VERSION "HNNBNNNYNNNNNNNNNNNNNNNNNNNNNNNNNNNNNNNNNN/4/%%%/4/'%**4NNN///"

NS_ :

BS_:

BU_: Aero_LB AFS_MLB Airbag_B8 BCM1_B8 Gateway_B8 Getriebe_AL551_651_B8 Getriebe_AL551_Q5_Hybrid Getriebe_SL_LB Lift_MLB_LB LWR_MLB Magnetic_Ride_LB Motor_MLB_AU48_AU416_Diesel Motor_MLB_B8_Q5_Otto Motor_MLB_Q5_Hybrid Niveau_LB Airbag_D4 BMS_Hybrid Daempfer_MLB EPB_MLB ESP Gateway Getriebe_AL551_951_D4_C7 Getriebe_AL551_Hybrid_D4_C7 Getriebe_DL382_MLB Getriebe_DL501_MLB Getriebe_VL381_MLB LEH_Hybrid LWS_D4 Motor2_MLB_D4_C7 Motor_MLB_AU64_AU57_Diesel Motor_MLB_BY_Otto Motor_MLB_C7_PHEV Motor_MLB_D4_C7_Hybrid Motor_MLB_D4_C7_Otto QSP SAK SAK2 SCR_MLB SCU

BO_ 3221225472 VECTOR__INDEPENDENT_SIG_MSG: 0 Vector__XXX
 SG_ AGA_Charisma_FahrPr : 0|4@1+ (1,0) [0|15] "" Vector__XXX
 SG_ AGA_Charisma_Status : 0|2@1+ (1,0) [0|3] "" Vector__XXX
 SG_ AGA_Verstaerker_Mute : 0|1@1+ (1,0) [0|1] "" Vector__XXX
 SG_ TPS_Airbag_Data : 0|56@1+ (1,0) [0|7.20575940379279E+016] "" Vector__XXX

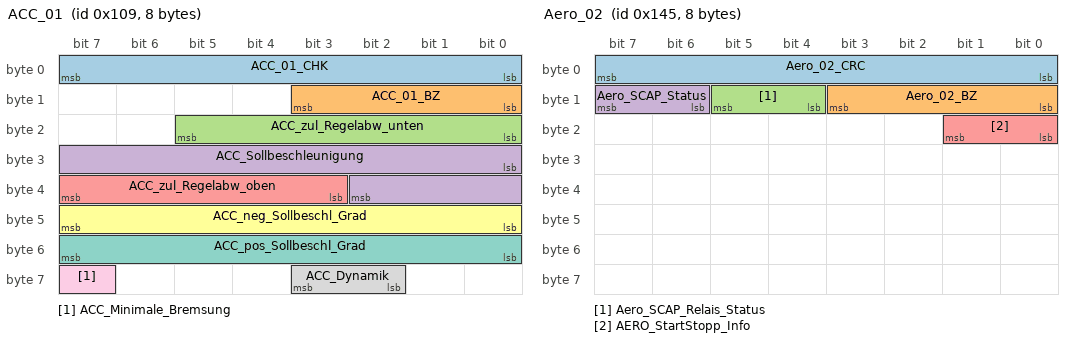
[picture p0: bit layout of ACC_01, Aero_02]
BO_ 265 ACC_01: 8 Gateway_B8
 SG_ ACC_01_CHK : 0|8@1+ (1,0) [0|255] ""  Magnetic_Ride_LB,Motor_MLB_AU48_AU416_Diesel,Motor_MLB_B8_Q5_Otto,Motor_MLB_Q5_Hybrid
 SG_ ACC_01_BZ : 8|4@1+ (1,0) [0|15] ""  Magnetic_Ride_LB,Motor_MLB_AU48_AU416_Diesel,Motor_MLB_B8_Q5_Otto,Motor_MLB_Q5_Hybrid
 SG_ ACC_zul_Regelabw_unten : 16|6@1+ (0.024,0) [0|1.512] "Unit_MeterPerSeconSquar"  Motor_MLB_AU48_AU416_Diesel,Motor_MLB_B8_Q5_Otto,Motor_MLB_Q5_Hybrid
 SG_ ACC_Sollbeschleunigung : 24|11@1+ (0.005,-7.22) [-7.22|3.01] "Unit_MeterPerSeconSquar"  Magnetic_Ride_LB,Motor_MLB_AU48_AU416_Diesel,Motor_MLB_B8_Q5_Otto,Motor_MLB_Q5_Hybrid
 SG_ ACC_zul_Regelabw_oben : 35|5@1+ (0.0625,0) [0|1.9375] "Unit_MeterPerSeconSquar"  Motor_MLB_AU48_AU416_Diesel,Motor_MLB_B8_Q5_Otto,Motor_MLB_Q5_Hybrid
 SG_ ACC_neg_Sollbeschl_Grad : 40|8@1+ (0.05,0) [0|12.7] "Unit_MeterPerCubicSecon"  Motor_MLB_AU48_AU416_Diesel,Motor_MLB_B8_Q5_Otto,Motor_MLB_Q5_Hybrid
 SG_ ACC_pos_Sollbeschl_Grad : 48|8@1+ (0.05,0) [0|12.7] "Unit_MeterPerCubicSecon"  Motor_MLB_AU48_AU416_Diesel,Motor_MLB_B8_Q5_Otto,Motor_MLB_Q5_Hybrid
 SG_ ACC_Dynamik : 58|2@1+ (1,0) [0|3] ""  Motor_MLB_AU48_AU416_Diesel,Motor_MLB_B8_Q5_Otto,Motor_MLB_Q5_Hybrid
 SG_ ACC_Minimale_Bremsung : 63|1@1+ (1,0) [0|1] ""  Motor_MLB_AU48_AU416_Diesel,Motor_MLB_B8_Q5_Otto,Motor_MLB_Q5_Hybrid

BO_ 1415 Aero_01: 8 Aero_LB
 SG_ Aero_01_CRC : 0|8@1+ (1,0) [0|255] ""  Gateway_B8
 SG_ Aero_01_BZ : 8|4@1+ (1,0) [0|15] ""  Gateway_B8
 SG_ Aero_Luftklappe_links_Status : 12|2@1+ (1,0) [0|3] ""  Gateway_B8
 SG_ Aero_Luftklappe_rechts_Status : 14|2@1+ (1,0) [0|3] ""  Gateway_B8
 SG_ Aero_Frontspoiler_Status : 16|3@1+ (1,0) [0|7] ""  Gateway_B8
 SG_ Aero_Heckspoiler_Status : 19|3@1+ (1,0) [0|7] ""  Gateway_B8
 SG_ Aero_SCU_Luefter_Status : 22|2@1+ (1,0) [0|3] ""  Gateway_B8
 SG_ Aero_Unterdruckpumpe_Status : 24|2@1+ (1,0) [0|3] ""  Gateway_B8
 SG_ Aero_Kamera_Kuehlung_Status : 26|1@1+ (1,0) [0|1] ""  Gateway_B8
 SG_ Aero_EBCS : 27|1@1+ (1,0) [0|1] ""  Gateway_B8
 SG_ Aero_Hardtop_Links_Status : 28|2@1+ (1,0) [0|3] ""  Gateway_B8
 SG_ Aero_Hardtop_Rechts_Status : 30|2@1+ (1,0) [0|3] ""  Gateway_B8
 SG_ Aero_Max_Performance : 32|2@1+ (1,0) [0|3] ""  Gateway_B8
 SG_ Aero_SCAP_Text : 34|2@1+ (1,0) [0|3] ""  Gateway_B8
 SG_ Aero_Frontklappe : 36|1@1+ (1,0) [0|1] ""  Gateway_B8
 SG_ AERO_St_LED_HSpoiler : 37|2@1+ (1,0) [0|3] ""  Gateway_B8
 SG_ Aero_Sp_IstPos : 39|3@1+ (1,0) [0|7] ""  Gateway_B8
 SG_ AERO_W_SpoilerInfo : 42|3@1+ (1,0) [0|7] ""  Gateway_B8
 SG_ Aero_KD_Fehler : 63|1@1+ (1,0) [0|1] ""  Gateway_B8

BO_ 325 Aero_02: 8 Aero_LB
 SG_ Aero_02_CRC : 0|8@1+ (1,0) [0|255] ""  Motor_MLB_B8_Q5_Otto
 SG_ Aero_02_BZ : 8|4@1+ (1,0) [0|15] ""  Motor_MLB_B8_Q5_Otto
 SG_ Aero_SCAP_Relais_Status : 12|2@1+ (1,0) [0|3] ""  Motor_MLB_B8_Q5_Otto
 SG_ Aero_SCAP_Status : 14|2@1+ (1,0) [0|3] ""  Motor_MLB_B8_Q5_Otto
 SG_ AERO_StartStopp_Info : 16|2@1+ (1,0) [0|3] ""  Motor_MLB_B8_Q5_Otto

BO_ 867 Blinkmodi_01: 4 Gateway_B8
 SG_ BM_ZV_auf : 0|1@1+ (1,0) [0|1] "" Vector__XXX
 SG_ BM_ZV_zu : 1|1@1+ (1,0) [0|1] "" Vector__XXX
 SG_ BM_DWA_ein : 2|1@1+ (1,0) [0|1] "" Vector__XXX
 SG_ BM_DWA_Alarm : 3|1@1+ (1,0) [0|1] "" Vector__XXX
 SG_ BM_Crash : 4|1@1+ (1,0) [0|1] "" Vector__XXX
 SG_ BM_Panik : 5|1@1+ (1,0) [0|1] "" Vector__XXX
 SG_ BM_Not_Bremsung : 6|1@1+ (1,0) [0|1] "" Vector__XXX
 SG_ BM_GDO : 7|1@1+ (1,0) [0|1] "" Vector__XXX
 SG_ BM_links : 8|1@1+ (1,0) [0|1] "" Vector__XXX
 SG_ BM_rechts : 9|1@1+ (1,0) [0|1] "" Vector__XXX
 SG_ BM_Warnblinken : 10|1@1+ (1,0) [0|1] "" Vector__XXX
 SG_ BM_Taxi_Notalarm : 12|1@1+ (1,0) [0|1] "" Vector__XXX
 SG_ BM_Telematik : 13|1@1+ (1,0) [0|1] "" Vector__XXX
 SG_ BM_HD_Oeffnung_angelernt : 14|1@1+ (1,0) [0|1] "" Vector__XXX
 SG_ BM_WBT_Beleuchtung : 15|1@1+ (1,0) [0|1] "" Vector__XXX
 SG_ Blinken_li_Fzg_Takt : 16|1@1+ (1,0) [0|1] "" Vector__XXX
 SG_ Blinken_re_Fzg_Takt : 17|1@1+ (1,0) [0|1] "" Vector__XXX
 SG_ Blinken_li_Kombi_Takt : 18|1@1+ (1,0) [0|1] "" Vector__XXX
 SG_ Blinken_re_Kombi_Takt : 19|1@1+ (1,0) [0|1] "" Vector__XXX
 SG_ BM_NBA_n_codiert_n_aktiv : 20|1@1+ (1,0) [0|1] "" Vector__XXX
 SG_ BM_NBA_Status : 21|2@1+ (1,0) [0|3] "" Vector__XXX
 SG_ Blinken_FWB_aktiv : 23|1@1+ (1,0) [0|1] "" Vector__XXX

BO_ 264 Fahrwerk_01: 8 Daempfer_MLB
 SG_ Fahrwerk_01_CHK : 0|8@1+ (1,0) [0|255] ""  BCM1_B8,Gateway_B8
 SG_ Fahrwerk_01_BZ : 8|4@1+ (1,0) [0|15] ""  BCM1_B8,Gateway_B8
 SG_ FA_Hoehenwerte_kalibriert M : 12|1@1+ (1,0) [0|1] ""  AFS_MLB,BCM1_B8,Gateway_B8,LWR_MLB
 SG_ FA_ESP_Zuschaltung : 13|1@1+ (1,0) [0|1] ""  Gateway_B8
 SG_ FA_Hoehenwert_VL_00 m0 : 16|8@1+ (1,-127) [-127|126] "Unit_MilliMeter"  AFS_MLB,BCM1_B8,Gateway_B8,LWR_MLB
 SG_ FA_Hoehenwert_VL_01 m1 : 16|8@1+ (0.4,0) [0|100] "Unit_PerCent"  AFS_MLB,BCM1_B8,Gateway_B8,LWR_MLB
 SG_ FA_Hoehenwert_VR_00 m0 : 24|8@1+ (1,-127) [-127|126] "Unit_MilliMeter"  AFS_MLB,BCM1_B8,Gateway_B8,LWR_MLB
 SG_ FA_Hoehenwert_VR_01 m1 : 24|8@1+ (0.4,0) [0|100] "Unit_PerCent"  AFS_MLB,BCM1_B8,Gateway_B8,LWR_MLB
 SG_ FA_Hoehenwert_HL_00 m0 : 32|8@1+ (1,-127) [-127|126] "Unit_MilliMeter"  AFS_MLB,BCM1_B8,Gateway_B8,LWR_MLB
 SG_ FA_Hoehenwert_HL_01 m1 : 32|8@1+ (0.4,0) [0|100] "Unit_PerCent"  AFS_MLB,BCM1_B8,Gateway_B8,LWR_MLB
 SG_ FA_Hoehenwert_HR_00 m0 : 40|8@1+ (1,-127) [-127|126] "Unit_MilliMeter"  AFS_MLB,BCM1_B8,Gateway_B8,LWR_MLB
 SG_ FA_Hoehenwert_HR_01 m1 : 40|8@1+ (0.4,0) [0|100] "Unit_PerCent"  AFS_MLB,BCM1_B8,Gateway_B8,LWR_MLB

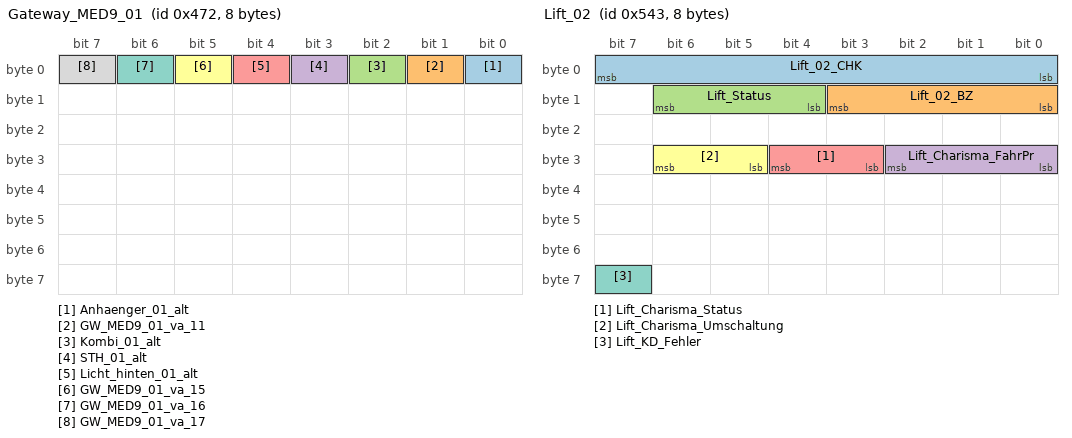
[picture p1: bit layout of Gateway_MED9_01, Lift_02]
BO_ 1138 Gateway_MED9_01: 8 Gateway_B8
 SG_ Anhaenger_01_alt : 0|1@1+ (1,0) [0|1] "" Vector__XXX
 SG_ GW_MED9_01_va_11 : 1|1@1+ (1,0) [0|1] "" Vector__XXX
 SG_ Kombi_01_alt : 2|1@1+ (1,0) [0|1] "" Vector__XXX
 SG_ STH_01_alt : 3|1@1+ (1,0) [0|1] "" Vector__XXX
 SG_ Licht_hinten_01_alt : 4|1@1+ (1,0) [0|1] "" Vector__XXX
 SG_ GW_MED9_01_va_15 : 5|1@1+ (1,0) [0|1] "" Vector__XXX
 SG_ GW_MED9_01_va_16 : 6|1@1+ (1,0) [0|1] "" Vector__XXX
 SG_ GW_MED9_01_va_17 : 7|1@1+ (1,0) [0|1] "" Vector__XXX

BO_ 1906 ISO_Daempfer_Req: 8 Gateway_B8
 SG_ ISO_Daempfer_Req_Data : 0|64@1+ (1,0) [0|1.84467440737096E+019] ""  Magnetic_Ride_LB

BO_ 2012 ISO_Daempfer_Resp: 8 Magnetic_Ride_LB
 SG_ ISO_Daempfer_Resp_Data : 0|64@1+ (1,0) [0|1.84467440737096E+019] ""  Gateway_B8

BO_ 1876 ISO_LWRAFS_Req: 8 Gateway_B8
 SG_ ISO_LWRAFS_Req_Data : 0|64@1+ (1,0) [0|1.84467440737096E+019] ""  LWR_MLB

BO_ 1982 ISO_LWRAFS_Resp: 8 LWR_MLB
 SG_ ISO_LWRAFS_Resp_Data : 0|64@1+ (1,0) [0|1.84467440737096E+019] ""  Gateway_B8

BO_ 2019 ISO_OBD_02_Req: 8 Gateway_B8
 SG_ ISO_OBD_02_Req_Data : 0|64@1+ (1,0) [0|1.84467440737096E+019] "" Vector__XXX

BO_ 2027 ISO_OBD_02_Resp: 8 Vector__XXX
 SG_ ISO_OBD_02_Resp_Data : 0|64@1+ (1,0) [0|1.84467440737096E+019] ""  Gateway_B8

BO_ 2023 ISO_OBD_06_Req: 8 Gateway_B8
 SG_ ISO_OBD_06_Req_Data : 0|64@1+ (1,0) [0|1.84467440737096E+019] "" Vector__XXX

BO_ 2031 ISO_OBD_06_Resp: 8 Vector__XXX
 SG_ ISO_OBD_06_Resp_Data : 0|64@1+ (1,0) [0|1.84467440737096E+019] ""  Gateway_B8

BO_ 1347 Lift_02: 8 Lift_MLB_LB
 SG_ Lift_02_CHK : 0|8@1+ (1,0) [0|255] ""  Gateway_B8
 SG_ Lift_02_BZ : 8|4@1+ (1,0) [0|15] ""  Gateway_B8
 SG_ Lift_Status : 12|3@1+ (1,0) [0|7] ""  Gateway_B8
 SG_ Lift_Charisma_FahrPr : 24|3@1+ (1,0) [0|7] ""  Gateway_B8
 SG_ Lift_Charisma_Status : 27|2@1+ (1,0) [0|3] ""  Gateway_B8
 SG_ Lift_Charisma_Umschaltung : 29|2@1+ (1,0) [0|3] ""  Gateway_B8
 SG_ Lift_KD_Fehler : 63|1@1+ (1,0) [0|1] ""  Gateway_B8

BO_ 917 LWR_AFS_01: 8 AFS_MLB
 SG_ AFS_Abbiegelicht_li_Anf : 0|1@1+ (1,0) [0|1] ""  Gateway_B8
 SG_ AFS_Abbiegelicht_re_Anf : 1|1@1+ (1,0) [0|1] ""  Gateway_B8
 SG_ AFS_Abbiegelicht_Dimm_Anf : 2|1@1+ (1,0) [0|1] ""  Gateway_B8
 SG_ AFS_Verfuegbarkeit_GLW : 3|1@1+ (1,0) [0|1] ""  Gateway_B8
 SG_ AFS_Status_adaptive_LV : 4|1@1+ (1,0) [0|1] ""  Gateway_B8
 SG_ AFS_Fernlicht_li_defekt : 5|1@1+ (1,0) [0|1] ""  Gateway_B8
 SG_ AFS_Fernlicht_re_defekt : 6|1@1+ (1,0) [0|1] ""  Gateway_B8
 SG_ AFS_Fernlicht_Status : 7|1@1+ (1,0) [0|1] ""  Gateway_B8
 SG_ LWR_AFS_01_BZ : 8|4@1+ (1,0) [0|15] ""  Gateway_B8
 SG_ AFS_Lampe : 12|1@1+ (1,0) [0|1] ""  Gateway_B8
 SG_ LWR_Lampe : 13|1@1+ (1,0) [0|1] ""  Gateway_B8
 SG_ AFS_Fehlertext : 14|1@1+ (1,0) [0|1] ""  Gateway_B8
 SG_ AFS_LED_Blinkmode : 15|1@1+ (1,0) [0|1] ""  Gateway_B8
 SG_ LWR_Touristenmodus_aktiv : 16|1@1+ (1,0) [0|1] ""  Gateway_B8
 SG_ AFS_Charisma_FahrPr : 17|3@1+ (1,0) [0|7] ""  Gateway_B8
 SG_ AFS_Charisma_Status : 20|2@1+ (1,0) [0|3] ""  Gateway_B8
 SG_ AFS_Charisma_Umschaltung : 22|2@1+ (1,0) [0|3] ""  Gateway_B8
 SG_ AFS_Allwetterlicht : 24|1@1+ (1,0) [0|1] ""  Gateway_B8
 SG_ LWR_Touristenmodus_verbaut : 25|1@1+ (1,0) [0|1] ""  Gateway_B8
 SG_ AFS_adaptive_LV_verbaut : 26|1@1+ (1,0) [0|1] ""  Gateway_B8
 SG_ LWR_Reisemodus_Texte : 27|2@1+ (1,0) [0|3] ""  Gateway_B8
 SG_ GLW_Sensor_blockiert : 29|1@1+ (1,0) [0|1] ""  Gateway_B8
 SG_ LWR_Pos_Schrittmotor : 32|8@1+ (0.4,0) [0|100] "Unit_PerCent"  Gateway_B8
 SG_ LWR_Hoehenwert_VL : 40|8@1+ (1,-127) [-127|126] ""  Gateway_B8
 SG_ LWR_Hoehenwert_HL : 48|8@1+ (1,-127) [-127|126] ""  Gateway_B8
 SG_ AFS_Ersatzlicht_Links : 56|1@1+ (1,0) [0|1] ""  Gateway_B8
 SG_ AFS_Ersatzlicht_Rechts : 57|1@1+ (1,0) [0|1] ""  Gateway_B8
 SG_ LWR_AFS_Grundeinstellung : 58|1@1+ (1,0) [0|1] ""  Gateway_B8
 SG_ LWR_AFS_Parametrisierung : 59|1@1+ (1,0) [0|1] ""  Gateway_B8
 SG_ LWR_Initialisierungslauf : 60|1@1+ (1,0) [0|1] ""  Gateway_B8
 SG_ LWR_Sicherheitsposition : 61|1@1+ (1,0) [0|1] ""  Gateway_B8
 SG_ LWR_Modus : 62|1@1+ (1,0) [0|1] ""  Gateway_B8
 SG_ LWR_KD_Fehler : 63|1@1+ (1,0) [0|1] ""  Gateway_B8

BO_ 1759 NMH_Aero: 7 Aero_LB
 SG_ NMH_Aero_Start_1 : 0|1@1+ (1,0) [0|1] ""  Aero_LB,Getriebe_AL551_651_B8,Getriebe_AL551_Q5_Hybrid,Getriebe_SL_LB,Motor_MLB_AU48_AU416_Diesel,Motor_MLB_B8_Q5_Otto,Motor_MLB_Q5_Hybrid
 SG_ NMH_Aero_Start_2 : 1|1@1+ (1,0) [0|1] "" Vector__XXX
 SG_ NMH_Aero_Normal_Mode_1 : 2|1@1+ (1,0) [0|1] "" Vector__XXX
 SG_ NMH_Aero_Normal_Mode_2 : 3|1@1+ (1,0) [0|1] "" Vector__XXX
 SG_ NMH_Aero_Car_WakeUp : 6|1@1+ (1,0) [0|1] ""  Gateway_B8
 SG_ NMH_Aero_Per_WakeUp : 8|5@1+ (1,0) [0|31] "" Vector__XXX
 SG_ NMH_Aero_Fkt_WakeUp : 13|3@1+ (1,0) [0|7] "" Vector__XXX
 SG_ NMH_Aero_Klemme_15 : 16|1@1+ (1,0) [0|1] "" Vector__XXX
 SG_ NMH_Aero_Diagnose : 17|1@1+ (1,0) [0|1] "" Vector__XXX
 SG_ NMH_Aero_MindestAktivZeit : 18|1@1+ (1,0) [0|1] "" Vector__XXX
 SG_ NMH_Aero_NL_Datem_EEPROM : 24|1@1+ (1,0) [0|1] "" Vector__XXX
 SG_ NMH_Aero_Signalfehler : 32|1@1+ (1,0) [0|1] "" Vector__XXX
 SG_ NMH_Aero_TimeOut_Fehler : 33|1@1+ (1,0) [0|1] "" Vector__XXX
 SG_ NMH_Aero_CAN_Diag_deaktiv : 34|1@1+ (1,0) [0|1] "" Vector__XXX
 SG_ NMH_Aero_KompSchutz : 35|1@1+ (1,0) [0|1] "" Vector__XXX
 SG_ NMH_Aero_Mute_Mode : 36|1@1+ (1,0) [0|1] "" Vector__XXX
 SG_ NMH_Aero_Transport_Mode : 37|1@1+ (1,0) [0|1] "" Vector__XXX
 SG_ NMH_Aero_Abschaltstufe_aktiv : 38|1@1+ (1,0) [0|1] "" Vector__XXX
 SG_ NMH_Aero_Busfehler : 39|1@1+ (1,0) [0|1] "" Vector__XXX
 SG_ NMH_Aero_Lokalaktiv : 48|1@1+ (1,0) [0|1] ""  Gateway_B8
 SG_ NMH_Aero_Subsystemaktiv : 49|1@1+ (1,0) [0|1] ""  Gateway_B8

BO_ 1193 TPD_Aerodynamik_01: 8 Gateway_B8
 SG_ TPD_Aerodynamik_Data_1 : 0|64@1+ (1,0) [0|1.84467440737096E+019] ""  Aero_LB

BO_ 1300 TPD_Airbag_02: 8 Gateway_B8
 SG_ TPD_Airbag_Data_2 : 0|64@1+ (1,0) [0|1.84467440737096E+019] ""  Airbag_B8

BO_ 1215 TPD_Gateway_01: 8 Airbag_B8
 SG_ TPD_Gateway_Data_1 : 0|64@1+ (1,0) [0|1.84467440737096E+019] ""  Gateway_B8

BO_ 1303 TPD_Gateway_02: 8 Airbag_B8
 SG_ TPD_Gateway_Data_2 : 0|64@1+ (1,0) [0|1.84467440737096E+019] ""  Gateway_B8

BO_ 1186 TPD_Getriebe_01: 8 Gateway_B8
 SG_ TPD_Getriebe_Data_1 : 0|64@1+ (1,0) [0|1.84467440737096E+019] ""  Getriebe_SL_LB

BO_ 1194 TPD_Lifting: 8 Gateway_B8
 SG_ TPD_Lifting_Data : 0|64@1+ (1,0) [0|1.84467440737096E+019] ""  Lift_MLB_LB

BO_ 1190 TPD_LWR_AFS_01: 8 Gateway_B8
 SG_ TPD_LWR_AFS_Data_1 : 0|64@1+ (1,0) [0|1.84467440737096E+019] ""  AFS_MLB,LWR_MLB

BO_ 1185 TPD_Motor_01: 8 Gateway_B8
 SG_ TPD_Motor_Data_1 : 0|64@1+ (1,0) [0|1.84467440737096E+019] "" Vector__XXX

BO_ 1205 TPD_MotorS_01: 8 Gateway_B8
 SG_ TPD_MotorS_Data_1 : 0|64@1+ (1,0) [0|1.84467440737096E+019] "" Vector__XXX

BO_ 535 TPS_Aerodynamik: 7 Aero_LB
 SG_ TPS_Aerodynamik_Data : 0|56@1+ (1,0) [0|7.20575940379279E+016] ""  Gateway_B8

BO_ 543 TPS_Gateway: 7 Gateway_B8
 SG_ TPS_Gateway_Data : 0|56@1+ (1,0) [0|7.20575940379279E+016] ""  Airbag_B8

BO_ 514 TPS_Getriebe: 7 Getriebe_DL501_MLB
 SG_ TPS_Getriebe_Data : 0|56@1+ (1,0) [0|7.20575940379279E+016] ""  Gateway_B8

BO_ 539 TPS_Lifting: 7 Lift_MLB_LB
 SG_ TPS_Lifting_Data : 0|56@1+ (1,0) [0|7.20575940379279E+016] ""  Gateway_B8

BO_ 518 TPS_LWR_AFS: 7 AFS_MLB
 SG_ TPS_LWR_AFS_Data : 0|56@1+ (1,0) [0|7.20575940379279E+016] ""  Gateway_B8

BO_ 513 TPS_Motor: 7 Vector__XXX
 SG_ TPS_Motor_Data : 0|56@1+ (1,0) [0|7.20575940379279E+016] ""  Gateway_B8

BO_ 533 TPS_MotorS: 7 Vector__XXX
 SG_ TPS_MotorS_Data : 0|56@1+ (1,0) [0|7.20575940379279E+016] ""  Gateway_B8

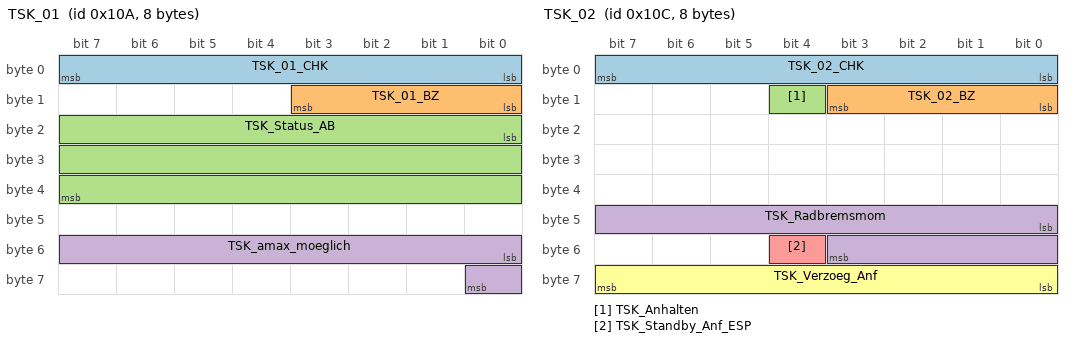
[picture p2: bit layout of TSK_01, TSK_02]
BO_ 266 TSK_01: 8 Motor_MLB_AU48_AU416_Diesel
 SG_ TSK_01_CHK : 0|8@1+ (1,0) [0|255] ""  Gateway_B8
 SG_ TSK_01_BZ : 8|4@1+ (1,0) [0|15] ""  Gateway_B8
 SG_ TSK_Status_AB : 16|24@1+ (1,0) [0|16777215] ""  Gateway_B8
 SG_ TSK_amax_moeglich : 48|9@1+ (0.024,-2.016) [-2.016|10.224] "Unit_MeterPerSeconSquar"  Gateway_B8

BO_ 268 TSK_02: 8 Motor_MLB_AU48_AU416_Diesel
 SG_ TSK_02_CHK : 0|8@1+ (1,0) [0|255] ""  Gateway_B8,Getriebe_AL551_651_B8,Getriebe_AL551_Q5_Hybrid,Getriebe_SL_LB
 SG_ TSK_02_BZ : 8|4@1+ (1,0) [0|15] ""  Gateway_B8,Getriebe_AL551_651_B8,Getriebe_AL551_Q5_Hybrid,Getriebe_SL_LB
 SG_ TSK_Anhalten : 12|1@1+ (1,0) [0|1] ""  Gateway_B8
 SG_ TSK_Radbremsmom : 40|12@1+ (8,0) [0|32760] "Unit_NewtoMeter"  Gateway_B8
 SG_ TSK_Standby_Anf_ESP : 52|1@1+ (1,0) [0|1] ""  Gateway_B8
 SG_ TSK_Verzoeg_Anf : 56|8@1+ (0.024,-3.984) [-3.984|2.112] "Unit_MeterPerSeconSquar"  Gateway_B8

BO_ 983 VSG_01: 8 Aero_LB
 SG_ VS_FH_FT_hoch : 0|1@1+ (1,0) [0|1] ""  Gateway_B8
 SG_ VS_FH_FT_Langhub : 1|1@1+ (1,0) [0|1] ""  Gateway_B8
 SG_ VS_FH_BT_hoch : 2|1@1+ (1,0) [0|1] ""  Gateway_B8
 SG_ VS_FH_BT_Langhub : 3|1@1+ (1,0) [0|1] ""  Gateway_B8
 SG_ VS_FH_HL_hoch : 4|1@1+ (1,0) [0|1] ""  Gateway_B8
 SG_ VS_FH_HL_Langhub : 5|1@1+ (1,0) [0|1] ""  Gateway_B8
 SG_ VS_FH_HR_hoch : 6|1@1+ (1,0) [0|1] ""  Gateway_B8
 SG_ VS_FH_HR_Langhub : 7|1@1+ (1,0) [0|1] ""  Gateway_B8
 SG_ VS_KD_Fehler : 15|1@1+ (1,0) [0|1] ""  Gateway_B8
 SG_ VS_VD_zu_ver : 16|1@1+ (1,0) [0|1] ""  Gateway_B8
 SG_ VS_VD_entriegelt : 17|1@1+ (1,0) [0|1] ""  Gateway_B8
 SG_ VS_VD_offen_ver : 18|1@1+ (1,0) [0|1] ""  Gateway_B8
 SG_ VS_VD_Zwischenposition : 19|1@1+ (1,0) [0|1] ""  Gateway_B8
 SG_ VS_VD_Bew_auf : 20|1@1+ (1,0) [0|1] ""  Gateway_B8
 SG_ VS_VD_Bew_zu : 21|1@1+ (1,0) [0|1] ""  Gateway_B8
 SG_ VS_Verdeck_Anf : 22|1@1+ (1,0) [0|1] ""  Gateway_B8
 SG_ VS_Hardtop : 23|1@1+ (1,0) [0|1] ""  Gateway_B8
 SG_ VS_VD_Fehler : 24|1@1+ (1,0) [0|1] ""  Gateway_B8
 SG_ VS_Lampe_Blk : 25|1@1+ (1,0) [0|1] ""  Gateway_B8
 SG_ VS_Buzzer : 26|1@1+ (1,0) [0|1] ""  Gateway_B8
 SG_ VS_HD_sperren : 27|1@1+ (1,0) [0|1] ""  Gateway_B8
 SG_ VS_HHS_enable : 28|1@1+ (1,0) [0|1] ""  Gateway_B8
 SG_ VS_VVW_unten : 29|1@1+ (1,0) [0|1] ""  Gateway_B8
 SG_ VSG_FT_FH_BT_ManHoch : 32|1@1+ (1,0) [0|1] ""  Gateway_B8
 SG_ VSG_FT_FH_BT_AutoHoch : 33|1@1+ (1,0) [0|1] ""  Gateway_B8
 SG_ VSG_FT_FH_BT_ManTief : 34|1@1+ (1,0) [0|1] ""  Gateway_B8
 SG_ VSG_FT_FH_BT_AutoTief : 35|1@1+ (1,0) [0|1] ""  Gateway_B8
 SG_ VSG_FT_FH_FT_ManHoch : 36|1@1+ (1,0) [0|1] ""  Gateway_B8
 SG_ VSG_FT_FH_FT_AutoHoch : 37|1@1+ (1,0) [0|1] ""  Gateway_B8
 SG_ VSG_FT_FH_FT_ManTief : 38|1@1+ (1,0) [0|1] ""  Gateway_B8
 SG_ VSG_FT_FH_FT_AutoTief : 39|1@1+ (1,0) [0|1] ""  Gateway_B8
 SG_ VSG_FT_FH_HL_ManHoch : 40|1@1+ (1,0) [0|1] ""  Gateway_B8
 SG_ VSG_FT_FH_HL_AutoHoch : 41|1@1+ (1,0) [0|1] ""  Gateway_B8
 SG_ VSG_FT_FH_HL_ManTief : 42|1@1+ (1,0) [0|1] ""  Gateway_B8
 SG_ VSG_FT_FH_HL_AutoTief : 43|1@1+ (1,0) [0|1] ""  Gateway_B8
 SG_ VSG_FT_FH_HR_ManHoch : 44|1@1+ (1,0) [0|1] ""  Gateway_B8
 SG_ VSG_FT_FH_HR_AutoHoch : 45|1@1+ (1,0) [0|1] ""  Gateway_B8
 SG_ VSG_FT_FH_HR_ManTief : 46|1@1+ (1,0) [0|1] ""  Gateway_B8
 SG_ VSG_FT_FH_HR_AutoTief : 47|1@1+ (1,0) [0|1] ""  Gateway_B8
 SG_ VS_Texte : 56|8@1+ (1,0) [0|255] ""  Gateway_B8

BO_ 912 WBA_01: 4 Getriebe_AL551_651_B8
 SG_ WBA_WH_Sleep_ACK_alt m0 : 7|1@1+ (1,0) [0|1] ""  Gateway_B8
 SG_ GE_Warnung_Auto_N_LB m0 : 18|1@1+ (1,0) [0|1] ""  Gateway_B8
 SG_ WBA_GE_Fastshift m0 : 19|1@1+ (1,0) [0|1] ""  Gateway_B8
 SG_ WBA_GE_Textmeldungen m0 : 21|3@1+ (1,0) [0|7] ""  Gateway_B8

BO_ 2617009149 XCP_Daempfer_CRO_01: 8 Vector__XXX
 SG_ XCP_Daempfer_CRO_01_Data : 0|64@1+ (1,0) [0|1.84467440737096E+019] ""  Magnetic_Ride_LB,Niveau_LB

BO_ 2617009150 XCP_Daempfer_DTO_01: 8 Daempfer_MLB
 SG_ XCP_Daempfer_DTO_01_Data : 0|64@1+ (1,0) [0|1.84467440737096E+019] "" Vector__XXX

BO_ 2617167360 XCP_Lift_CRO_01: 8 Vector__XXX
 SG_ XCP_Lift_CRO_01_Data : 0|64@1+ (1,0) [0|1.84467440737096E+019] ""  Lift_MLB_LB

BO_ 2617167361 XCP_Lift_DTO_01: 8 Lift_MLB_LB
 SG_ XCP_Lift_DTO_01_Data : 0|64@1+ (1,0) [0|1.84467440737096E+019] "" Vector__XXX

BO_ 269 ACC_05: 8 Gateway
 SG_ ACC_05_CHK : 0|8@1+ (1,0) [0|255] ""  EPB_MLB,Getriebe_AL551_951_D4_C7,Getriebe_AL551_Hybrid_D4_C7,Getriebe_DL382_MLB,Getriebe_DL501_MLB,Getriebe_VL381_MLB,Motor_MLB_AU64_AU57_Diesel,Motor_MLB_BY_Otto,Motor_MLB_C7_PHEV,Motor_MLB_D4_C7_Hybrid,Motor_MLB_D4_C7_Otto
 SG_ ACC_05_BZ : 8|4@1+ (1,0) [0|15] ""  EPB_MLB,Getriebe_AL551_951_D4_C7,Getriebe_AL551_Hybrid_D4_C7,Getriebe_DL382_MLB,Getriebe_DL501_MLB,Getriebe_VL381_MLB,Motor_MLB_AU64_AU57_Diesel,Motor_MLB_BY_Otto,Motor_MLB_C7_PHEV,Motor_MLB_D4_C7_Hybrid,Motor_MLB_D4_C7_Otto
 SG_ ACC_Freigabe_Momentenanf : 12|1@1+ (1,0) [0|1] ""  Motor_MLB_AU64_AU57_Diesel,Motor_MLB_BY_Otto,Motor_MLB_C7_PHEV,Motor_MLB_D4_C7_Hybrid,Motor_MLB_D4_C7_Otto
 SG_ ACC_Freigabe_Verzanf : 13|1@1+ (1,0) [0|1] ""  Getriebe_AL551_951_D4_C7,Getriebe_AL551_Hybrid_D4_C7,Getriebe_DL382_MLB,Getriebe_DL501_MLB,Getriebe_VL381_MLB
 SG_ ACC_Getriebestellung_P : 14|1@1+ (1,0) [0|1] ""  Getriebe_AL551_951_D4_C7,Getriebe_AL551_Hybrid_D4_C7,Getriebe_DL382_MLB,Getriebe_DL501_MLB,Getriebe_VL381_MLB
 SG_ ACC_limitierte_Anfahrdyn : 15|1@1+ (1,0) [0|1] ""  Motor_MLB_AU64_AU57_Diesel,Motor_MLB_BY_Otto,Motor_MLB_C7_PHEV,Motor_MLB_D4_C7_Hybrid,Motor_MLB_D4_C7_Otto
 SG_ ACC_Momentenanforderung : 16|10@1+ (1,0) [0|1021] ""  Getriebe_DL382_MLB,Getriebe_DL501_MLB,Motor_MLB_AU64_AU57_Diesel,Motor_MLB_BY_Otto,Motor_MLB_C7_PHEV,Motor_MLB_D4_C7_Hybrid,Motor_MLB_D4_C7_Otto
 SG_ ACC_zul_Regelabw : 26|6@1+ (0.024,0) [0|1.512] "Unit_MeterPerSeconSquar"  Getriebe_AL551_951_D4_C7,Getriebe_AL551_Hybrid_D4_C7,Getriebe_DL382_MLB,Getriebe_DL501_MLB,Getriebe_VL381_MLB
 SG_ ACC_Verz_anf : 32|11@1+ (0.005,-7.22) [-7.22|3.015] "Unit_MeterPerSeconSquar" Vector__XXX
 SG_ ACC_Loeseanforderung : 43|1@1+ (1,0) [0|1] "" Vector__XXX
 SG_ ACC_StartStopp_Info : 44|2@1+ (1,0) [0|3] ""  EPB_MLB,Motor_MLB_AU64_AU57_Diesel,Motor_MLB_BY_Otto,Motor_MLB_C7_PHEV,Motor_MLB_D4_C7_Hybrid,Motor_MLB_D4_C7_Otto
 SG_ ACC_Segelveto : 46|1@1+ (1,0) [0|1] "" Vector__XXX
 SG_ ACC_Vorbefuellung_Bremsanlage : 47|1@1+ (1,0) [0|1] "" Vector__XXX
 SG_ ACC_ax_Getriebe : 48|9@1+ (0.024,-2.016) [-2.016|10.248] "Unit_MeterPerSeconSquar"  Getriebe_AL551_951_D4_C7,Getriebe_AL551_Hybrid_D4_C7,Getriebe_DL382_MLB,Getriebe_DL501_MLB,Getriebe_VL381_MLB
 SG_ ACC_Status_ACC : 57|3@1+ (1,0) [0|7] ""  EPB_MLB,Motor_MLB_AU64_AU57_Diesel,Motor_MLB_BY_Otto,Motor_MLB_C7_PHEV,Motor_MLB_D4_C7_Hybrid,Motor_MLB_D4_C7_Otto
 SG_ ACC_Betaetigung_EPB : 60|1@1+ (1,0) [0|1] ""  EPB_MLB,Motor_MLB_AU64_AU57_Diesel,Motor_MLB_BY_Otto,Motor_MLB_C7_PHEV,Motor_MLB_D4_C7_Hybrid,Motor_MLB_D4_C7_Otto
 SG_ ACC_Beeinflussung_ESP : 61|1@1+ (1,0) [0|1] "" Vector__XXX
 SG_ ACC_Anhalten : 62|1@1+ (1,0) [0|1] ""  EPB_MLB,Getriebe_DL382_MLB,Getriebe_DL501_MLB
 SG_ ACC_KD_Fehler : 63|1@1+ (1,0) [0|1] "" Vector__XXX

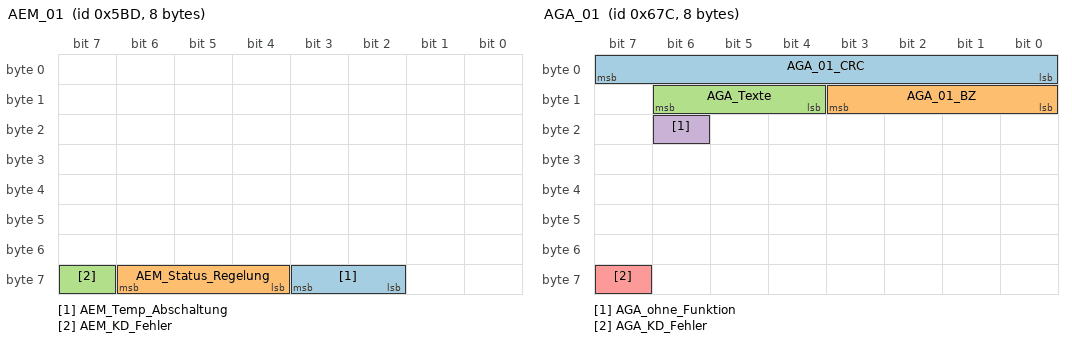
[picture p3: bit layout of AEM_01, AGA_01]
BO_ 1469 AEM_01: 8 Gateway
 SG_ AEM_Temp_Abschaltung : 58|2@1+ (1,0) [0|3] ""  Motor_MLB_BY_Otto,Motor_MLB_C7_PHEV,Motor_MLB_D4_C7_Hybrid,Motor_MLB_D4_C7_Otto
 SG_ AEM_Status_Regelung : 60|3@1+ (1,0) [0|7] ""  Motor_MLB_BY_Otto,Motor_MLB_C7_PHEV,Motor_MLB_D4_C7_Hybrid,Motor_MLB_D4_C7_Otto
 SG_ AEM_KD_Fehler : 63|1@1+ (1,0) [0|1] "" Vector__XXX

BO_ 1660 AGA_01: 8 SAK2
 SG_ AGA_01_CRC : 0|8@1+ (1,0) [0|255] "" Vector__XXX
 SG_ AGA_01_BZ : 8|4@1+ (1,0) [0|15] "" Vector__XXX
 SG_ AGA_Texte : 12|3@1+ (1,0) [0|7] "" Vector__XXX
 SG_ AGA_ohne_Funktion : 22|1@1+ (1,0) [0|1] "" Vector__XXX
 SG_ AGA_KD_Fehler : 63|1@1+ (1,0) [0|1] ""  Gateway

BO_ 64 Airbag_01: 8 Airbag_D4
 SG_ Airbag_01_CHK : 0|8@1+ (1,0) [0|255] ""  BMS_Hybrid,Gateway,LEH_Hybrid,Motor_MLB_AU64_AU57_Diesel,Motor_MLB_BY_Otto,Motor_MLB_C7_PHEV,Motor_MLB_D4_C7_Hybrid,Motor_MLB_D4_C7_Otto
 SG_ Airbag_01_BZ : 8|4@1+ (1,0) [0|15] ""  BMS_Hybrid,Gateway,LEH_Hybrid,Motor_MLB_AU64_AU57_Diesel,Motor_MLB_BY_Otto,Motor_MLB_C7_PHEV,Motor_MLB_D4_C7_Hybrid,Motor_MLB_D4_C7_Otto
 SG_ AB_RGS_Anst : 12|4@1+ (1,0) [0|15] ""  Gateway
 SG_ AB_Front_Crash : 16|1@1+ (1,0) [0|1] ""  Gateway
 SG_ AB_Heck_Crash : 17|1@1+ (1,0) [0|1] ""  Gateway
 SG_ AB_SF_Crash : 18|1@1+ (1,0) [0|1] ""  Gateway
 SG_ AB_SB_Crash : 19|1@1+ (1,0) [0|1] ""  Gateway
 SG_ AB_Rollover_Crash : 20|1@1+ (1,0) [0|1] ""  Gateway
 SG_ AB_Crash_Int : 21|3@1+ (1,0) [0|7] ""  BMS_Hybrid,Gateway,Motor_MLB_AU64_AU57_Diesel,Motor_MLB_BY_Otto,Motor_MLB_C7_PHEV,Motor_MLB_D4_C7_Hybrid,Motor_MLB_D4_C7_Otto
 SG_ AB_Lampe : 24|1@1+ (1,0) [0|1] ""  Gateway
 SG_ AB_Deaktiviert : 25|1@1+ (1,0) [0|1] ""  Gateway
 SG_ AB_VB_deaktiviert : 26|1@1+ (1,0) [0|1] ""  Gateway
 SG_ AB_Systemfehler : 27|1@1+ (1,0) [0|1] ""  BMS_Hybrid,Gateway,LEH_Hybrid
 SG_ AB_Diagnose : 28|1@1+ (1,0) [0|1] ""  Gateway
 SG_ AB_Stellgliedtest : 29|1@1+ (1,0) [0|1] ""  BMS_Hybrid,Gateway,Motor_MLB_AU64_AU57_Diesel,Motor_MLB_BY_Otto,Motor_MLB_C7_PHEV,Motor_MLB_D4_C7_Hybrid,Motor_MLB_D4_C7_Otto
 SG_ AB_Erh_Auf_VB : 30|2@1+ (1,0) [0|3] ""  Gateway
 SG_ AB_Gurtwarn_VF : 32|1@1+ (1,0) [0|1] ""  Gateway
 SG_ AB_Gurtwarn_VB : 33|1@1+ (1,0) [0|1] ""  Gateway
 SG_ AB_Anzeige_Fussg : 34|2@1+ (1,0) [0|3] ""  Gateway
 SG_ AB_Texte_AKS : 36|2@1+ (1,0) [0|3] ""  Gateway
 SG_ AB_PAO_Leuchte_Anf : 38|1@1+ (1,0) [0|1] ""  Gateway
 SG_ AB_MKB_gueltig : 39|1@1+ (1,0) [0|1] ""  Gateway
 SG_ AB_MKB_Anforderung : 40|1@1+ (1,0) [0|1] ""  Gateway
 SG_ AB_Versorgungsspannung : 41|1@1+ (1,0) [0|1] ""  Gateway
 SG_ AB_Deaktivierung_HV : 42|3@1+ (1,0) [0|7] ""  BMS_Hybrid,Gateway,LEH_Hybrid,Motor_MLB_C7_PHEV,Motor_MLB_D4_C7_Hybrid
 SG_ AB_EDR_Trigger : 45|2@1+ (1,0) [0|3] ""  Gateway
 SG_ AB_KD_Fehler : 63|1@1+ (1,0) [0|1] ""  Gateway

BO_ 1312 Airbag_02: 8 Airbag_D4
 SG_ AB_Belegung_VB : 26|2@1+ (1,0) [0|3] ""  Gateway
 SG_ AB_Abschaltanf_SIH_BF : 28|1@1+ (1,0) [0|1] ""  Gateway
 SG_ SC_PAO_Schriftzug_Anf : 30|2@1+ (1,0) [0|3] ""  Gateway
 SG_ SC_PAO_ON_Anf : 32|2@1+ (1,0) [0|3] ""  Gateway
 SG_ SC_PAO_OFF_Anf : 34|2@1+ (1,0) [0|3] ""  Gateway
 SG_ AB_Crashschwere : 36|3@1+ (1,0) [0|7] ""  Gateway
 SG_ AB_Anforderung_USM : 39|1@1+ (1,0) [0|1] ""  Gateway
 SG_ AB_Gurtschloss_FA : 40|2@1+ (1,0) [0|3] ""  EPB_MLB,Gateway,Motor_MLB_AU64_AU57_Diesel,Motor_MLB_BY_Otto,Motor_MLB_C7_PHEV,Motor_MLB_D4_C7_Hybrid,Motor_MLB_D4_C7_Otto
 SG_ AB_Gurtschloss_BF : 42|2@1+ (1,0) [0|3] ""  Gateway
 SG_ AB_Gurtschloss_Reihe2_FA : 44|2@1+ (1,0) [0|3] ""  Gateway
 SG_ AB_Gurtschloss_Reihe2_MI : 46|2@1+ (1,0) [0|3] ""  Gateway
 SG_ AB_Gurtschloss_Reihe2_BF : 48|2@1+ (1,0) [0|3] ""  Gateway
 SG_ AB_Gurtschloss_Reihe3_FA : 50|2@1+ (1,0) [0|3] ""  Gateway
 SG_ AB_Gurtschloss_Reihe3_MI : 52|2@1+ (1,0) [0|3] ""  Gateway
 SG_ AB_Gurtschloss_Reihe3_BF : 54|2@1+ (1,0) [0|3] ""  Gateway
 SG_ AB_Sitzpos_Sens_FA : 56|2@1+ (1,0) [0|3] ""  Gateway
 SG_ AB_Sitzpos_Sens_BF : 58|2@1+ (1,0) [0|3] ""  Gateway
 SG_ AB_Trefferlage : 60|4@1+ (1,0) [0|15] ""  Gateway

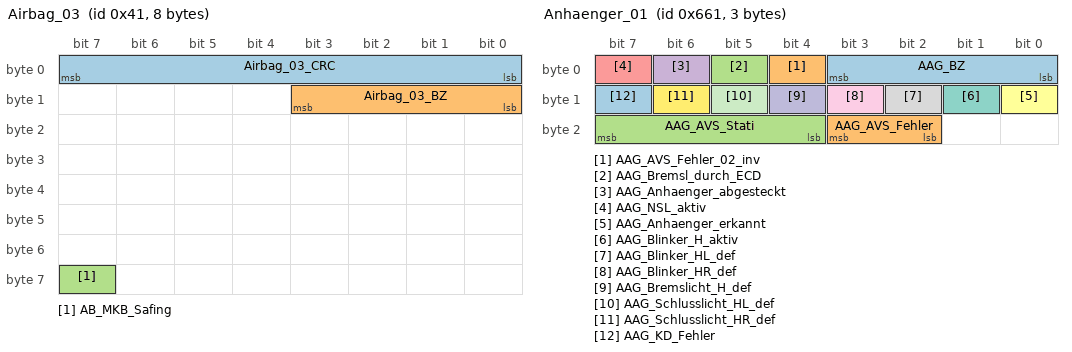
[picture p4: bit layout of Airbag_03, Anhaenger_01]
BO_ 65 Airbag_03: 8 Airbag_D4
 SG_ Airbag_03_CRC : 0|8@1+ (1,0) [0|255] ""  Gateway
 SG_ Airbag_03_BZ : 8|4@1+ (1,0) [0|15] ""  Gateway
 SG_ AB_MKB_Safing : 63|1@1+ (1,0) [0|1] ""  Gateway

BO_ 1633 Anhaenger_01: 3 Gateway
 SG_ AAG_BZ : 0|4@1+ (1,0) [0|15] ""  Getriebe_AL551_951_D4_C7,Getriebe_AL551_Hybrid_D4_C7,Motor_MLB_AU64_AU57_Diesel,Motor_MLB_BY_Otto,Motor_MLB_C7_PHEV,Motor_MLB_D4_C7_Hybrid,Motor_MLB_D4_C7_Otto
 SG_ AAG_AVS_Fehler_02_inv : 4|1@1+ (1,0) [0|1] "" Vector__XXX
 SG_ AAG_Bremsl_durch_ECD : 5|1@1+ (1,0) [0|1] ""  Motor_MLB_AU64_AU57_Diesel,Motor_MLB_BY_Otto,Motor_MLB_C7_PHEV,Motor_MLB_D4_C7_Hybrid,Motor_MLB_D4_C7_Otto
 SG_ AAG_Anhaenger_abgesteckt : 6|1@1+ (1,0) [0|1] "" Vector__XXX
 SG_ AAG_NSL_aktiv : 7|1@1+ (1,0) [0|1] "" Vector__XXX
 SG_ AAG_Anhaenger_erkannt : 8|1@1+ (1,0) [0|1] ""  Getriebe_AL551_951_D4_C7,Getriebe_AL551_Hybrid_D4_C7,Getriebe_DL382_MLB,Getriebe_DL501_MLB,Getriebe_VL381_MLB,Motor_MLB_AU64_AU57_Diesel,Motor_MLB_BY_Otto,Motor_MLB_C7_PHEV,Motor_MLB_D4_C7_Hybrid,Motor_MLB_D4_C7_Otto
 SG_ AAG_Blinker_H_aktiv : 9|1@1+ (1,0) [0|1] "" Vector__XXX
 SG_ AAG_Blinker_HL_def : 10|1@1+ (1,0) [0|1] "" Vector__XXX
 SG_ AAG_Blinker_HR_def : 11|1@1+ (1,0) [0|1] "" Vector__XXX
 SG_ AAG_Bremslicht_H_def : 12|1@1+ (1,0) [0|1] ""  Motor_MLB_AU64_AU57_Diesel,Motor_MLB_BY_Otto,Motor_MLB_C7_PHEV,Motor_MLB_D4_C7_Hybrid,Motor_MLB_D4_C7_Otto
 SG_ AAG_Schlusslicht_HL_def : 13|1@1+ (1,0) [0|1] "" Vector__XXX
 SG_ AAG_Schlusslicht_HR_def : 14|1@1+ (1,0) [0|1] "" Vector__XXX
 SG_ AAG_KD_Fehler : 15|1@1+ (1,0) [0|1] "" Vector__XXX
 SG_ AAG_AVS_Fehler : 18|2@1+ (1,0) [0|3] "" Vector__XXX
 SG_ AAG_AVS_Stati : 20|4@1+ (1,0) [0|15] "" Vector__XXX

BO_ 1542 BAP_ASG_06: 8 Gateway
 SG_ BAP_06_Header : 0|8@1+ (1,0) [0|255] ""  Daempfer_MLB,Motor_MLB_C7_PHEV,Motor_MLB_D4_C7_Hybrid

BO_ 1599 BAP_Debug_Cmd: 8 Vector__XXX
 SG_ BAP_Debug_Cmd : 0|16@1+ (1,0) [0|65535] ""  Daempfer_MLB,Motor_MLB_C7_PHEV,Motor_MLB_D4_C7_Hybrid

BO_ 1598 BAP_Debug_Data: 8 Daempfer_MLB
 SG_ BAP_Debug_Data : 0|64@1+ (1,0) [0|1.84467440737096E+019] "" Vector__XXX

BO_ 1558 BAP_Hybrid: 8 Motor_MLB_C7_PHEV
 SG_ BAP_16_Header : 0|8@1+ (1,0) [0|255] ""  Gateway

BO_ 1580 BAP_Luftfeder: 8 Daempfer_MLB
 SG_ BAP_2C_Header : 0|8@1+ (1,0) [0|255] ""  Gateway

BO_ 1409 BCM2_02: 8 Gateway
 SG_ BCM_FH_Freigabe : 0|1@1+ (1,0) [0|1] "" Vector__XXX
 SG_ BCM_Komfortfkt_Freigabe : 1|1@1+ (1,0) [0|1] "" Vector__XXX
 SG_ BCM_HSK_Freigabe : 2|1@1+ (1,0) [0|1] "" Vector__XXX
 SG_ BCM_Verdeck_Freigabe : 3|1@1+ (1,0) [0|1] "" Vector__XXX
 SG_ BCM2_Status_Timer_KL15_Abschalt : 4|1@1+ (1,0) [0|1] "" Vector__XXX
 SG_ BCM2_Anford_AbschaltfreigabeKL15 : 5|1@1+ (1,0) [0|1] "" Vector__XXX
 SG_ BCM2_Unterdr_Zuendungsmeldung : 6|1@1+ (1,0) [0|1] "" Vector__XXX
 SG_ BCM2_KL15_Absch_FT : 7|1@1+ (1,0) [0|1] "" Vector__XXX
 SG_ ZV_ist_Zustand_verfuegbar : 8|1@1+ (1,0) [0|1] "" Vector__XXX
 SG_ BCM2_P_verriegelt : 9|1@1+ (1,0) [0|1] "" Vector__XXX
 SG_ ZV_verriegelt_intern_ist : 10|1@1+ (1,0) [0|1] "" Vector__XXX
 SG_ ZV_verriegelt_extern_ist : 11|1@1+ (1,0) [0|1] "" Vector__XXX
 SG_ ZV_verriegelt_intern_soll : 12|1@1+ (1,0) [0|1] "" Vector__XXX
 SG_ ZV_verriegelt_extern_soll : 13|1@1+ (1,0) [0|1] ""  Motor_MLB_C7_PHEV
 SG_ ZV_gesafet_extern_ist : 14|1@1+ (1,0) [0|1] "" Vector__XXX
 SG_ ZV_gesafet_extern_soll : 15|1@1+ (1,0) [0|1] "" Vector__XXX
 SG_ ZV_FT_offen : 16|1@1+ (1,0) [0|1] "" Vector__XXX
 SG_ ZV_BT_offen : 17|1@1+ (1,0) [0|1] "" Vector__XXX
 SG_ ZV_HL_offen : 18|1@1+ (1,0) [0|1] "" Vector__XXX
 SG_ ZV_HR_offen : 19|1@1+ (1,0) [0|1] "" Vector__XXX
 SG_ ZV_HD_offen : 20|1@1+ (1,0) [0|1] "" Vector__XXX
 SG_ ZV_Turen_HD_zu : 21|1@1+ (1,0) [0|1] "" Vector__XXX
 SG_ ZV_Einzeltuerentriegelung : 22|1@1+ (1,0) [0|1] "" Vector__XXX
 SG_ ZV_Heckeinzelentriegelung : 23|1@1+ (1,0) [0|1] "" Vector__XXX
 SG_ BCM_ValetTaster_Fkts_LED : 24|1@1+ (1,0) [0|1] "" Vector__XXX
 SG_ BCM_HHS_aktiv : 25|1@1+ (1,0) [0|1] "" Vector__XXX
 SG_ BCM_Spg_Hzg_Ein : 26|1@1+ (1,0) [0|1] "" Vector__XXX
 SG_ ZV_HS_offen : 27|1@1+ (1,0) [0|1] "" Vector__XXX
 SG_ ZZH_Endlage_oben : 28|1@1+ (1,0) [0|1] "" Vector__XXX
 SG_ ZZH_Endlage_unten : 29|1@1+ (1,0) [0|1] "" Vector__XXX
 SG_ ZZH_Endlage_unplausibel : 30|1@1+ (1,0) [0|1] "" Vector__XXX
 SG_ BCM2_KD_Fehler : 31|1@1+ (1,0) [0|1] "" Vector__XXX
 SG_ NGS_aktiv : 32|1@1+ (1,0) [0|1] "" Vector__XXX
 SG_ IRUE_aktiv : 33|1@1+ (1,0) [0|1] "" Vector__XXX
 SG_ DWA_aktiv : 34|1@1+ (1,0) [0|1] "" Vector__XXX
 SG_ Komp_Schutz_aktiv : 35|1@1+ (1,0) [0|1] "" Vector__XXX
 SG_ NGS_Taster_Fkts_LED : 36|1@1+ (1,0) [0|1] "" Vector__XXX
 SG_ IRUE_Taster_Fkts_LED : 37|1@1+ (1,0) [0|1] "" Vector__XXX
 SG_ HD_Drehfalle_S1 : 38|1@1+ (1,0) [0|1] "" Vector__XXX
 SG_ HD_Sperrklinke_S2 : 39|1@1+ (1,0) [0|1] "" Vector__XXX
 SG_ BCM_Verbau_Heckrollo : 40|1@1+ (1,0) [0|1] "" Vector__XXX
 SG_ BCM2_EZS_gedrueckt : 41|1@1+ (1,0) [0|1] "" Vector__XXX
 SG_ BCM2_SST_gedrueckt : 42|1@1+ (1,0) [0|1] "" Vector__XXX
 SG_ LIM_alt : 43|1@1+ (1,0) [0|1] "" Vector__XXX
 SG_ LIM_Innenbeleuchtung_V_aktiv : 44|1@1+ (1,0) [0|1] "" Vector__XXX
 SG_ LIM_Innenbeleuchtung_aktiv : 45|1@1+ (1,0) [0|1] "" Vector__XXX
 SG_ LIM_Taster_Rollolicht_hl : 46|1@1+ (1,0) [0|1] "" Vector__XXX
 SG_ LIM_Taster_Rollolicht_hr : 47|1@1+ (1,0) [0|1] "" Vector__XXX
 SG_ BCM_Sperrklinke_FT : 48|1@1+ (1,0) [0|1] ""  EPB_MLB
 SG_ LIM_Taster_Rollolicht_V : 49|1@1+ (1,0) [0|1] "" Vector__XXX
 SG_ BCM_Tankwunsch : 50|2@1+ (1,0) [0|3] "" Vector__XXX
 SG_ ZV_Tankklappe_offen : 52|1@1+ (1,0) [0|1] ""  Motor_MLB_C7_PHEV
 SG_ BCM_Tankklappensteller_Fehler : 53|1@1+ (1,0) [0|1] ""  Motor_MLB_C7_PHEV
 SG_ KST_Fahrer_Hinweise : 56|3@1+ (1,0) [0|7] "" Vector__XXX
 SG_ KST_Warn_P1_ZST_def : 59|1@1+ (1,0) [0|1] "" Vector__XXX
 SG_ KST_Warn_P2_ZST_def : 60|1@1+ (1,0) [0|1] "" Vector__XXX
 SG_ KST_Prio_Warn_03 : 61|1@1+ (1,0) [0|1] "" Vector__XXX
 SG_ KST_Prio_Warn_04 : 62|1@1+ (1,0) [0|1] "" Vector__XXX
 SG_ KST_Prio_Warn_05 : 63|1@1+ (1,0) [0|1] "" Vector__XXX

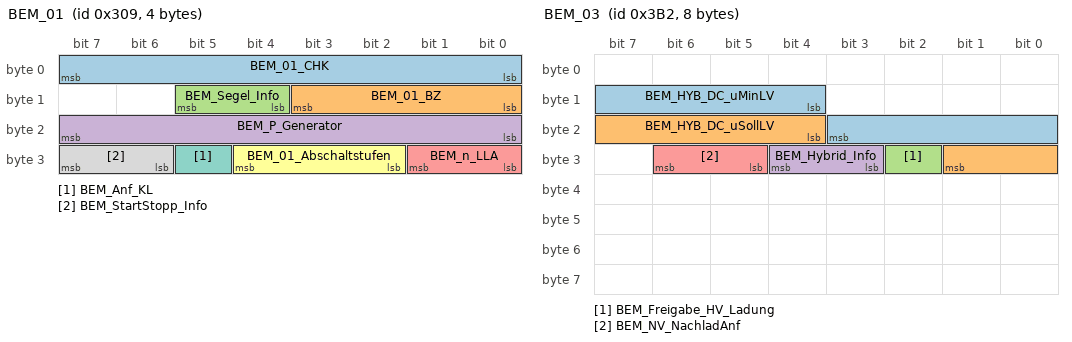
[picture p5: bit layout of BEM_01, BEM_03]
BO_ 777 BEM_01: 4 Gateway
 SG_ BEM_01_CHK : 0|8@1+ (1,0) [0|255] ""  Motor_MLB_AU64_AU57_Diesel,Motor_MLB_BY_Otto,Motor_MLB_C7_PHEV,Motor_MLB_D4_C7_Hybrid,Motor_MLB_D4_C7_Otto
 SG_ BEM_01_BZ : 8|4@1+ (1,0) [0|15] ""  Motor_MLB_AU64_AU57_Diesel,Motor_MLB_BY_Otto,Motor_MLB_C7_PHEV,Motor_MLB_D4_C7_Hybrid,Motor_MLB_D4_C7_Otto
 SG_ BEM_Segel_Info : 12|2@1+ (1,0) [0|3] ""  Getriebe_AL551_951_D4_C7,Getriebe_DL382_MLB,Getriebe_DL501_MLB
 SG_ BEM_P_Generator : 16|8@1+ (50,0) [0|12700] "Unit_Watt"  Motor_MLB_AU64_AU57_Diesel,Motor_MLB_BY_Otto,Motor_MLB_C7_PHEV,Motor_MLB_D4_C7_Hybrid,Motor_MLB_D4_C7_Otto
 SG_ BEM_n_LLA : 24|2@1+ (1,0) [0|3] ""  Motor_MLB_AU64_AU57_Diesel,Motor_MLB_BY_Otto,Motor_MLB_C7_PHEV,Motor_MLB_D4_C7_Hybrid,Motor_MLB_D4_C7_Otto
 SG_ BEM_01_Abschaltstufen : 26|3@1+ (1,0) [0|7] "" Vector__XXX
 SG_ BEM_Anf_KL : 29|1@1+ (1,0) [0|1] ""  Motor_MLB_AU64_AU57_Diesel,Motor_MLB_BY_Otto,Motor_MLB_C7_PHEV,Motor_MLB_D4_C7_Hybrid,Motor_MLB_D4_C7_Otto
 SG_ BEM_StartStopp_Info : 30|2@1+ (1,0) [0|3] ""  Motor_MLB_AU64_AU57_Diesel,Motor_MLB_BY_Otto,Motor_MLB_C7_PHEV,Motor_MLB_D4_C7_Hybrid,Motor_MLB_D4_C7_Otto

BO_ 1635 BEM_02: 8 Gateway
 SG_ BEM_02_Abschaltstufen : 0|3@1+ (1,0) [0|7] "" Vector__XXX
 SG_ BEM_STH_Zielzeit : 3|4@1+ (5,0) [0|60] "Unit_Minut" Vector__XXX
 SG_ BEM_MMI_Vorwarnung : 7|1@1+ (1,0) [0|1] "" Vector__XXX
 SG_ BEM_HL_Kontingentierung : 8|6@1+ (50,-1000) [-1000|1000] "Unit_Watt" Vector__XXX
 SG_ NVEM_Anf_SD_schalten : 15|1@1+ (1,0) [0|1] "" Vector__XXX
 SG_ BEM_Generatordiagnose : 16|2@1+ (1,0) [0|3] "" Vector__XXX
 SG_ BEM_Red_Innengeblaese : 18|2@1+ (1,0) [0|3] "" Vector__XXX
 SG_ BEM_STH_Einschaltverbot : 20|1@1+ (1,0) [0|1] "" Vector__XXX
 SG_ BEM_HL_Regelung_Status : 21|3@1+ (1,0) [0|7] ""  Motor_MLB_AU64_AU57_Diesel
 SG_ BEM_Ladezustand : 24|4@1+ (10,0) [0|100] "Unit_PerCent" Vector__XXX
 SG_ BEM_Batteriediagnose : 28|3@1+ (1,0) [0|7] "" Vector__XXX
 SG_ MIB_Stromsparmodus : 31|1@1+ (1,0) [0|1] "" Vector__XXX
 SG_ BEM_DFM : 32|5@1+ (3.225,0.025) [0.025|100] "" Vector__XXX
 SG_ BEM_REK_aktiv : 37|1@1+ (1,0) [0|1] ""  Motor_MLB_AU64_AU57_Diesel
 SG_ BEM_EMLIN_ungueltig : 38|1@1+ (1,0) [0|1] "" Vector__XXX
 SG_ BEM_Batt_Ab : 39|1@1+ (1,0) [0|1] "" Vector__XXX
 SG_ BEM_UBDM : 40|8@1+ (0.05,5) [5.05|17.7] "Unit_Volt" Vector__XXX
 SG_ BEM_UGenSoll : 48|6@1+ (0.1,10.6) [10.6|16] "Unit_Volt" Vector__XXX
 SG_ BEM_Anf_KL15_schalten : 54|2@1+ (1,0) [0|3] "" Vector__XXX

BO_ 946 BEM_03: 8 Gateway
 SG_ BEM_HYB_DC_uMinLV : 12|8@1+ (0.1,0) [0|25.3] "Unit_Volt"  LEH_Hybrid
 SG_ BEM_HYB_DC_uSollLV : 20|6@1+ (0.1,10.6) [10.6|16] "Unit_Volt"  LEH_Hybrid
 SG_ BEM_Freigabe_HV_Ladung : 26|1@1+ (1,0) [0|1] ""  Motor_MLB_C7_PHEV,Motor_MLB_D4_C7_Hybrid
 SG_ BEM_Hybrid_Info : 27|2@1+ (1,0) [0|3] ""  Motor_MLB_C7_PHEV,Motor_MLB_D4_C7_Hybrid
 SG_ BEM_NV_NachladAnf : 29|2@1+ (1,0) [0|3] "" Vector__XXX

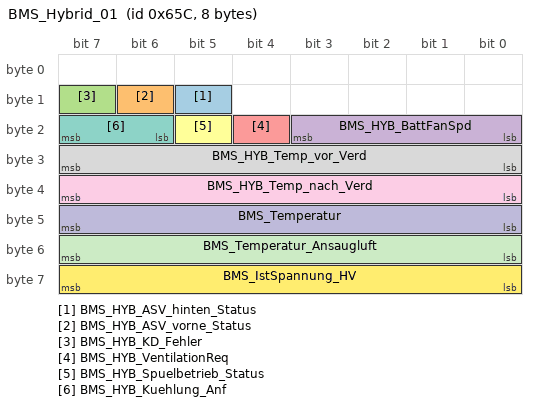
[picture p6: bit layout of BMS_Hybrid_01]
BO_ 1628 BMS_Hybrid_01: 8 BMS_Hybrid
 SG_ BMS_HYB_ASV_hinten_Status : 13|1@1+ (1,0) [0|1] ""  Gateway
 SG_ BMS_HYB_ASV_vorne_Status : 14|1@1+ (1,0) [0|1] ""  Gateway
 SG_ BMS_HYB_KD_Fehler : 15|1@1+ (1,0) [0|1] ""  Gateway
 SG_ BMS_HYB_BattFanSpd : 16|4@1+ (10,0) [0|100] "Unit_PerCent"  Gateway
 SG_ BMS_HYB_VentilationReq : 20|1@1+ (1,0) [0|1] ""  Gateway
 SG_ BMS_HYB_Spuelbetrieb_Status : 21|1@1+ (1,0) [0|1] ""  Gateway
 SG_ BMS_HYB_Kuehlung_Anf : 22|2@1+ (1,0) [0|3] ""  Gateway
 SG_ BMS_HYB_Temp_vor_Verd : 24|8@1+ (0.5,-40) [-40|86.5] "Unit_DegreCelsi"  Gateway
 SG_ BMS_HYB_Temp_nach_Verd : 32|8@1+ (0.5,-40) [-40|86.5] "Unit_DegreCelsi"  Gateway
 SG_ BMS_Temperatur : 40|8@1+ (0.5,-40) [-40|86.5] "Unit_DegreCelsi"  Gateway
 SG_ BMS_Temperatur_Ansaugluft : 48|8@1+ (0.5,-40) [-40|86.5] "Unit_DegreCelsi"  Gateway
 SG_ BMS_IstSpannung_HV : 56|8@1+ (1,100) [100|350] "Unit_Volt"  Gateway

BO_ 2617239041 CCP_EMotor_01_DTO_01: 8 LEH_Hybrid
 SG_ CCP_LE_DTO_01_Data : 0|64@1+ (1,0) [0|1] "" Vector__XXX

BO_ 482 CCP_GE_CR0_01: 8 Gateway
 SG_ CCP_GE_CRO_01_Data : 0|64@1+ (1,0) [0|1] ""  Getriebe_AL551_951_D4_C7,Getriebe_AL551_Hybrid_D4_C7,Getriebe_DL382_MLB,Getriebe_DL501_MLB,Getriebe_VL381_MLB

BO_ 490 CCP_GE_DTO_01: 8 Vector__XXX
 SG_ CCP_GE_DTO_01_Data : 0|64@1+ (1,0) [0|1] ""  Gateway

BO_ 1666 CCP_LE_CRO_01: 8 Gateway
 SG_ CCP_LE_CRO_01_Data : 0|64@1+ (1,0) [0|1] ""  LEH_Hybrid

BO_ 480 CCP_MO_CRO_01: 8 Gateway
 SG_ CCP_MO_CRO_01_Data : 0|64@1+ (1,0) [0|1] ""  Motor_MLB_AU64_AU57_Diesel,Motor_MLB_BY_Otto,Motor_MLB_C7_PHEV,Motor_MLB_D4_C7_Hybrid,Motor_MLB_D4_C7_Otto

BO_ 2616986624 CCP_MO_CRO_02: 8 Vector__XXX
 SG_ CCP_MO_CRO_02_Data : 0|64@1+ (1,0) [0|1] ""  Motor_MLB_AU64_AU57_Diesel,Motor_MLB_BY_Otto,Motor_MLB_C7_PHEV,Motor_MLB_D4_C7_Hybrid,Motor_MLB_D4_C7_Otto

BO_ 488 CCP_MO_DTO_01: 8 Motor_MLB_AU64_AU57_Diesel
 SG_ CCP_MO_DTO_01_Data : 0|64@1+ (1,0) [0|1] ""  Gateway

BO_ 2616986625 CCP_MO_DTO_02: 8 Motor_MLB_AU64_AU57_Diesel
 SG_ CCP_MO_DTO_02_Data : 0|64@1+ (1,0) [0|1] "" Vector__XXX

BO_ 481 CCP_MOS_CRO_01: 8 Gateway
 SG_ CCP_MOS_CRO_01_Data : 0|64@1+ (1,0) [0|1] ""  Motor2_MLB_D4_C7

BO_ 2616986629 CCP_MOS_CRO_02: 8 Vector__XXX
 SG_ CCP_MOS_CRO_02_Data : 0|64@1+ (1,0) [0|1] ""  Motor2_MLB_D4_C7

BO_ 489 CCP_MOS_DTO_01: 8 Motor2_MLB_D4_C7
 SG_ CCP_MOS_DTO_01_Data : 0|64@1+ (1,0) [0|1] ""  Gateway

BO_ 2616986630 CCP_MOS_DTO_02: 8 Motor2_MLB_D4_C7
 SG_ CCP_MOS_DTO_02_Data : 0|64@1+ (1,0) [0|1] "" Vector__XXX

BO_ 2617189888 CCP_Soundaktor_Aussen_CRO_01: 8 Vector__XXX
 SG_ CCP_Soundaktor_Aussen_CRO_01_000 : 0|64@1+ (1,0) [0|1] ""  SAK2

BO_ 2617189889 CCP_Soundaktor_Aussen_DTO_01: 8 SAK2
 SG_ CCP_Soundaktor_Aussen_DTO_01_001 : 0|64@1+ (1,0) [0|1] "" Vector__XXX

BO_ 2617042432 CCP_Soundaktor_CRO_01: 8 Vector__XXX
 SG_ CCP_Soundaktor_CRO_01_Data : 0|64@1+ (1,0) [0|1.84467440737096E+019] ""  SAK

BO_TX_BU_ 917 : AFS_MLB,LWR_MLB;
BO_TX_BU_ 518 : AFS_MLB,LWR_MLB;
BO_TX_BU_ 266 : Motor_MLB_AU48_AU416_Diesel,Motor_MLB_B8_Q5_Otto,Motor_MLB_Q5_Hybrid;
BO_TX_BU_ 268 : Motor_MLB_AU48_AU416_Diesel,Motor_MLB_B8_Q5_Otto,Motor_MLB_Q5_Hybrid;
BO_TX_BU_ 912 : Getriebe_AL551_651_B8,Getriebe_AL551_Q5_Hybrid,Getriebe_SL_LB,Motor_MLB_AU48_AU416_Diesel,Motor_MLB_B8_Q5_Otto,Motor_MLB_Q5_Hybrid;
BO_TX_BU_ 2617009150 : Magnetic_Ride_LB,Niveau_LB;
BO_TX_BU_ 1598 : Daempfer_MLB,Motor_MLB_C7_PHEV,Motor_MLB_D4_C7_Hybrid;
BO_TX_BU_ 1558 : Motor_MLB_C7_PHEV,Motor_MLB_D4_C7_Hybrid;
BO_TX_BU_ 488 : Motor_MLB_AU64_AU57_Diesel,Motor_MLB_BY_Otto,Motor_MLB_C7_PHEV,Motor_MLB_D4_C7_Hybrid,Motor_MLB_D4_C7_Otto;
BO_TX_BU_ 2616986625 : Motor_MLB_AU64_AU57_Diesel,Motor_MLB_BY_Otto,Motor_MLB_C7_PHEV,Motor_MLB_D4_C7_Hybrid,Motor_MLB_D4_C7_Otto;

CM_ "D4_CAN_Antrieb_6.20.13F Generated by BUSNETNG 8.4.2";
CM_ BU_ Aero_LB "SG für Spoiler, Lufteinlässe und Motor-Lüfter für  für LB83x Murcielago NF
GFA";
CM_ BU_ AFS_MLB "B8";
CM_ BU_ Getriebe_AL551_651_B8 "Getriebesteuergerät im Stufenautomatik-Getriebe";
CM_ BU_ Getriebe_AL551_Q5_Hybrid "Getriebesteuergerät im Stufenautomatik-Getriebe im Hybrid";
CM_ BU_ Getriebe_SL_LB "SL750-7A Lamborghini für LB83x Murcielago NF";
CM_ BU_ Lift_MLB_LB "Lifting-Steuergerät für LB834 (MLB-B8)";
CM_ BU_ LWR_MLB "B8";
CM_ BU_ Magnetic_Ride_LB "Magnetic_Ride im LB834";
CM_ BU_ Motor_MLB_AU48_AU416_Diesel "MLB B8 Q5 Diesel";
CM_ BU_ Motor_MLB_B8_Q5_Otto "B8 und Q5 Otto";
CM_ BU_ Motor_MLB_Q5_Hybrid "Otto Motorsteuergerät im Q5 Hybrid";
CM_ BU_ Niveau_LB "Lifting & Dämpfer-SG für LB83x Murcielago NF";
CM_ BU_ BMS_Hybrid "MLB Q5h, D4h, C7h";
CM_ BU_ Daempfer_MLB "RS6 Quattro-Umfang CAN";
CM_ BU_ EPB_MLB "D4, C7, MSS, Ektirsche Parkbremse";
CM_ BU_ ESP "Audi_D4";
CM_ BU_ Gateway "_D4/C7/C7 PHEV

6xCAN	
1xFlexray 
1xMOST
2xLIN";
CM_ BU_ Getriebe_DL382_MLB "C7PA";
CM_ BU_ Getriebe_DL501_MLB "C7";
CM_ BU_ Getriebe_VL381_MLB "C7";
CM_ BU_ LWS_D4 "Lenkwinkelsensor (im SMLS integriert)";
CM_ BU_ Motor2_MLB_D4_C7 "Motor Slave D4";
CM_ BU_ Motor_MLB_AU64_AU57_Diesel "MLB D4 C7 Diesel";
CM_ BU_ Motor_MLB_BY_Otto "BY8x Otto";
CM_ BU_ Motor_MLB_C7_PHEV "Motorsteuergerät für Otto-Motoren mit PluginHybridumfang";
CM_ BU_ Motor_MLB_D4_C7_Hybrid "Motorsteuergerät für Otto-Motoren mit Hybridumfang";
CM_ BU_ Motor_MLB_D4_C7_Otto "Motorsteuergerät für Otto-Motoren im D4 C7";
CM_ BU_ QSP "Quattro-Sport";
CM_ BU_ SAK "MLB Soundaktuator (Innen)
Im RSE nicht mehr verbaut ab IS4";
CM_ BU_ SAK2 "MLB AktiveSoundAbgasanlage (Aussen)";
CM_ BU_ SCR_MLB "Reduktionsmittel Dosiersystem (Harnstoff) MLB C7
SelectivCatalyticReduction

Bock Dietrich I/EF-61 40838 ";
CM_ BU_ SCU "MLB (D4, C7, MSS) ohne B8/Q5";
CM_ BO_ 3221225472 "This is a message for not used signals, created by Vector CANdb++ DBC OLE DB Provider.";
CM_ SG_ 3221225472 AGA_Charisma_FahrPr "MLBevo: Aktuelles Fahrprogramm des Charisma-Teilnehmers (siehe Systemlastenheft Drive Select)
MQB: Istwert der Kennlinie (siehe Systemlastenheft MQB FPA)";
CM_ SG_ 3221225472 AGA_Charisma_Status "Rückmeldung an den Charisma-Master

Wert 0x3 ist nur für Fahrzeuge ab MQB relevant";
CM_ SG_ 3221225472 AGA_Verstaerker_Mute "Freischaltung Verstaerkerkanal";
CM_ SG_ 265 ACC_01_CHK "Berechnung siehe Lastenheft 'Kommunikationsabsicherung für FlexRay und CAN'
Endwerte siehe 'Kommunikationsabsicherung für FlexRay und CAN / Anhang C: Tabelle S-PDU Kennungen'";
CM_ SG_ 265 ACC_01_BZ "Zähler der von der Applikation inkrementiert wird";
CM_ SG_ 265 ACC_zul_Regelabw_unten "Anforderung an den Triebstrangkoordinator. Zulässiger Betrag der Abweichung zwischen angeforderter 'ACC_Sollbeschleunigung(_02)' und umzusetzender Sollbeschleunigung  im TSK. Im TSK wird, abhängig vom Arbeitspunkt die Toleranz und die Sollbeschleunigung f";
CM_ SG_ 265 ACC_Sollbeschleunigung "Anforderung an den Triebstrangkoordinator , eine 'ACC_Sollbeschleunigung' umzusetzen.";
CM_ SG_ 265 ACC_zul_Regelabw_oben "Anforderung an den Triebstrangkoordinator. Zulässiger Betrag der Abweichung zwischen angeforderter 'ACC_Sollbeschleunigung(_02)' und umzusetzender Sollbeschleunigung  im TSK. Im TSK wird, abhängig vom Arbeitspunkt die Toleranz und die Sollbeschleunigung f";
CM_ SG_ 265 ACC_neg_Sollbeschl_Grad "Empfehlung an den Triebstrangkoordinator , mit welchem betragsmäßig maximalen negativen Gradienten eine ACC-Anforderung 'ACC_Sollbeschleunigung' einzuregeln ist.";
CM_ SG_ 265 ACC_pos_Sollbeschl_Grad "Empfehlung an den Triebstrangkoordinator , mit welchem betragsmäßig maximalen positiven Gradienten eine ACC-Anforderung 'ACC_Sollbeschleunigung' einzuregeln ist.";
CM_ SG_ 265 ACC_Dynamik "Über dieses Signal wird dem TSK mitgeteilt, in welchem Fahrprogramm das ACC aktuell betrieben wird. Wird im TSK verwendet, u.a. um im Falle ACC im Handschalter beim Wiedereinkuppeln das Moment abh. vom Fahrprogramm mit unterschiedlichen Rampen hochzufahre";
CM_ SG_ 265 ACC_Minimale_Bremsung "Im Falle eines gesetzten Bits wird vom ACC dem TSK angezeigt, dass es sich im Resume_Suspend_Mode befindet. In diesem Mode darf der TSK keine ECD-Bremsung anfordern, unabhängig von der 'ACC_Sollbeschleunigungsanforderung'. Eine Fahrzeugverzögerung darf nu";
CM_ SG_ 1415 Aero_01_CRC "Für MLB:
'Berechnung siehe Lastenheft 'Kommunikationsabsicherung für FlexRay und CAN''

Ab MQB und MLBevo:
'Berechnung siehe Lastenheft 'End-to-End Kommunikationsabsicherung''

Endwerte siehe Begleitdokument 'S-PDU Kennungsfolgen'
";
CM_ SG_ 1415 Aero_Luftklappe_links_Status "Gibt den Status der linken Lufteinlassklappe an";
CM_ SG_ 1415 Aero_Luftklappe_rechts_Status "Gibt den Status der rechten Lufteinlassklappe an";
CM_ SG_ 1415 Aero_Frontspoiler_Status "Gibt den Status des Frontspoilers an";
CM_ SG_ 1415 Aero_Heckspoiler_Status "Gibt den Status des Heckspoilers an";
CM_ SG_ 1415 Aero_SCU_Luefter_Status "Status Lüfter für SCU";
CM_ SG_ 1415 Aero_Unterdruckpumpe_Status "Status der Unterdruckpunke für Bremskraftverstärker";
CM_ SG_ 1415 Aero_Kamera_Kuehlung_Status "Status Kamera_Kuehlung";
CM_ SG_ 1415 Aero_EBCS "Stand der Kuehlstrategie vom Motorraum (Status of Engine Bay Cooling strategy)";
CM_ SG_ 1415 Aero_Hardtop_Links_Status "Status des linken Hardtopteils";
CM_ SG_ 1415 Aero_Hardtop_Rechts_Status "Status des rechten Hardtopteils";
CM_ SG_ 1415 Aero_Max_Performance "Stand der 'Performance Strategie' vom Heckspoiler (Status of  Rear Wing Max Performance strategy)";
CM_ SG_ 1415 Aero_SCAP_Text "SuperCAP-Meldung für Kombi";
CM_ SG_ 1415 Aero_Frontklappe "Status of inner front bonnet handle
(Innenbetaetigung Kofferraum)";
CM_ SG_ 1415 AERO_St_LED_HSpoiler "Anzeige-LED im Spoilertaster";
CM_ SG_ 1415 Aero_Sp_IstPos "Ist-Position des Heckspoilers und der Frontdiffusoren";
CM_ SG_ 1415 AERO_W_SpoilerInfo "Infomeldungen im Kombiinstrument zum Zustand des Spoilersystems";
CM_ SG_ 325 Aero_02_CRC "Für MLB:
'Berechnung siehe Lastenheft 'Kommunikationsabsicherung für FlexRay und CAN''

Ab MQB und MLBevo:
'Berechnung siehe Lastenheft 'End-to-End Kommunikationsabsicherung''

Endwerte siehe Begleitdokument 'S-PDU Kennungsfolgen'";
CM_ SG_ 325 Aero_SCAP_Relais_Status "Super Cap Relais Stand(Feedback for the SCap relay status)";
CM_ SG_ 325 Aero_SCAP_Status "Motorstartfreigabe (Enable to MSG to allow the cranking )";
CM_ SG_ 325 AERO_StartStopp_Info "Freigabe bzw. Startanforderung für Start/Stopp";
CM_ BO_ 867 "Nur die Kombination des statischen und toggelnden Signals ergibt den Blinktakt für die Hell & Dunkelphase";
CM_ SG_ 867 BM_ZV_auf "Blinken bei ZV auf

";
CM_ SG_ 867 BM_ZV_zu "Blinken bei ZV zu

";
CM_ SG_ 867 BM_DWA_ein "Status Quittierungsblinken DWA";
CM_ SG_ 867 BM_DWA_Alarm "Status DWA-Alarmblinken
";
CM_ SG_ 867 BM_Crash "Status Crashblinken
";
CM_ SG_ 867 BM_Panik "Panikblinken
";
CM_ SG_ 867 BM_Not_Bremsung "Notbremsblinken

";
CM_ SG_ 867 BM_GDO "Blinken bei UGDO anlernen

";
CM_ SG_ 867 BM_links "Richtungsblinken links

";
CM_ SG_ 867 BM_rechts "Richtungsblinken rechts

";
CM_ SG_ 867 BM_Warnblinken "Warnblinken

";
CM_ SG_ 867 BM_Taxi_Notalarm "Blinken bei Taxi-Not-Alarm

";
CM_ SG_ 867 BM_Telematik "Telematikblinken
";
CM_ SG_ 867 BM_HD_Oeffnung_angelernt "Das HDSG fordert über das CAN Signal HDSG_01.HD_Rueckmeld_prog eine Blinkerquittierung beim BCM2 an.
Wenn die Geschwindigkeit kleiner einer vorgegebenen Schwelle (default 2km/h) ist wird das Signal BM_HD_Öffnung_angelernt versendet und die Blinkerquittie";
CM_ SG_ 867 BM_WBT_Beleuchtung "Aktivierung Warnblinktasterfunktionsbeleuchtung
Warnblinktasterfunktionsbeleuchtung soll aktiviert werden (statisch auf 1)";
CM_ SG_ 867 Blinken_li_Fzg_Takt "Fzg-Takt Blinker links

";
CM_ SG_ 867 Blinken_re_Fzg_Takt "Fzg-Takt Blinker rechts

";
CM_ SG_ 867 Blinken_li_Kombi_Takt "Kombi-Takt Blinker links

";
CM_ SG_ 867 Blinken_re_Kombi_Takt "Kombi-Takt Blinker rechts

";
CM_ SG_ 867 BM_NBA_n_codiert_n_aktiv "Notbremsanzeige nicht codiert/nicht aktiv (Fehler)";
CM_ SG_ 867 BM_NBA_Status "Notbremsanzeige Status nicht aktiv / BRL Dunkelphase / BRL Hellphase";
CM_ SG_ 867 Blinken_FWB_aktiv "Status freilaufendes Warnblinken
";
CM_ SG_ 264 Fahrwerk_01_CHK "Berechnung siehe Lastenheft 'Kommunikationsabsicherung für FlexRay und CAN'
Endwerte siehe 'Kommunikationsabsicherung für FlexRay und CAN / Anhang C: Tabelle S-PDU Kennungen'";
CM_ SG_ 264 FA_Hoehenwerte_kalibriert "Legt fest, wie die Höhensensorwerte interpretiert werden müssen. Umschaltung kalibrierte Höhenwerte / Rohsignale in Byte 3-6

Achtung:
Im AUDI B8 Konstante: 0x1. D.h. es werden nur Rohwerte bedient!
Im AUDI D4 Konstante: 0x0. D.h. es werden nur Millim";
CM_ SG_ 264 FA_ESP_Zuschaltung "Zwangsweise Aktivierung der ESP-Funktionalität wird angefordert auch bei Passivtastung";
CM_ SG_ 264 FA_Hoehenwert_VL_00 "Aktueller Höhenwert (kalibriert) Vorne Links; ungefiltertes Signal
Einheit, Offset und Faktor sind abhänig von 'FA_Hoehenwert_kalibriert'

Achtung:
Wird im AUDI B8 nicht bedient";
CM_ SG_ 264 FA_Hoehenwert_VL_01 "Aktueller Höhenwert (Rohwerte) Vorne Links; ungefiltertes Signal
Einheit, Offset und Faktor sind abhänig von 'FA_Hoehenwert_kalibriert'";
CM_ SG_ 264 FA_Hoehenwert_VR_00 "Aktueller Höhenwert (kalibriert) Vorne Rechts; ungefiltertes Signal
Einheit, Offset und Faktor sind abhänig von 'FA_Hoehenwert_kalibriert'

Achtung:
Wird im AUDI B8 nicht bedient";
CM_ SG_ 264 FA_Hoehenwert_VR_01 "Aktueller Höhenwert (Rohwerte) Vorne Rechts; ungefiltertes Signal
Einheit, Offset und Faktor sind abhänig von 'FA_Hoehenwert_kalibriert'";
CM_ SG_ 264 FA_Hoehenwert_HL_00 "Aktueller Höhenwert (kalibriert) Hinten Links; ungefiltertes Signal
Einheit, Offset und Faktor sind abhänig von 'FA_Hoehenwert_kalibriert'

Achtung:
Wird im AUDI B8 nicht bedient";
CM_ SG_ 264 FA_Hoehenwert_HL_01 "Aktueller Höhenwert (Rohwerte) Hinten Links; ungefiltertes Signal
Einheit, Offset und Faktor sind abhänig von 'FA_Hoehenwert_kalibriert'";
CM_ SG_ 264 FA_Hoehenwert_HR_00 "Aktueller Höhenwert (kalibriert) Hinten Rechts; ungefiltertes Signal
Einheit, Offset und Faktor sind abhänig von 'FA_Hoehenwert_kalibriert'

Achtung:
Wird im AUDI B8 nicht bedient";
CM_ SG_ 264 FA_Hoehenwert_HR_01 "Aktueller Höhenwert (Rohwerte) Hinten Rechts; ungefiltertes Signal
Einheit, Offset und Faktor sind abhänig von 'FA_Hoehenwert_kalibriert'";
CM_ BO_ 1138 "Gatewaybotschaft ausschließlich für Anlaufmotorisierung B8 (MED9)";
CM_ SG_ 1138 GW_MED9_01_va_11 "
Platzhalter für veraltet Bit in Gatewaybotschaften

GWxx_va_yz

xx: Index der Gatewaybotschaft
y: Byteposition des veraltet Bits
z: Bitposition des veraltet ";
CM_ SG_ 1138 STH_01_alt "Veraltet Bit für die Signale:

Botschaft Gateway_MED9_01:
STH_EKP_Anst
STH_Ventiloeffnungszeit
STH_Waermeeintrag
STH_Motorvorwaermung
STH_war_aktiv";
CM_ SG_ 1138 GW_MED9_01_va_15 "
Platzhalter für veraltet Bit in Gatewaybotschaften

GWxx_va_yz

xx: Index der Gatewaybotschaft
y: Byteposition des veraltet Bits
z: Bitposition des veraltet ";
CM_ SG_ 1138 GW_MED9_01_va_16 "
Platzhalter für veraltet Bit in Gatewaybotschaften

GWxx_va_yz

xx: Index der Gatewaybotschaft
y: Byteposition des veraltet Bits
z: Bitposition des veraltet ";
CM_ SG_ 1138 GW_MED9_01_va_17 "
Platzhalter für veraltet Bit in Gatewaybotschaften

GWxx_va_yz

xx: Index der Gatewaybotschaft
y: Byteposition des veraltet Bits
z: Bitposition des veraltet ";
CM_ SG_ 2019 ISO_OBD_02_Req_Data "MLBevo: EBKV
MQB: EBKV";
CM_ SG_ 2027 ISO_OBD_02_Resp_Data "MLBevo: EBKV
MQB: EBKV";
CM_ SG_ 2023 ISO_OBD_06_Req_Data "MLBevo: TME
MQB: Wärmepumpen-SG";
CM_ SG_ 2031 ISO_OBD_06_Resp_Data "MLBevo: TME
MQB: Wärmepumpen-SG";
CM_ SG_ 1347 Lift_02_CHK "Berechnung siehe Lastenheft 'Kommunikationsabsicherung für FlexRay und CAN'
Endwerte siehe 'Kommunikationsabsicherung für FlexRay und CAN / Anhang C: Tabelle S-PDU Kennungen'";
CM_ SG_ 1347 Lift_02_BZ "Zähler der von der Applikation inkrementiert wird";
CM_ SG_ 1347 Lift_Status "Status der Vorderachsanhebung (Lift)";
CM_ SG_ 1347 Lift_Charisma_FahrPr "


";
CM_ SG_ 1347 Lift_Charisma_Status "Systemstatus des Charismateilnehmers

";
CM_ SG_ 1347 Lift_Charisma_Umschaltung "Erkennung Umschaltaufforderung des Charisma-Teilnehmers";
CM_ BO_ 917 "MLB";
CM_ SG_ 917 AFS_Abbiegelicht_li_Anf "Anforderung das Abbiegelicht links einzuschalten";
CM_ SG_ 917 AFS_Abbiegelicht_re_Anf "Anforderung das Abbiegelicht rechts einzuschalten";
CM_ SG_ 917 AFS_Abbiegelicht_Dimm_Anf "Beschreibt ob das Abbiegelicht gedimmt oder hart einschalten werden soll. Dimmkurve ist Empfänger hinterlegt.";
CM_ SG_ 917 AFS_Verfuegbarkeit_GLW "Beschreibt die Verfügbarkeit der Gleitenden Leuchtweite / Fernlichtassistenz - Verfügbarkeit bedeutet, dass die Funktion Gleitende Leuchtweite möglich ist";
CM_ SG_ 917 AFS_Status_adaptive_LV "Gibt den Status der adaptiven Lichtverteilung an";
CM_ SG_ 917 AFS_Fernlicht_li_defekt "Beschreibt ob das Fernlicht des linken Scheinwerfers defekt ist";
CM_ SG_ 917 AFS_Fernlicht_re_defekt "Beschreibt ob das Fernlicht des rechten Scheinwerfers defekt ist";
CM_ SG_ 917 AFS_Fernlicht_Status "Beschreibt ob das Fernlicht aktiv oder inaktiv ist";
CM_ SG_ 917 AFS_Lampe "Status der Fehlerlampe: aktuell anliegender Fehlerzustand des dynamischen oder statischen Kurvenlichtes";
CM_ SG_ 917 LWR_Lampe "Status der Fehlerlampe: aktuell anliegender Fehlerzustand";
CM_ SG_ 917 AFS_Fehlertext "Fehlertext wird im Kombi angezeigt (z.Zt nur bei VW)";
CM_ SG_ 917 AFS_LED_Blinkmode "Lampe soll im Warnfall mit 1Hz blinken, wenn das Bit gesetzt ist (z.Zt nur bei VW)";
CM_ SG_ 917 LWR_Touristenmodus_aktiv "Über MMI sendet BCM1 eine Anforderung Touristenmodus an die LWR. Diese sendet als Rückmeldung an BCM1, dass der Touristenmodus aktiv geschaltet wurde";
CM_ SG_ 917 AFS_Charisma_FahrPr "Aktuelles Fahrprogramm des Charisma-Teilnehmers

Achtung neue Modusnamen (wie im MMI):

0x1 = Komfort = Comfort
0x2 = Dynamik = Auto
0x3 = Sport = Dynamic";
CM_ SG_ 917 AFS_Charisma_Status "Charisma Systemstatus des Charisma-Teilnehmers

Wert 0x3 ist nur für Fahrzeuge ab MQB relevant";
CM_ SG_ 917 AFS_Charisma_Umschaltung "Erkennung  Umschaltaufforderung des Charisma-Teilnehmers";
CM_ SG_ 917 AFS_Allwetterlicht "Status ¿Allwetterlicht¿ - Licht für schlechte Sichtverhältnisse
(bei Defekt -> nicht aktiv)";
CM_ SG_ 917 LWR_Touristenmodus_verbaut "Verfügbarkeit der Touristenfunktion im AFS/LWR-SG.
(Das BCM steuert mit diesem Signal die Einblendung des entsprechenden Menüs)";
CM_ SG_ 917 AFS_adaptive_LV_verbaut "Verfügbarkeit der adaptiven Lichtverteilung im AFS-SG.
(Das BCM steuert mit diesem Signal die Einblendung des entsprechenden Menüs)";
CM_ SG_ 917 LWR_Reisemodus_Texte "Anzeige der eingestellten Verkehrsart bei aktivem Touristenlicht";
CM_ SG_ 917 GLW_Sensor_blockiert "Das Signal zeigt an, dass die Kamera zur Zeit keine Sicht hat. 
Verhalten wie Fernlichassisten. 
Weiterleitung des Signals vom BCM an das KOMBI";
CM_ SG_ 917 LWR_Pos_Schrittmotor "Position des Aktuators in Prozent des maximalen Stellweges; vor dem Initialisierungslauf (Motorstart) wird der Initwert ausgegeben: 
0% : tiefste Stellung (auf Block) des Schrittmotors;
100% : maximaler Verstellweg des Schrittmotors (nicht die Grenze de";
CM_ SG_ 917 LWR_Hoehenwert_VL "Aktueller Höhensensorwert Vorne Links

0x7F = 0 mm";
CM_ SG_ 917 LWR_Hoehenwert_HL "Aktueller Höhensensorwert Hinten Links
MSS LB überträgt den Aktueller Höhensensorwert Vorne Rechts.

0x7F = 0 mm";
CM_ SG_ 917 AFS_Ersatzlicht_Links "Bei aktivierter Ersatzlichtfunktion wird das Abblendlicht ausgeschaltet und eine Ersatzlichtquelle eingeschaltet (z.Zt. B7)";
CM_ SG_ 917 AFS_Ersatzlicht_Rechts "Bei aktivierter Ersatzlichtfunktion wird das Abblendlicht ausgeschaltet und eine Ersatzlichtquelle eingeschaltet (z.Zt. B7)";
CM_ SG_ 917 LWR_AFS_Grundeinstellung "Grundeinstellung des Abblendlichtes am Lichteinstellkasten im Service oder Bandende mit Tester erfolgt! (auch für das dynamische Kurvernlicht)";
CM_ SG_ 917 LWR_AFS_Parametrisierung "Parametrisierung wählt die Fahrzeugvariante und die AFS-Variante aus";
CM_ SG_ 917 LWR_Initialisierungslauf "Initialisierungslauf der Schrittmotoren, erfolgt defaultmäßig beim Motorstart";
CM_ SG_ 917 LWR_Sicherheitsposition "LWR Sicherheitsposition beider Scheinwerfers";
CM_ SG_ 917 LWR_Modus "Schnelle oder langsame Regelart der LWR";
CM_ SG_ 917 LWR_KD_Fehler "Bei gesetztem Bit ist mindestens ein Kundendienstfehler eingetragen";
CM_ SG_ 1759 NMH_Aero_Start_1 "Transition in NMH-Statemachine: 'Bus-Sleep' ==> 'Start'
Das Bit wird von der Standard-SW bedient.";
CM_ SG_ 1759 NMH_Aero_Start_2 "Transition in NMH-Statemachine: 'Prepare To Sleep' ==> 'Start'
Das Bit wird von der Standard-SW bedient.";
CM_ SG_ 1759 NMH_Aero_Normal_Mode_1 "Transition in NMH-Statemachine: 'Start' ==> 'Normal Mode'
Das Bit wird von der Standard-SW bedient.";
CM_ SG_ 1759 NMH_Aero_Normal_Mode_2 "Transition in NMH-Statemachine: 'Ready To Sleep' ==> 'Normal'
Das Bit wird von der Standard-SW bedient.";
CM_ SG_ 1759 NMH_Aero_Car_WakeUp "Das Bit wird vom SG nicht bedient. Die Car Wakeup-Funktionalität ist im SG nicht umgesetzt.
";
CM_ SG_ 1759 NMH_Aero_Per_WakeUp "Peripherie-Wakeup (Peripherie inkl. CAN hat geweckt):
1 = CAN

";
CM_ SG_ 1759 NMH_Aero_Fkt_WakeUp "Funktions-Wakeup (Softwarefunktion hat geweckt):
0x0 Peripherie-Wakeup


";
CM_ SG_ 1759 NMH_Aero_Klemme_15 "NM-Nachlaufursache: Das SG sendet noch NM-high Botschaften (befindet sich nicht im Zustand 'Ready To Sleep') aufgrund einer eingeschalteten Kl.15. In diesem Fall wird das Bit vom SG gesetzt.";
CM_ SG_ 1759 NMH_Aero_Diagnose "NM-Nachlaufursache: Das SG sendet noch NM-high Botschaften (befindet sich nicht im Zustand 'Ready To Sleep') bei Kl.15 AUS und aktiver Diagnosesession. In diesem Fall wird das Bit vom SG gesetzt.";
CM_ SG_ 1759 NMH_Aero_MindestAktivZeit "NM-Nachlaufursache: Das SG sendet noch NM-high Botschaften (befindet sich nicht im Zustand 'Ready To Sleep') aufgrund der Mindestaktivzeit von 4s. In diesem Fall wird das Bit vom SG gesetzt.";
CM_ SG_ 1759 NMH_Aero_NL_Datem_EEPROM "EEPROM Datenspeicherung (lokaler / SG interner Nachlauf vor Wakeup)";
CM_ SG_ 1759 NMH_Aero_Signalfehler "Bei der Speicherung eines CAN-Signalfehlers muss dieser mindestens einmal in der NM-Botschaft angezeigt werden.";
CM_ SG_ 1759 NMH_Aero_TimeOut_Fehler "Das SG hat einen aktiven Timeout-Fehler zu einem anderen SG erkannt und setzt dieses Bit. Der FSP-Eintrag ist aktiv. Sobald wieder Botschaften des anderen Teilnehmers empfangen werden (FSP-Eintrag passiv), wird das Bit zurückgesetzt.";
CM_ SG_ 1759 NMH_Aero_CAN_Diag_deaktiv "Das Bit wird vom SG in folgenden Fällen gesetzt (CAN-Diagnose ist deaktiv):
- Hochlauf des Steuergeräts nach CAN-Wakeup (t_diag_start ist noch nicht abgelaufen)
- Retriggerung von t_diag_start bei Kl.15 EIN
- Unterspannung (U < 9V)
- Überspannung (U >";
CM_ SG_ 1759 NMH_Aero_KompSchutz "Das Bit wird vom SG immer mit 0 gesendet";
CM_ SG_ 1759 NMH_Aero_Mute_Mode "Das Bit wird vom SG wie folgt bedient: wenn über den UDS-Service 'Communication Control' ein Abschalten der Applikationsbotschaften gefordert wird und gleichzeitig noch NWM-Botschaften gesendet werden dürfen, dann wird das Bit gesetzt
";
CM_ SG_ 1759 NMH_Aero_Transport_Mode "Funktionseinschränkung aufgrund Transportmodus aktiv:
Das Bit wird vom SG gesetzt, wenn das Signal 'BEM_02_Abschaltstufen' in der Botschaft BEM_02 den Wert 4 
(= Transportmodus) annimmt. Die Ambientebeleuchtung wird vom SG abgeschaltet bzw. nicht einges";
CM_ SG_ 1759 NMH_Aero_Abschaltstufe_aktiv "Funktionseinschränkung aufgrund Abschaltstufe aktiv:
Das Bit wird vom SG gesetzt, wenn das Signal 'BEM_02_Abschaltstufen' in der Botschaft BEM_02 den Wert 2 (= Stufe 2), den Wert 3 (= Stufe 3) oder den Wert 7 (= Ruhestrommessmodus) annimmt. Die Ambienteb";
CM_ SG_ 1759 NMH_Aero_Busfehler "Das Bit wird vom SG gesetzt, wenn der ERROR-Pin des CAN-Transceivers dem µController einen Fehler signalisiert.";
CM_ SG_ 1759 NMH_Aero_Lokalaktiv "Zeigt an ob Steuergerät lokal aktiv war";
CM_ SG_ 1759 NMH_Aero_Subsystemaktiv "Zeigt an ob ein Subsystem des SGs nach Klemme15 AUS und nach entsprechender MAX Aktivzeit noch aktiv war";
CM_ SG_ 266 TSK_01_CHK "Berechnung siehe Lastenheft 'Kommunikationsabsicherung für FlexRay und CAN'
Endwerte siehe 'Kommunikationsabsicherung für FlexRay und CAN / Anhang C: Tabelle S-PDU Kennungen'";
CM_ SG_ 266 TSK_Status_AB "Aktueller Betriebs-/Fehlerstatus des Antriebsstrangs bzw. der Bremse wird über eine Bitleiste dem ACC mitgeteilt. Abhängig vom gesetzten Bit in diesem Signal wird im ACC bestimmte Reaktion bzgl. Abschaltung, FSP-Eintrag, Kombi-Anzeige und Deaktivierung vo";
CM_ SG_ 266 TSK_amax_moeglich "Das Signal spiegelt das im jeweiligen Fahrzeugprojekt von Automatikgetrieben gesendete Signal GE_amax_moeglich. Das Signal wird unverändert weiter geroutet. Bei Fahrzeugen mit Handschaltgetriebe wird das Signal nicht bedient. ";
CM_ SG_ 268 TSK_02_CHK "Berechnung siehe Lastenheft 'Kommunikationsabsicherung für FlexRay und CAN'
Endwerte siehe 'Kommunikationsabsicherung für FlexRay und CAN / Anhang C: Tabelle S-PDU Kennungen'";
CM_ SG_ 268 TSK_Anhalten "Im Falle eines gesetzten Bits wird vom TSK ein Anhalten bis in den Stand gewünscht. Das Bit wird vom ACC nur unterhalb einer applizierbaren Geschwindigkeitsschwelle gesetzt, und vom TSK weitergeleitet. Notwendig für die ACCplus-Funktionalität. Vorhalt für";
CM_ SG_ 268 TSK_Radbremsmom "Bei der Schnittstelle vom TSK zum ESP soll in Folgeprojekten des B8 und insbesondere bei VW-Projekten die Ansteuerung der Bremse nicht über Sollbeschleunigung sondern Bremsmoment erfolgen.  Es handelt sich genauer um das Summenradbremsmoment, welches die ";
CM_ SG_ 268 TSK_Standby_Anf_ESP "Mit diesem Bit wird das aktive Bremssystem auf eine anstehende TSK-Verzögerungsanforderung vorbereitet (Überfahren Leerweg, Anlegen Bremsbeläge)";
CM_ SG_ 268 TSK_Verzoeg_Anf "B8: Verzögerungsanforderung der ACC oder ggf. GRA+ Funktion für ECD Regelung im ESP";
CM_ SG_ 983 VS_FH_FT_hoch "Ansteuerung Fensterheber vom Verdecksteuergeraet";
CM_ SG_ 983 VS_FH_FT_Langhub "Ansteuerung Fensterheber vom Verdecksteuergeraet";
CM_ SG_ 983 VS_FH_BT_hoch "Ansteuerung Fensterheber vom Verdecksteuergeraet";
CM_ SG_ 983 VS_FH_BT_Langhub "Ansteuerung Fensterheber vom Verdecksteuergeraet";
CM_ SG_ 983 VS_FH_HL_hoch "Ansteuerung Fensterheber vom Verdecksteuergeraet";
CM_ SG_ 983 VS_FH_HL_Langhub "Ansteuerung Fensterheber vom Verdecksteuergeraet";
CM_ SG_ 983 VS_FH_HR_hoch "Ansteuerung Fensterheber vom Verdecksteuergeraet";
CM_ SG_ 983 VS_FH_HR_Langhub "Ansteuerung Fensterheber vom Verdecksteuergeraet";
CM_ SG_ 983 VS_KD_Fehler "Status Kundendienstfehlerspeichereinträge
";
CM_ SG_ 983 VS_VD_zu_ver "
";
CM_ SG_ 983 VS_VD_entriegelt "

";
CM_ SG_ 983 VS_VD_offen_ver "

";
CM_ SG_ 983 VS_VD_Zwischenposition "

";
CM_ SG_ 983 VS_VD_Bew_auf "



";
CM_ SG_ 983 VS_VD_Bew_zu "


";
CM_ SG_ 983 VS_Verdeck_Anf "



";
CM_ SG_ 983 VS_Hardtop "



";
CM_ SG_ 983 VS_VD_Fehler "

";
CM_ SG_ 983 VS_Lampe_Blk "Ansteuerung Lampe im Kombi

Wird aktiviert bei Aufprüfen, Verdecklauf und Fehlerfall (blinkend).


";
CM_ SG_ 983 VS_Buzzer "Buzzeransteuerung: 'Buzzeransteuerung' für Gong 200ms (Kombi)";
CM_ SG_ 983 VS_HD_sperren "Bei gesetztem Signal wird der Kofferraum/Heckdeckel durch den BCM2 nicht entriegelt werden.";
CM_ SG_ 983 VS_HHS_enable "

";
CM_ SG_ 983 VS_VVW_unten "Verschluss Verdeckwanne unten


";
CM_ SG_ 983 VSG_FT_FH_BT_ManHoch "manueller Hochlauf der Beifahrertür Seitenscheiben ausgelöst durch zentralen Fensterhbertaster";
CM_ SG_ 983 VSG_FT_FH_BT_AutoHoch "automatischer Hochlauf der Beifahrertür Seitenscheiben ausgelöst durch zentralen Fensterhbertaster";
CM_ SG_ 983 VSG_FT_FH_BT_ManTief "manueller Tieflauf der Beifahrertür Seitenscheiben ausgelöst durch zentralen Fensterhbertaster";
CM_ SG_ 983 VSG_FT_FH_BT_AutoTief "automatischer Tieflauf der Beifahrertür Seitenscheiben ausgelöst durch zentralen Fensterhbertasterv";
CM_ SG_ 983 VSG_FT_FH_FT_ManHoch "manueller Hochlauf der Fahrertür Seitenscheiben ausgelöst durch zentralen Fensterhbertaster";
CM_ SG_ 983 VSG_FT_FH_FT_AutoHoch "automatischer Hochlauf der Fahrertür Seitenscheiben ausgelöst durch zentralen Fensterhbertaster";
CM_ SG_ 983 VSG_FT_FH_FT_ManTief "manueller Tieflauf der Fahrertür Seitenscheiben ausgelöst durch zentralen Fensterhbertaster";
CM_ SG_ 983 VSG_FT_FH_FT_AutoTief "automatischer Tieflauf der Fahrertür Seitenscheiben ausgelöst durch zentralen Fensterhbertaster";
CM_ SG_ 983 VSG_FT_FH_HL_ManHoch "manueller Hochlauf der hinteren, linken Seitenscheibe ausgelöst durch zentralen Fensterhbertaster";
CM_ SG_ 983 VSG_FT_FH_HL_AutoHoch "automatischer Hochlauf der hinteren, linken Tür Seitenscheiben ausgelöst durch zentralen Fensterhbertaster";
CM_ SG_ 983 VSG_FT_FH_HL_ManTief "manueller Tieflauf der hinteren, linken Seitenscheibe ausgelöst durch zentralen Fensterhbertaster";
CM_ SG_ 983 VSG_FT_FH_HL_AutoTief "automatischer Tieflauf der hinteren, linken Seitenscheibe ausgelöst durch zentralen Fensterhbertaster";
CM_ SG_ 983 VSG_FT_FH_HR_ManHoch "manueller Hochlauf der hinteren, rechten Seitenscheibe ausgelöst durch zentralen Fensterhbertaster";
CM_ SG_ 983 VSG_FT_FH_HR_AutoHoch "automatischer Hochlauf der hinteren, rechten Tür Seitenscheiben ausgelöst durch zentralen Fensterhbertaster";
CM_ SG_ 983 VSG_FT_FH_HR_ManTief "manueller Tieflauf der hinteren, rechten Seitenscheibe ausgelöst durch zentralen Fensterhbertaster";
CM_ SG_ 983 VSG_FT_FH_HR_AutoTief "automatischer Tieflauf der hinteren, rechten Seitenscheibe ausgelöst durch zentralen Fensterhbertaster";
CM_ SG_ 983 VS_Texte "Meldungen fuers Kombi

Audi:
  0x1: Verdeck Betaetigung nicht moeglich
  0x2: Verdeckwanne absenken
  0x4: Verdeck Heckdeckel schließen
  0x80: Verdeck nicht in Endlage


";
CM_ SG_ 912 WBA_WH_Sleep_ACK_alt "Vorhalt falls PQ35 Wähhebel am ACAN zum Einsatz kommt";
CM_ SG_ 912 GE_Warnung_Auto_N_LB "nur vom Lambo unterstützt";
CM_ SG_ 912 WBA_GE_Fastshift "Signal aktiviert die Anzeige im LB Kombi, welche dem Fahrer die Möglichkeit zum schnellen Sportschalten (Fast shifting) anzeigt.";
CM_ SG_ 912 WBA_GE_Textmeldungen "Prioritaetswarnungen Getriebe";
CM_ BO_ 269 "Ersatz für ACC_01 => wegen Umbau der TSK-Schnittstelle im D4";
CM_ SG_ 269 ACC_05_CHK "Berechnung siehe Lastenheft 'Kommunikationsabsicherung für FlexRay und CAN'
Endwerte siehe 'Kommunikationsabsicherung für FlexRay und CAN / Anhang C: Tabelle S-PDU Kennungen'";
CM_ SG_ 269 ACC_Freigabe_Momentenanf "Bit 'Freigabe Momentenanforderung': Freigabe der Momentenanforderung an den Motor 

0x0 = Momentenanforderung nicht freigegeben
0x1 = Momentenanforderung freigegeben";
CM_ SG_ 269 ACC_Freigabe_Verzanf "Bit 'Freigabe Verzögerungsanforderung': Freigabe der Verzögerungsanforderung an die Bremse

0x0 = Verzögerungsanforderung nicht freigegeben
0x1 = Verzögerungsanforderung freigegeben";
CM_ SG_ 269 ACC_Getriebestellung_P "Anforderung vom ACC an das Getriebe, daß die Getriebestellung P so schnell wie möglich einzulegen ist.";
CM_ SG_ 269 ACC_limitierte_Anfahrdyn "Info für den Motor, dass beim ACC-Anfahren mit Zielfahrzeug seitens ACC eine limitierte Fahrpedalkennlinie gefordert wird.";
CM_ SG_ 269 ACC_Momentenanforderung "Momentenanforderung an den Motor. Achtung: Einheitenloser CAN-Wert. Faktor in MO_Faktor_Momente in Motor_Code_01 
beachten! 1022 und 1023 sind nicht definierte Werte.";
CM_ SG_ 269 ACC_zul_Regelabw "Anforderung der zulässigen Regelabweichung vom ACC. Zulässiger Betrag der Abweichung zwischen angeforderter 'ACC_ax_Getriebe' und umzusetzender Sollbeschleunigung  im Getriebe.";
CM_ SG_ 269 ACC_Verz_anf "Verzögerungsanforderung an die Bremse.";
CM_ SG_ 269 ACC_Loeseanforderung "Anforderung des ACC an ESP zum Lösen der ECD-Bremsung bei selbständigem Anfahren aus dem Stand im Rahmen der ACC-Stop&Go-Funktion";
CM_ SG_ 269 ACC_StartStopp_Info "Freigabe bzw. Startanforderung für Start/Stopp";
CM_ SG_ 269 ACC_Segelveto "Segelvetoinformation vom ACC";
CM_ SG_ 269 ACC_Vorbefuellung_Bremsanlage "Nur im VW526: Über das Signal fordert das ACC-SG eine Vorbefüllung der Bremsanlage beim ESP-SG an.";
CM_ SG_ 269 ACC_ax_Getriebe "Beschleunigungsanforderung an das Getriebe";
CM_ SG_ 269 ACC_Status_ACC "'ACC OFF' bedeutet ACC-Hauptschalter ist 'Gerastet Aus

'ACC Reversibler Fehler' bedeutet, daß das ACC aktuell einen 
reversiblen Fehler im ACC-SG selbst oder in einem zum 
ACC-System gehörenden SG erkennt.

'ACC irreversibler Fehler' bedeutet, daß ";
CM_ SG_ 269 ACC_Betaetigung_EPB "Anforderung vom ACC an die EPB, dass der EPB-Aktuator so schnell wie möglich zu schliessen ist";
CM_ SG_ 269 ACC_Beeinflussung_ESP "Bit wird verwendet, um ESP zwangsweise zu aktivieren. Bei einem gesetzten Bit ist ein ausgetastetes ESP wieder aktiviert bzw. wird die Austastung verhindert.

0x0 = keine ESP Zwangszuschaltung
0x1 = ESP Zwangszuschaltung";
CM_ SG_ 269 ACC_Anhalten "Im Falle eines gesetzten Bits wird vom ACC ein Anhalten bis in den Stand gewünscht. Das Bit wird von ACC nur unterhalb einer appl. Geschwindigkeitsschwelle gesetzt. Notwendig für die ACCplus-Funktionalität. Nicht für Audi B8 relevant, jedoch im Vorgriff a";
CM_ SG_ 1469 AEM_KD_Fehler "Bei gesetztem Bit ist mindestens ein Kundendienstfehler eingetragen
";
CM_ BO_ 1660 "MLBevo";
CM_ SG_ 1660 AGA_01_CRC "Für MLB:
'Berechnung siehe Lastenheft 'Kommunikationsabsicherung für FlexRay und CAN''

Ab MQB und MLBevo:
'Berechnung siehe Lastenheft 'End-to-End Kommunikationsabsicherung''

Endwerte siehe Begleitdokument 'S-PDU Kennungsfolgen'";
CM_ SG_ 1660 AGA_Texte "Texte zur Anzeige im Kombi";
CM_ SG_ 1660 AGA_ohne_Funktion "Aussensoundsteuergerät ohne Funktion (Gesetzliche Anforderung, Fahrzeugnutzer muss informiert werden).";
CM_ SG_ 1660 AGA_KD_Fehler "Bei gesetztem Bit ist mindestens ein Kundendienstfehler eingetragen";
CM_ SG_ 64 Airbag_01_CHK "Berechnung siehe Lastenheft 'Kommunikationsabsicherung für FlexRay und CAN'
Endwerte siehe 'Kommunikationsabsicherung für FlexRay und CAN / Anhang C: Tabelle S-PDU Kennungen'";
CM_ SG_ 64 AB_RGS_Anst "PreCrash-Ansteuerung reversibler Gurtstraffer (Aktivierung und Kraftniveau)

10xx = deaktiviert";
CM_ SG_ 64 AB_Front_Crash "Bit wird bei Überschreitung der Gurtstraffer-, US- und RdW-Schwelle gesetzt";
CM_ SG_ 64 AB_Heck_Crash "Wird für alle neu anlaufenden Projekte umgesetzt: AB8.4, Audi8/VW8";
CM_ SG_ 64 AB_SF_Crash "Z.Zt. nur in Verbindung mit Crash-Intensität >= 100b (Kraftstoffpumpenabschaltung) verwendet.";
CM_ SG_ 64 AB_SB_Crash "Z.Zt. nur in Verbindung mit Crash-Intensität >= 100b (Kraftstoffpumpenabschaltung) verwendet.
";
CM_ SG_ 64 AB_Rollover_Crash "Wird im B6/B7 Cabrio und New Beetle Cabrio bedient. ";
CM_ SG_ 64 AB_Crash_Int "Crash_Intensität_1 = fahrzeugabhängige Reaktionen im Crash
Crash_Intensität_2 = fahrzeugabhängige Reaktionen im Crash
Crash_Intensität_3 = fahrzeugabhängige Reaktionen im Crash

Die jeweiligen fahrzeugabhängigen Reaktionen im Crash sind in einem separ";
CM_ SG_ 64 AB_Lampe "Sicherheitswarnlampe im Kombi wird vom Airbag-SG angesteuert; Zustand der Lampe wird auf dem CAN-Bus ausgegeben (auch Blinkinformation).";
CM_ SG_ 64 AB_Deaktiviert "Airbag oder Gurtstraffer wurden per Anpassung deaktiviert: Aktualisierung erst nach Selbsttest";
CM_ SG_ 64 AB_VB_deaktiviert "Als Option vorgehalten, Beifahrerairbag wurden per Schlüsselschalter oder Insassenerkennung deaktiviert";
CM_ SG_ 64 AB_Systemfehler "Systemfehler Ggf. wird Warnlampe dauernd eingeschaltet.";
CM_ SG_ 64 AB_Diagnose "Airbag in Diagnose";
CM_ SG_ 64 AB_Stellgliedtest "Information, ob Airbag im Stellgliedtest ist, um eine Notrufauflösung beim Stellgliedtest zu verhindern";
CM_ SG_ 64 AB_Erh_Auf_VB "Der Fahrer soll bei einem Statuswechsel des Beifahrerairbags (ausgelöst durch die Beifahrerinsassenerkennung oder den Schlüsselschloßschalter) aufmerksam gemacht werden durch eine Anzeige im Kombi. Nur Audi: gültig für: AB2 (4-Türer AU352), B7, C6, D3";
CM_ SG_ 64 AB_Gurtwarn_VF "Fahrer hat Gurt nicht gesteckt, Anzeige im Kombi";
CM_ SG_ 64 AB_Gurtwarn_VB "Beifahrer hat Gurt nicht gesteckt, Anzeige im Kombi";
CM_ SG_ 64 AB_Anzeige_Fussg "Anzeige für ausgelöste Fussgängerschutz-Aktuatorik";
CM_ SG_ 64 AB_Texte_AKS "Textanzeige für pyrotechnische Auslösung der aktiven Kopfstütze (AKS)";
CM_ SG_ 64 AB_PAO_Leuchte_Anf "Anforderung an die Passenger-Airbag-Off Leuchte in der Dachkonsole (ein / aus), Einsatz nur bei PAG";
CM_ SG_ 64 AB_MKB_gueltig "Multi-Kollisions-Bremsung im Airbag freigeschaltet";
CM_ SG_ 64 AB_MKB_Anforderung "Anforderung Multi-Kollisions-Bremsung";
CM_ SG_ 64 AB_Versorgungsspannung "Übertragung der Plausibilitätsinformation Kl.15-Last vs. Kl.15-CAN.
Bedienung im Fall Kl.15-Last 'EIN' und Kl.15-CAN 'AUS' mit Ausgabe Warnung/Akustik im Kombi.";
CM_ SG_ 64 AB_Deaktivierung_HV "Deaktivierung des HV-Systems und der HV-Teilnehmer im Crash (u.a. Hybrid- und Elektrofahrzeuge)";
CM_ SG_ 64 AB_EDR_Trigger "Triggerbedingung zur dezentralen Aufzeichnung unfallrelevanter Daten im Event Data Recorder";
CM_ SG_ 64 AB_KD_Fehler "Bei gesetztem Bit ist mindestens ein Kundendienstfehler eingetragen
";
CM_ SG_ 1312 AB_Belegung_VB "Belegungserkennung vorne Beifahrer. Wird in US-Steuergeräten über Bladder-Matte bedient, optional bei RdW, falls SBE_EuroNCAP entschieden wird.";
CM_ SG_ 1312 AB_Abschaltanf_SIH_BF "Die Insassenerkennung auf der Beifahrerseite fordert bei Übertemperatur eine Abschaltung der Sitzheizung an. Die Übertemperatur kann bei niederohmigen Nebenschlüssen der Sitzheizungsmatte als Folge von zu hohem resultierenden Strom auftreten.";
CM_ SG_ 1312 SC_PAO_Schriftzug_Anf "Sollwert für LED 'PASSENGER AIRBAG' in Anzeige Passenger Airbag On/Off";
CM_ SG_ 1312 SC_PAO_ON_Anf "Sollwert für LED 'ON' in Anzeige Passenger Airbag On/Off";
CM_ SG_ 1312 SC_PAO_OFF_Anf "Sollwert für LED 'OFF' in Anzeige Passenger Airbag On/Off";
CM_ SG_ 1312 AB_Crashschwere "Übermittlung der Crashschwere an das Gateway (OBDC)";
CM_ SG_ 1312 AB_Anforderung_USM "Trigger für Gateway (OBDC) und MIB/MMI, dass ein USM-Ereignis erkannt wurde.";
CM_ SG_ 1312 AB_Gurtschloss_FA "Gurtschlosstatatus Fahrerseite";
CM_ SG_ 1312 AB_Gurtschloss_BF "Gurtschlossstatus Beifahrerseite";
CM_ SG_ 1312 AB_Gurtschloss_Reihe2_FA "Gurtschlossstatus 2. Reihe Fahrerseite, Mehrausstattung";
CM_ SG_ 1312 AB_Gurtschloss_Reihe2_MI "Gurtschlossstatus 2. Reihe Mitte,  Mehrausstattung";
CM_ SG_ 1312 AB_Gurtschloss_Reihe2_BF "Gurtschlossstatus 2. Reihe Beifahrerseite,  Mehrausstattung";
CM_ SG_ 1312 AB_Gurtschloss_Reihe3_FA "Gurtschlossstatus 3. Reihe Fahrerseite,  Mehrausstattung";
CM_ SG_ 1312 AB_Gurtschloss_Reihe3_MI "Gurtschlossstatus 3. Reihe Mitte,  Mehrausstattung";
CM_ SG_ 1312 AB_Gurtschloss_Reihe3_BF "Gurtschlossstatus 3. Reihe Beifahrerseite,  Mehrausstattung";
CM_ SG_ 1312 AB_Sitzpos_Sens_FA "Ausgabe Sitzposition Fahrer";
CM_ SG_ 1312 AB_Sitzpos_Sens_BF "Ausgabe Sitzposition Beifahrer";
CM_ SG_ 1312 AB_Trefferlage "Übermittlung der Lage einer Kollision an das Gateway (OBDC)";
CM_ SG_ 65 Airbag_03_CRC "Für MLB:
'Berechnung siehe Lastenheft 'Kommunikationsabsicherung für FlexRay und CAN''

Ab MQB und MLBevo:
'Berechnung siehe Lastenheft 'End-to-End Kommunikationsabsicherung''

Endwerte siehe Begleitdokument 'S-PDU Kennungsfolgen'";
CM_ SG_ 65 AB_MKB_Safing "Safing für Multi-Kollisions-Bremsung";
CM_ SG_ 1633 AAG_BZ "4bit-Botschaftszaehler, wird in jeder Sendebotschaft inkrementiert

";
CM_ SG_ 1633 AAG_AVS_Fehler_02_inv "Fehler AVS (inverses Signal)";
CM_ SG_ 1633 AAG_Bremsl_durch_ECD "Bremslicht durch ECD aktiv";
CM_ SG_ 1633 AAG_Anhaenger_abgesteckt "Anhaenger wurde bei Kl. 15 aus abgesteckt";
CM_ SG_ 1633 AAG_NSL_aktiv "Anhaenger Nebelschlusslicht aktiv";
CM_ SG_ 1633 AAG_Anhaenger_erkannt "Erkennung Anhaenger ";
CM_ SG_ 1633 AAG_Blinker_H_aktiv "Status: Anhaenger Blinker aktiv";
CM_ SG_ 1633 AAG_Blinker_HL_def "Anhaenger Blinker links defekt";
CM_ SG_ 1633 AAG_Blinker_HR_def "Anhaenger Blinker rechts defekt";
CM_ SG_ 1633 AAG_Bremslicht_H_def "Anhaenger Bremslicht defekt";
CM_ SG_ 1633 AAG_Schlusslicht_HL_def "Anhaenger Schlußlicht links defekt";
CM_ SG_ 1633 AAG_Schlusslicht_HR_def "Anhaenger Schlußlicht rechts defekt";
CM_ SG_ 1633 AAG_KD_Fehler "Status Kundendienst-Fehlerspeicher";
CM_ SG_ 1633 AAG_AVS_Fehler "Fehler AVS";
CM_ SG_ 1633 AAG_AVS_Stati "Status AVS (bei abnehmbarer oder mech.schwenkbarer Anhängerkupplung ist der Status immer 0)
";
CM_ BO_ 1542 "BAP-Msg vom Anzeigesteuergerät";
CM_ BO_ 1558 "BAP-Msg vom Funktionssteuergerät";
CM_ BO_ 1580 "BAP-Msg vom Funktionssteuergerät";
CM_ SG_ 1409 BCM_FH_Freigabe "Funktionsfreigabe Fensterheber";
CM_ SG_ 1409 BCM_Komfortfkt_Freigabe "globale Freigabe der Komfortfunktion";
CM_ SG_ 1409 BCM_HSK_Freigabe "Handschuhkastenfreigabe";
CM_ SG_ 1409 BCM_Verdeck_Freigabe "Freigabe Verdeckbetrieb
";
CM_ SG_ 1409 BCM2_Status_Timer_KL15_Abschalt "Anforderung an BCM1, den Deaktivierungstimer für Klemme 15 bei erfüllten Abschaltbedingungen herunterzuzählen";
CM_ SG_ 1409 BCM2_Unterdr_Zuendungsmeldung "Bei aktivem Signal soll die Zündungsmeldung durch das Kombi unterdrückt werden.";
CM_ SG_ 1409 BCM2_KL15_Absch_FT "Signalisierung, dass die KL15 über das Verlassen des Fahrzeuges deaktiviert wurde (über Fahrertürtrigger).";
CM_ SG_ 1409 ZV_ist_Zustand_verfuegbar "Verfügbarkeit IST-Zustand ZV

";
CM_ SG_ 1409 BCM2_P_verriegelt "Nicht plausibilisiertes Rohsignal des P-Verriegeltschalters vom Wählhebel zur exklusiven Nutzung für Getriebesteuergeräte:
";
CM_ SG_ 1409 ZV_verriegelt_intern_ist "Istzustand: Verriegelung Fahrzeug innen
";
CM_ SG_ 1409 ZV_verriegelt_extern_ist "Istzustand: Verriegelung Fahrzeug aussen
";
CM_ SG_ 1409 ZV_verriegelt_intern_soll "Sollzustand: Verriegelung Fahrzeug innen
";
CM_ SG_ 1409 ZV_verriegelt_extern_soll "Sollzustand: Verriegelung Fahrzeug aussen
";
CM_ SG_ 1409 ZV_gesafet_extern_ist "Istzustand: Fahrzeug aussen gesafet
";
CM_ SG_ 1409 ZV_gesafet_extern_soll "Sollzustand: Fahrzeug gesafet extern
";
CM_ SG_ 1409 ZV_FT_offen "gespiegeltes Bit FT_Tuer_geoeffnet TSG_FT_1 Botschaft";
CM_ SG_ 1409 ZV_BT_offen "gespiegeltes Bit BT_Tuer_geoeffnet TSG_BT_1 Botschaft";
CM_ SG_ 1409 ZV_HL_offen "gespiegeltes Bit HL_Tuer_geoeffnet TSG_HL_1 Botschaft";
CM_ SG_ 1409 ZV_HR_offen "gespiegeltes Bit HR_Tuer_geoeffnet TSG_HR_1 Botschaft";
CM_ SG_ 1409 ZV_HD_offen "Status Heckdeckel
";
CM_ SG_ 1409 ZV_Turen_HD_zu "ZV: Tueren und HD geschlossen
";
CM_ SG_ 1409 ZV_Einzeltuerentriegelung "Einzeltürentriegelung ZV
";
CM_ SG_ 1409 ZV_Heckeinzelentriegelung "Heckdeckeleinzelentriegelung";
CM_ SG_ 1409 BCM_ValetTaster_Fkts_LED "Status Funktions-LED Valet Taster ('Valet Parking')
 

";
CM_ SG_ 1409 BCM_HHS_aktiv "Heizbare Heckscheibe aktiv";
CM_ SG_ 1409 BCM_Spg_Hzg_Ein "Anforderung Spiegelheizung
";
CM_ SG_ 1409 ZV_HS_offen "Status Heckscheibe
";
CM_ SG_ 1409 ZZH_Endlage_oben "obere Endlagenerkennung ZZH
";
CM_ SG_ 1409 ZZH_Endlage_unten "untere Endlagenerkennung ZZH
";
CM_ SG_ 1409 ZZH_Endlage_unplausibel "Erkennungung unplausible Endlage ZZH
";
CM_ SG_ 1409 BCM2_KD_Fehler "Status Kundendienstfehlerspeichereinträge
";
CM_ SG_ 1409 NGS_aktiv "Status Neigungssensor
";
CM_ SG_ 1409 IRUE_aktiv "Status Innenraumüberwachung
";
CM_ SG_ 1409 DWA_aktiv "Status DWA
";
CM_ SG_ 1409 Komp_Schutz_aktiv "Status Komponentenschutz (für 'passiven' KS im HDSG)


";
CM_ SG_ 1409 NGS_Taster_Fkts_LED "Anforderung Funktions-LED Neigungs-Taster
";
CM_ SG_ 1409 IRUE_Taster_Fkts_LED "Anforderung Funktions-LED IRUE-Taster (LED wird vom TSG angesteuert)
MQB: Bei Verbau eines einzelnen Taster zur Deaktivierung von IRUE und NGS wird dieses Signal zur Ansteuerung der Funktions-LED gesendet.";
CM_ SG_ 1409 HD_Drehfalle_S1 "S1 = Hauptraste
";
CM_ SG_ 1409 HD_Sperrklinke_S2 "Sperrklinke Heckdeckel (S2 = Vorraste), wird vom BCM2 eingelesen
 
";
CM_ SG_ 1409 BCM_Verbau_Heckrollo "Verbauinfo Heckrollo";
CM_ SG_ 1409 BCM2_EZS_gedrueckt "Betätigung EZS";
CM_ SG_ 1409 BCM2_SST_gedrueckt "Betätigung Start-Stop-Taster (Kessy-Fahrzeug)";
CM_ SG_ 1409 LIM_Innenbeleuchtung_aktiv "Signal ist nur gülitig bei KL15 EIN, da kein aktiver Wakeup bei Statusänderung.
Das signal wird ev. für Rekuperation oder start/stop verwendet.";
CM_ SG_ 1409 BCM_Sperrklinke_FT "Entprelltes Signal der HW-Leitung des Sperrklinkenschalters, welche vom BCM2 eingelesen wird.
0: Schalter geschlossen --> Tuer offen 
1: Schalter offen --> Tuer geschlossen

Gefilterter und plausibilisierter Status der HW-Leitung vom Fahrertür-Sperrkl";
CM_ SG_ 1409 BCM_Tankwunsch "Tankwunsch (Fahrer betätigt Tankdeckeltaster)";
CM_ SG_ 1409 ZV_Tankklappe_offen "Öffnungsstatus der Tankklappe";
CM_ SG_ 1409 BCM_Tankklappensteller_Fehler "Fehler: nicht Funktionalität des Tankklappenstellers";
CM_ SG_ 1409 KST_Fahrer_Hinweise "Kombi Fahrerhinweise Klemmensteuerung
Audi/VW

0x01 P einlegen
0x02 Bremse betätigen
0x03 P oder N einlegen
0x04 Kupplung betätigen
0x05 Zündung eingeschaltet
0x06 Schlüssel im Zündschloß";
CM_ SG_ 1409 KST_Warn_P1_ZST_def "Kombi Prio Warnung Klemmensteuerung 
Zündschloß defekt, Service aufsuchen!";
CM_ SG_ 1409 KST_Warn_P2_ZST_def "Kombi Prio Warnung Klemmensteuerung
Zündschloß defekt!
";
CM_ SG_ 1409 KST_Prio_Warn_03 "Kombi Prio Warnung";
CM_ SG_ 1409 KST_Prio_Warn_04 "Kombi Prio Warnung ";
CM_ SG_ 1409 KST_Prio_Warn_05 "Kombi Prio Warnung Klemmensteuerung 5";
CM_ SG_ 777 BEM_01_CHK "Berechnung siehe Lastenheft 'Kommunikationsabsicherung für FlexRay und CAN'
Endwerte siehe 'Kommunikationsabsicherung für FlexRay und CAN / Anhang C: Tabelle S-PDU Kennungen'";
CM_ SG_ 777 BEM_Segel_Info "0: keine Anforderung 
(Segeln ist ohne Einschänkung erlaubt)
1: Mindestdrehzahl 1 
(Segeln ist mit Einschänkung erlaubt)
2: Mindestdrehzahl 2
(Segeln ist mit Einschänkung erlaubt)
3: Segelveto
(Segeln ist nicht  erlaubt)";
CM_ SG_ 777 BEM_P_Generator "Es gilt: Signalspec BEM_P_Generator v1.0

Mechanische Generatorleistung dient dem Motorsteuergerät zur Berechnung der Motorlast; Genauigkeit ca. +/- (500W + 20% vom Messwert)";
CM_ SG_ 777 BEM_n_LLA "Es gilt: Signalspec BEM_n_LLA v1.0

Anforderung einer Leerlaufdrehzahlanhebung in drei Stufen. Die Höhe der jeweiligen LL-Drehzahlstufe ist im Motorsteuergerät appliziert.



";
CM_ SG_ 777 BEM_01_Abschaltstufen "Signal inhaltlich identisch mit BEM_02_Abschaltstufen. Namentliche Umbenennung wegen Standard-SW im Gateway-BEM im MLB (Handling gleicher Signalnamen im Source-Code).
Abschaltstufen des Ruhestrommanagements 
(Initialisierungswert aus EEPROM)";
CM_ SG_ 777 BEM_Anf_KL "Es gilt: Signalspec BEM_Anf_KL v1.1
Das BEM fordert über das MSG den Kühlerlüfter-Betrieb an; hierzu wird ein minimaler Leistungswert im MSG appliziert. 
Szenario: bei erkannter abgetrennten Batterie soll durch Ansteuerung des Kühlerlüfters das Energien";
CM_ SG_ 777 BEM_StartStopp_Info "Stopp-Freigabe und Start-Anforderung an den Start-Stopp-Koordinator";
CM_ BO_ 1635 "DLC=8 ab D4 gültig";
CM_ SG_ 1635 BEM_02_Abschaltstufen "Abschaltstufen des Ruhestrommanagements (Initialisierungswert aus EEprom)

Stufe 0 (keine Einschraenkungen)
Stufe 1 (Abschaltung Hochstromverbraucher)
Stufe 2 (Infotainmentabschaltung)
Stufe 3 (Wake-Up-Sperre)

Für den Transport- und Ruhestrommessm";
CM_ SG_ 1635 BEM_STH_Zielzeit "Maximal mögliche Zeit für den Standheizungsbetrieb, um die Startfähigkeit nicht zu gefährden";
CM_ SG_ 1635 BEM_MMI_Vorwarnung "Anzeige Vorwarnung MMI-Abschaltung (Initialisierungswert aus EEprom)
";
CM_ SG_ 1635 BEM_HL_Kontingentierung "Leistungskontingente für Heizsysteme";
CM_ SG_ 1635 NVEM_Anf_SD_schalten "Anforderung Nachlauf für den Steckdosenbetrieb
Initialisierungswert aus EEprom";
CM_ SG_ 1635 BEM_Generatordiagnose "Ansteuerung Generatorwarnleuchte im Kombi
";
CM_ SG_ 1635 BEM_Red_Innengeblaese "Reduzierung Innengebläse
";
CM_ SG_ 1635 BEM_STH_Einschaltverbot "Einschränkung Standheizung/-lüftung durch BEM: Setzt der BEM das Bit, dann darf die Standheizung nicht mehr einschalten
(Die Standheizung muss aber nicht abschalten, sondern darf weiterbrennen)
(Initialisierungswert aus EEprom)
";
CM_ SG_ 1635 BEM_HL_Regelung_Status "Status Regelung Heizleistung
";
CM_ SG_ 1635 BEM_Ladezustand "Ladezustand der Niedervoltbatterie
";
CM_ SG_ 1635 BEM_Batteriediagnose "Anzeige von Textwarnungen
";
CM_ SG_ 1635 MIB_Stromsparmodus "Signal beschreibt die Aktivierung für den Stromsparmodus beim MIB.
Bei AUS (= 0) gibt es keine weitere Anforderung an die MIB-Komponenten.
Bei EIN (= 1) werden alle MIB Komponenten in einen Stromsparmodus versetzt.";
CM_ SG_ 1635 BEM_DFM "Generatorauslastungsgrad, vom Generator über LIN an das Gateway gesandt. Das Motorsteuergerät regelt auf dieses Signal die PTC, das Energiemanagement im BSG/BCM kalkuliert die Bordnetzauslastung";
CM_ SG_ 1635 BEM_REK_aktiv "Rekuperationsfreigabe vom Energiemanagement
0x0 = keine Rekuperationsfreigabe
0x1 = Rekuperationsfreigabe";
CM_ SG_ 1635 BEM_EMLIN_ungueltig "Energie-Lin - Signale sind ungültig vom Slave Batteriedatenmodul oder Generator
0 = Signale gültig
1 = Signale ungültig";
CM_ SG_ 1635 BEM_Batt_Ab "Batterieverbindungskontrolle:
0x0: Batterie am Bordnetz
0x1: Batterie ab erkannt";
CM_ SG_ 1635 BEM_UBDM "Batteriespannung, gemessen vom Batteriedatenmodul";
CM_ SG_ 1635 BEM_UGenSoll "Sollspannungsvorgabe an den Generator, beinhaltet temperaturoptimierte Batterieladung und Rekuperation";
CM_ SG_ 1635 BEM_Anf_KL15_schalten "Abschaltempfehlung bzw. Verhinderung der automatischen Abschaltung Kl15 durch das BCM";
CM_ SG_ 946 BEM_HYB_DC_uMinLV "Abregelgrenze: minimal erlaubte Bordnetzspannung im Hochsetzbetrieb (Hybrid)";
CM_ SG_ 946 BEM_HYB_DC_uSollLV "Sollwert für die Bordnetzspannung im Tiefsetzbetrieb vom Traktionsnetz ins Bordnetz (Hybrid)";
CM_ SG_ 946 BEM_Freigabe_HV_Ladung "Signalisierung, dass ein Aufladen der HV-Batterie aus der 12V-Seite heraus möglich ist.
Prämissen: 
Ladegerät an 12V-Seite oder
guter Ladezustand der 12V-Batterie";
CM_ SG_ 946 BEM_Hybrid_Info "Einschränkung des Hybridbetriebs durch Energiemanagement
0 = keine Einschränkung des Hybridbetriebs durch das Energiemanagement [Hybridfreigabe]
1 = Motorstart über 12V-Starter nur bei v = 0 km/h möglich
2 = kein Motorstart über 12V-Starter nach elektr";
CM_ SG_ 946 BEM_NV_NachladAnf "Bei Energiedefizit auf der Niedervoltseite wird der Lademanager aufgefordert, die Niedervoltseite nachzuladen.";
CM_ SG_ 1628 BMS_HYB_ASV_hinten_Status "Status Absperrventil des Kältemittelkreislaufs zur Batteriekühlung";
CM_ SG_ 1628 BMS_HYB_ASV_vorne_Status "Status Absperrventil des Kältemittelkreislaufs zur Innenraumklimatisierung";
CM_ SG_ 1628 BMS_HYB_KD_Fehler "Bei gesetztem Bit ist mindestens ein Kundendienstfehler eingetragen";
CM_ SG_ 1628 BMS_HYB_BattFanSpd "Relativwert der Batterielüfter-Ansteuerung bezogen auf Maximalwert";
CM_ SG_ 1628 BMS_HYB_VentilationReq "BMS fordert bei Climatronic die Öffnung der Umluftklappe an";
CM_ SG_ 1628 BMS_HYB_Spuelbetrieb_Status "Status Betriebsart der Batterielüftung (Umluft-/Spülbetrieb)";
CM_ SG_ 1628 BMS_HYB_Kuehlung_Anf "Anforderung für aktive Batteriekühlung in vier Stufen:
Stufe 0: keine Kühlanforderung
Stufe 1: 10 °C Verdampfertemperatur Klima
Stufe 2: 3 °C Verdampfertemperatur Klima
Stufe 3: maximale Kühlleistung Klima";
CM_ SG_ 1628 BMS_HYB_Temp_vor_Verd "Lufttemperatur im Klimagerät BMS vor Verdampfer";
CM_ SG_ 1628 BMS_HYB_Temp_nach_Verd "Lufttemperatur im Klimagerät BMS nach Verdampfer";
CM_ SG_ 1628 BMS_Temperatur "battery temperature / Momentanwert: Temperatur der Traktionsbatterie";
CM_ SG_ 1628 BMS_Temperatur_Ansaugluft "Temperature of inlet air / Momentanwert: Ansauglufttemperatur der Batteriekühlung";
CM_ SG_ 1628 BMS_IstSpannung_HV "HV Spannungswert";
CM_ BO_ 482 "CCP in Serie mit 11Bit - Empfangskanal";
CM_ BO_ 490 "CCP in Serie mit 11Bit - Sendekanal";
CM_ BO_ 1666 "CCP in Serie mit 11Bit - Empfangskanal";
CM_ BO_ 480 "CCP in Serie mit 11Bit - Empfangskanal";
CM_ BO_ 488 "CCP in Serie mit 11Bit - Sendekanal";
BA_DEF_  "DBName" STRING ;
BA_DEF_  "GenNWMApBusSleep" STRING ;
BA_DEF_  "GenNWMApCanNormal" STRING ;
BA_DEF_  "GenNWMApCanOff" STRING ;
BA_DEF_  "GenNWMApCanOn" STRING ;
BA_DEF_  "GenNWMApCanSleep" STRING ;
BA_DEF_  "GenNWMApCanWakeUp" STRING ;
BA_DEF_  "GenNWMGotoMode_Awake" STRING ;
BA_DEF_  "GenNWMGotoMode_BusSleep" STRING ;
BA_DEF_  "GenNWMSleepTime" INT 0 1000000;
BA_DEF_  "GenNWMTalkNM" STRING ;
BA_DEF_  "Manufacturer" STRING ;
BA_DEF_  "NmhBaseAddress" HEX 0 536870911;
BA_DEF_  "NmhMessageCount" INT 0 256;
BA_DEF_  "NmType" STRING ;
BA_DEF_  "VAGTP20_SetupMessageCount" INT 0 255;
BA_DEF_  "VAGTP20_SetupStartAddress" HEX 0 2047;
BA_DEF_  "VersionDay" INT 1 31;
BA_DEF_  "VersionMonth" INT 1 12;
BA_DEF_  "VersionWeek" INT 1 52;
BA_DEF_  "VersionYear" INT 0 99;
BA_DEF_  "VersionNumber" INT 0 65535;
BA_DEF_  "Baudrate" INT 0 1000000;
BA_DEF_  "SamplePointMin" INT 1 100;
BA_DEF_  "SamplePointMax" INT 1 100;
BA_DEF_  "SyncJumpWidthMin" INT 1 4;
BA_DEF_  "SyncJumpWidthMax" INT 1 4;
BA_DEF_  "NmhTimeoutTimer" INT 0 65535;
BA_DEF_  "NmhWaitBusSleepTimer" INT 0 65535;
BA_DEF_  "NmhPrepareBusSleepTimer" INT 0 65535;
BA_DEF_  "NmhLongTimer" INT 0 65535;
BA_DEF_  "NmhNStart" INT 0 255;
BA_DEF_ BU_  "GenNodAutoGenDsp" ENUM  "No","Yes";
BA_DEF_ BU_  "GenNodAutoGenSnd" ENUM  "No","Yes";
BA_DEF_ BU_  "GenNodSleepTime" INT 0 1000000;
BA_DEF_ BU_  "ILUsed" ENUM  "No","Yes";
BA_DEF_ BU_  "ECUVariantDefault" ENUM  "No","Yes";
BA_DEF_ BU_  "ECUVariantGroup" STRING ;
BA_DEF_ BU_  "VAGTP20_TargetAddress" HEX 0 127;
BA_DEF_ BU_  "NodeLayerModules" STRING ;
BA_DEF_ BU_  "NmhNode" ENUM  "No","Yes";
BA_DEF_ BU_  "NmNode" ENUM  "No","Yes";
BA_DEF_ BO_  "DiagRequest" ENUM  "No","Yes";
BA_DEF_ BO_  "DiagResponse" ENUM  "No","Yes";
BA_DEF_ BO_  "DiagState" ENUM  "No","Yes";
BA_DEF_ BO_  "GenMsgChkConstant" HEX 0 4095;
BA_DEF_ BO_  "GenMsgCycleTime" INT 0 65535;
BA_DEF_ BO_  "GenMsgCycleTimeFast" INT 0 65535;
BA_DEF_ BO_  "GenMsgDelayTime" INT 0 100000;
BA_DEF_ BO_  "GenMsgILSupport" ENUM  "No","Yes";
BA_DEF_ BO_  "GenMsgNrOfRepetition" INT 0 100;
BA_DEF_ BO_  "GenMsgPDUConstants" STRING ;
BA_DEF_ BO_  "GenMsgSendType" ENUM  "Cyclic","not_used","not_used","not_used","not_used","not_used","not_used","IfActive","NoMsgSendType";
BA_DEF_ BO_  "GenMsgStartDelayTime" INT 0 100000;
BA_DEF_ BO_  "NmMessage" ENUM  "No","Yes";
BA_DEF_ BO_  "NmhMessage" ENUM  "No","Yes";
BA_DEF_ BO_  "MsgType" ENUM  "Application","NM ","NMH","TP2.0","ISO-TP ","BAP","EID";
BA_DEF_ BO_  "VAGTP20_API" HEX 0 255;
BA_DEF_ BO_  "VAGTP20_DynConnection" ENUM  "No","Yes";
BA_DEF_ BO_  "VAGTP20_DynSetup" ENUM  "No","Yes";
BA_DEF_ BO_  "VAGTP20_StatConnection" ENUM  "No","Yes";
BA_DEF_ SG_  "GenSigActiveRepetitions" INT -2147483648 2147483647;
BA_DEF_ SG_  "GenSigInactiveValue" INT -2147483648 2147483647;
BA_DEF_ SG_  "GenSigSendType" ENUM  "Cyclic","OnWrite","OnWriteWithRepetition","OnChange","OnChangeWithRepetition","IfActive","IfActiveWithRepetition","NoSigSendType","OnChangeAndIfActive","OnChangeAndIfActiveWithRepetition";
BA_DEF_ SG_  "GenSigStartValue" INT -2147483648 2147483647;
BA_DEF_ SG_  "NWM-WakeupAllowed" ENUM  "No","Yes";
BA_DEF_ SG_  "GenSigFuncType" ENUM  "NoFunction","MsgCounter","CRC-8","XOR","XOR-2","DatedBit","SW-Kl15","CHK","Constant","Protocol","CRC-8-SAE_J1850";
BA_DEF_ SG_  "GenSigSwitchedByIgnition" ENUM  "No","Yes";
BA_DEF_ SG_  "Fehlerwert" HEX 0 2147483647;
BA_DEF_ SG_  "GenSigMissingSourceValue" HEX 0 2147483647;
BA_DEF_REL_ BU_SG_REL_  "GenSigTimeoutTime" INT 0 65535;
BA_DEF_DEF_  "DBName" "";
BA_DEF_DEF_  "GenNWMApBusSleep" "";
BA_DEF_DEF_  "GenNWMApCanNormal" "";
BA_DEF_DEF_  "GenNWMApCanOff" "";
BA_DEF_DEF_  "GenNWMApCanOn" "";
BA_DEF_DEF_  "GenNWMApCanSleep" "";
BA_DEF_DEF_  "GenNWMApCanWakeUp" "";
BA_DEF_DEF_  "GenNWMGotoMode_Awake" "";
BA_DEF_DEF_  "GenNWMGotoMode_BusSleep" "";
BA_DEF_DEF_  "GenNWMSleepTime" 0;
BA_DEF_DEF_  "GenNWMTalkNM" "";
BA_DEF_DEF_  "Manufacturer" "";
BA_DEF_DEF_  "NmhBaseAddress" 0;
BA_DEF_DEF_  "NmhMessageCount" 1;
BA_DEF_DEF_  "NmType" "None";
BA_DEF_DEF_  "VAGTP20_SetupMessageCount" 0;
BA_DEF_DEF_  "VAGTP20_SetupStartAddress" 0;
BA_DEF_DEF_  "VersionDay" 7;
BA_DEF_DEF_  "VersionMonth" 11;
BA_DEF_DEF_  "VersionWeek" 45;
BA_DEF_DEF_  "VersionYear" 12;
BA_DEF_DEF_  "VersionNumber" 0;
BA_DEF_DEF_  "Baudrate" 0;
BA_DEF_DEF_  "SamplePointMin" 1;
BA_DEF_DEF_  "SamplePointMax" 1;
BA_DEF_DEF_  "SyncJumpWidthMin" 1;
BA_DEF_DEF_  "SyncJumpWidthMax" 1;
BA_DEF_DEF_  "NmhTimeoutTimer" 0;
BA_DEF_DEF_  "NmhWaitBusSleepTimer" 0;
BA_DEF_DEF_  "NmhPrepareBusSleepTimer" 0;
BA_DEF_DEF_  "NmhLongTimer" 0;
BA_DEF_DEF_  "NmhNStart" 0;
BA_DEF_DEF_  "GenNodAutoGenDsp" "Yes";
BA_DEF_DEF_  "GenNodAutoGenSnd" "Yes";
BA_DEF_DEF_  "GenNodSleepTime" 0;
BA_DEF_DEF_  "ILUsed" "Yes";
BA_DEF_DEF_  "ECUVariantDefault" "Yes";
BA_DEF_DEF_  "ECUVariantGroup" "";
BA_DEF_DEF_  "VAGTP20_TargetAddress" 0;
BA_DEF_DEF_  "NodeLayerModules" "";
BA_DEF_DEF_  "NmhNode" "Yes";
BA_DEF_DEF_  "NmNode" "No";
BA_DEF_DEF_REL_ "GenSigTimeoutTime" 0;
BA_DEF_DEF_  "DiagRequest" "No";
BA_DEF_DEF_  "DiagResponse" "No";
BA_DEF_DEF_  "DiagState" "No";
BA_DEF_DEF_  "GenMsgChkConstant" 0;
BA_DEF_DEF_  "GenMsgCycleTime" 0;
BA_DEF_DEF_  "GenMsgCycleTimeFast" 0;
BA_DEF_DEF_  "GenMsgDelayTime" 0;
BA_DEF_DEF_  "GenMsgILSupport" "No";
BA_DEF_DEF_  "GenMsgNrOfRepetition" 0;
BA_DEF_DEF_  "GenMsgPDUConstants" "";
BA_DEF_DEF_  "GenMsgSendType" "NoMsgSendType";
BA_DEF_DEF_  "GenMsgStartDelayTime" 0;
BA_DEF_DEF_  "NmMessage" "No";
BA_DEF_DEF_  "NmhMessage" "No";
BA_DEF_DEF_  "MsgType" "Application";
BA_DEF_DEF_  "VAGTP20_API" 0;
BA_DEF_DEF_  "VAGTP20_DynConnection" "No";
BA_DEF_DEF_  "VAGTP20_DynSetup" "No";
BA_DEF_DEF_  "VAGTP20_StatConnection" "No";
BA_DEF_DEF_  "GenSigActiveRepetitions" 0;
BA_DEF_DEF_  "GenSigInactiveValue" 0;
BA_DEF_DEF_  "GenSigSendType" "NoSigSendType";
BA_DEF_DEF_  "GenSigStartValue" 0;
BA_DEF_DEF_  "NWM-WakeupAllowed" "No";
BA_DEF_DEF_  "GenSigFuncType" "NoFunction";
BA_DEF_DEF_  "GenSigSwitchedByIgnition" "Yes";
BA_DEF_DEF_  "Fehlerwert" 0;
BA_DEF_DEF_  "GenSigMissingSourceValue" 0;
BA_ "NmhNStart" 5;
BA_ "NmhLongTimer" 200;
BA_ "NmhPrepareBusSleepTimer" 500;
BA_ "NmhWaitBusSleepTimer" 750;
BA_ "NmhTimeoutTimer" 1000;
BA_ "SyncJumpWidthMax" 4;
BA_ "SyncJumpWidthMin" 2;
BA_ "SamplePointMax" 84;
BA_ "SamplePointMin" 80;
BA_ "Baudrate" 500000;
BA_ "VAGTP20_SetupStartAddress" 512;
BA_ "VAGTP20_SetupMessageCount" 128;
BA_ "NmType" "NM-High";
BA_ "NmhMessageCount" 64;
BA_ "NmhBaseAddress" 1728;
BA_ "Manufacturer" "VAG";
BA_ "GenNWMTalkNM" "Nmh_ReqNetOn()";
BA_ "GenNWMSleepTime" 4000;
BA_ "GenNWMGotoMode_BusSleep" "Nmh_ReqNetOff()";
BA_ "GenNWMGotoMode_Awake" "Nmh_ReqNetOn()";
BA_ "GenNWMApCanOn" "NMIndnetOn()";
BA_ "GenNWMApCanOff" "NMIndnetOff()";
BA_ "GenNWMApBusSleep" "NMIndNetSDN()";
BA_ "DBName" "D4_CAN_Antrieb";
BA_ "NodeLayerModules" BU_ Aero_LB "NMHigh.DLL";
BA_ "VAGTP20_TargetAddress" BU_ Aero_LB 23;
BA_ "GenNodSleepTime" BU_ Aero_LB 4000;
BA_ "NmhNode" BU_ AFS_MLB 0;
BA_ "VAGTP20_TargetAddress" BU_ AFS_MLB 6;
BA_ "ECUVariantGroup" BU_ AFS_MLB "LWR";
BA_ "GenNodSleepTime" BU_ AFS_MLB 4000;
BA_ "NmhNode" BU_ Airbag_B8 0;
BA_ "VAGTP20_TargetAddress" BU_ Airbag_B8 5;
BA_ "GenNodSleepTime" BU_ Airbag_B8 4000;
BA_ "NmhNode" BU_ BCM1_B8 0;
BA_ "GenNodSleepTime" BU_ BCM1_B8 4000;
BA_ "NodeLayerModules" BU_ Gateway_B8 "NMHigh.DLL";
BA_ "VAGTP20_TargetAddress" BU_ Gateway_B8 31;
BA_ "GenNodSleepTime" BU_ Gateway_B8 4000;
BA_ "NodeLayerModules" BU_ Getriebe_AL551_651_B8 "NMHigh.DLL";
BA_ "ECUVariantGroup" BU_ Getriebe_AL551_651_B8 "Getriebe";
BA_ "GenNodSleepTime" BU_ Getriebe_AL551_651_B8 4000;
BA_ "NodeLayerModules" BU_ Getriebe_AL551_Q5_Hybrid "NMHigh.DLL";
BA_ "ECUVariantGroup" BU_ Getriebe_AL551_Q5_Hybrid "Getriebe";
BA_ "ECUVariantDefault" BU_ Getriebe_AL551_Q5_Hybrid 0;
BA_ "GenNodSleepTime" BU_ Getriebe_AL551_Q5_Hybrid 4000;
BA_ "NodeLayerModules" BU_ Getriebe_SL_LB "NMHigh.DLL";
BA_ "VAGTP20_TargetAddress" BU_ Getriebe_SL_LB 2;
BA_ "ECUVariantGroup" BU_ Getriebe_SL_LB "Getriebe";
BA_ "ECUVariantDefault" BU_ Getriebe_SL_LB 0;
BA_ "GenNodSleepTime" BU_ Getriebe_SL_LB 4000;
BA_ "NmhNode" BU_ Lift_MLB_LB 0;
BA_ "VAGTP20_TargetAddress" BU_ Lift_MLB_LB 27;
BA_ "GenNodSleepTime" BU_ Lift_MLB_LB 4000;
BA_ "NmhNode" BU_ LWR_MLB 0;
BA_ "VAGTP20_TargetAddress" BU_ LWR_MLB 6;
BA_ "ECUVariantGroup" BU_ LWR_MLB "LWR";
BA_ "ECUVariantDefault" BU_ LWR_MLB 0;
BA_ "GenNodSleepTime" BU_ LWR_MLB 4000;
BA_ "NmhNode" BU_ Magnetic_Ride_LB 0;
BA_ "ECUVariantGroup" BU_ Magnetic_Ride_LB "DAEMPFER";
BA_ "ECUVariantDefault" BU_ Magnetic_Ride_LB 0;
BA_ "GenNodSleepTime" BU_ Magnetic_Ride_LB 4000;
BA_ "NodeLayerModules" BU_ Motor_MLB_AU48_AU416_Diesel "NMHigh.DLL";
BA_ "ECUVariantGroup" BU_ Motor_MLB_AU48_AU416_Diesel "Motor";
BA_ "ECUVariantDefault" BU_ Motor_MLB_AU48_AU416_Diesel 0;
BA_ "GenNodSleepTime" BU_ Motor_MLB_AU48_AU416_Diesel 4000;
BA_ "NodeLayerModules" BU_ Motor_MLB_B8_Q5_Otto "NMHigh.DLL";
BA_ "ECUVariantGroup" BU_ Motor_MLB_B8_Q5_Otto "Motor";
BA_ "GenNodSleepTime" BU_ Motor_MLB_B8_Q5_Otto 4000;
BA_ "NodeLayerModules" BU_ Motor_MLB_Q5_Hybrid "NMHigh.DLL";
BA_ "ECUVariantGroup" BU_ Motor_MLB_Q5_Hybrid "Motor";
BA_ "ECUVariantDefault" BU_ Motor_MLB_Q5_Hybrid 0;
BA_ "GenNodSleepTime" BU_ Motor_MLB_Q5_Hybrid 4000;
BA_ "NmhNode" BU_ Niveau_LB 0;
BA_ "VAGTP20_TargetAddress" BU_ Niveau_LB 12;
BA_ "ECUVariantGroup" BU_ Niveau_LB "DAEMPFER";
BA_ "ECUVariantDefault" BU_ Niveau_LB 0;
BA_ "GenNodSleepTime" BU_ Niveau_LB 4000;
BA_ "NmhNode" BU_ Airbag_D4 0;
BA_ "GenNodSleepTime" BU_ Airbag_D4 4000;
BA_ "NodeLayerModules" BU_ BMS_Hybrid "NMHigh.DLL";
BA_ "ECUVariantGroup" BU_ BMS_Hybrid "BMS";
BA_ "GenNodSleepTime" BU_ BMS_Hybrid 4000;
BA_ "NmhNode" BU_ Daempfer_MLB 0;
BA_ "VAGTP20_TargetAddress" BU_ Daempfer_MLB 12;
BA_ "GenNodSleepTime" BU_ Daempfer_MLB 4000;
BA_ "NodeLayerModules" BU_ EPB_MLB "NMHigh.DLL";
BA_ "GenNodSleepTime" BU_ EPB_MLB 4000;
BA_ "NmhNode" BU_ ESP 0;
BA_ "GenNodSleepTime" BU_ ESP 4000;
BA_ "NodeLayerModules" BU_ Gateway "NMHigh.DLL";
BA_ "GenNodSleepTime" BU_ Gateway 4000;
BA_ "NodeLayerModules" BU_ Getriebe_AL551_951_D4_C7 "NMHigh.DLL";
BA_ "ECUVariantGroup" BU_ Getriebe_AL551_951_D4_C7 "Getriebe";
BA_ "GenNodSleepTime" BU_ Getriebe_AL551_951_D4_C7 4000;
BA_ "NodeLayerModules" BU_ Getriebe_AL551_Hybrid_D4_C7 "NMHigh.DLL";
BA_ "ECUVariantGroup" BU_ Getriebe_AL551_Hybrid_D4_C7 "Getriebe";
BA_ "ECUVariantDefault" BU_ Getriebe_AL551_Hybrid_D4_C7 0;
BA_ "GenNodSleepTime" BU_ Getriebe_AL551_Hybrid_D4_C7 4000;
BA_ "NodeLayerModules" BU_ Getriebe_DL382_MLB "NMHigh.DLL";
BA_ "GenNodSleepTime" BU_ Getriebe_DL382_MLB 4000;
BA_ "NodeLayerModules" BU_ Getriebe_DL501_MLB "NMHigh.DLL";
BA_ "ECUVariantGroup" BU_ Getriebe_DL501_MLB "Getriebe";
BA_ "ECUVariantDefault" BU_ Getriebe_DL501_MLB 0;
BA_ "GenNodSleepTime" BU_ Getriebe_DL501_MLB 4000;
BA_ "NodeLayerModules" BU_ Getriebe_VL381_MLB "NMHigh.DLL";
BA_ "ECUVariantGroup" BU_ Getriebe_VL381_MLB "Getriebe";
BA_ "ECUVariantDefault" BU_ Getriebe_VL381_MLB 0;
BA_ "GenNodSleepTime" BU_ Getriebe_VL381_MLB 4000;
BA_ "NodeLayerModules" BU_ LEH_Hybrid "NMHigh.DLL";
BA_ "ECUVariantGroup" BU_ LEH_Hybrid "LEH";
BA_ "GenNodSleepTime" BU_ LEH_Hybrid 4000;
BA_ "NmhNode" BU_ LWS_D4 0;
BA_ "GenNodSleepTime" BU_ LWS_D4 4000;
BA_ "NodeLayerModules" BU_ Motor2_MLB_D4_C7 "NMHigh.DLL";
BA_ "ECUVariantGroup" BU_ Motor2_MLB_D4_C7 "Motor_Slave";
BA_ "GenNodSleepTime" BU_ Motor2_MLB_D4_C7 4000;
BA_ "NodeLayerModules" BU_ Motor_MLB_AU64_AU57_Diesel "NMHigh.DLL";
BA_ "ECUVariantGroup" BU_ Motor_MLB_AU64_AU57_Diesel "Motor";
BA_ "ECUVariantDefault" BU_ Motor_MLB_AU64_AU57_Diesel 0;
BA_ "GenNodSleepTime" BU_ Motor_MLB_AU64_AU57_Diesel 4000;
BA_ "NodeLayerModules" BU_ Motor_MLB_BY_Otto "NMHigh.DLL";
BA_ "ECUVariantGroup" BU_ Motor_MLB_BY_Otto "Motor";
BA_ "ECUVariantDefault" BU_ Motor_MLB_BY_Otto 0;
BA_ "GenNodSleepTime" BU_ Motor_MLB_BY_Otto 4000;
BA_ "NodeLayerModules" BU_ Motor_MLB_C7_PHEV "NMHigh.DLL";
BA_ "ECUVariantGroup" BU_ Motor_MLB_C7_PHEV "Motor";
BA_ "ECUVariantDefault" BU_ Motor_MLB_C7_PHEV 0;
BA_ "GenNodSleepTime" BU_ Motor_MLB_C7_PHEV 4000;
BA_ "NodeLayerModules" BU_ Motor_MLB_D4_C7_Hybrid "NMHigh.DLL";
BA_ "ECUVariantGroup" BU_ Motor_MLB_D4_C7_Hybrid "Motor";
BA_ "ECUVariantDefault" BU_ Motor_MLB_D4_C7_Hybrid 0;
BA_ "GenNodSleepTime" BU_ Motor_MLB_D4_C7_Hybrid 4000;
BA_ "NodeLayerModules" BU_ Motor_MLB_D4_C7_Otto "NMHigh.DLL";
BA_ "ECUVariantGroup" BU_ Motor_MLB_D4_C7_Otto "Motor";
BA_ "GenNodSleepTime" BU_ Motor_MLB_D4_C7_Otto 4000;
BA_ "NmhNode" BU_ QSP 0;
BA_ "GenNodSleepTime" BU_ QSP 4000;
BA_ "NmhNode" BU_ SAK 0;
BA_ "GenNodSleepTime" BU_ SAK 4000;
BA_ "NmhNode" BU_ SAK2 0;
BA_ "GenNodSleepTime" BU_ SAK2 4000;
BA_ "NodeLayerModules" BU_ SCR_MLB "NMHigh.DLL";
BA_ "GenNodSleepTime" BU_ SCR_MLB 4000;
BA_ "NmhNode" BU_ SCU 0;
BA_ "VAGTP20_TargetAddress" BU_ SCU 30;
BA_ "GenNodSleepTime" BU_ SCU 4000;
BA_ "GenMsgSendType" BO_ 265 0;
BA_ "GenMsgPDUConstants" BO_ 265 "0x08,0x08,0x08,0x08,0x08,0x08,0x08,0x08,0x08,0x08,0x08,0x08,0x08,0x08,0x08,0x08";
BA_ "GenMsgILSupport" BO_ 265 1;
BA_ "GenMsgCycleTime" BO_ 265 20;
BA_ "GenMsgChkConstant" BO_ 265 8;
BA_ "GenMsgSendType" BO_ 1415 0;
BA_ "GenMsgPDUConstants" BO_ 1415 "0xf8,0xf8,0xf8,0xf8,0xf8,0xf8,0xf8,0xf8,0xf8,0xf8,0xf8,0xf8,0xf8,0xf8,0xf8,0xf8";
BA_ "GenMsgILSupport" BO_ 1415 1;
BA_ "GenMsgDelayTime" BO_ 1415 50;
BA_ "GenMsgCycleTime" BO_ 1415 500;
BA_ "GenMsgChkConstant" BO_ 1415 248;
BA_ "GenMsgSendType" BO_ 325 0;
BA_ "GenMsgPDUConstants" BO_ 325 "0xf9,0xf9,0xf9,0xf9,0xf9,0xf9,0xf9,0xf9,0xf9,0xf9,0xf9,0xf9,0xf9,0xf9,0xf9,0xf9";
BA_ "GenMsgILSupport" BO_ 325 1;
BA_ "GenMsgCycleTime" BO_ 325 20;
BA_ "GenMsgChkConstant" BO_ 325 249;
BA_ "GenMsgSendType" BO_ 867 7;
BA_ "GenMsgNrOfRepetition" BO_ 867 5;
BA_ "GenMsgILSupport" BO_ 867 1;
BA_ "GenMsgDelayTime" BO_ 867 5;
BA_ "GenMsgCycleTimeFast" BO_ 867 50;
BA_ "GenMsgSendType" BO_ 264 0;
BA_ "GenMsgPDUConstants" BO_ 264 "0x09,0x09,0x09,0x09,0x09,0x09,0x09,0x09,0x09,0x09,0x09,0x09,0x09,0x09,0x09,0x09";
BA_ "GenMsgILSupport" BO_ 264 1;
BA_ "GenMsgCycleTime" BO_ 264 25;
BA_ "GenMsgChkConstant" BO_ 264 9;
BA_ "GenMsgSendType" BO_ 1138 0;
BA_ "GenMsgILSupport" BO_ 1138 1;
BA_ "GenMsgCycleTime" BO_ 1138 100;
BA_ "MsgType" BO_ 1906 4;
BA_ "DiagRequest" BO_ 1906 1;
BA_ "MsgType" BO_ 2012 4;
BA_ "DiagResponse" BO_ 2012 1;
BA_ "MsgType" BO_ 1876 4;
BA_ "DiagRequest" BO_ 1876 1;
BA_ "MsgType" BO_ 1982 4;
BA_ "DiagResponse" BO_ 1982 1;
BA_ "MsgType" BO_ 2019 4;
BA_ "DiagRequest" BO_ 2019 1;
BA_ "MsgType" BO_ 2027 4;
BA_ "DiagResponse" BO_ 2027 1;
BA_ "MsgType" BO_ 2023 4;
BA_ "DiagRequest" BO_ 2023 1;
BA_ "MsgType" BO_ 2031 4;
BA_ "DiagResponse" BO_ 2031 1;
BA_ "GenMsgSendType" BO_ 1347 0;
BA_ "GenMsgPDUConstants" BO_ 1347 "0x93,0x93,0x93,0x93,0x93,0x93,0x93,0x93,0x93,0x93,0x93,0x93,0x93,0x93,0x93,0x93";
BA_ "GenMsgILSupport" BO_ 1347 1;
BA_ "GenMsgDelayTime" BO_ 1347 100;
BA_ "GenMsgCycleTime" BO_ 1347 500;
BA_ "GenMsgChkConstant" BO_ 1347 147;
BA_ "GenMsgSendType" BO_ 917 0;
BA_ "GenMsgILSupport" BO_ 917 1;
BA_ "GenMsgCycleTime" BO_ 917 100;
BA_ "MsgType" BO_ 1759 2;
BA_ "NmhMessage" BO_ 1759 1;
BA_ "GenMsgCycleTime" BO_ 1759 200;
BA_ "VAGTP20_DynConnection" BO_ 1193 1;
BA_ "MsgType" BO_ 1193 3;
BA_ "VAGTP20_DynConnection" BO_ 1300 1;
BA_ "MsgType" BO_ 1300 3;
BA_ "VAGTP20_DynConnection" BO_ 1215 1;
BA_ "MsgType" BO_ 1215 3;
BA_ "VAGTP20_DynConnection" BO_ 1303 1;
BA_ "MsgType" BO_ 1303 3;
BA_ "VAGTP20_DynConnection" BO_ 1186 1;
BA_ "MsgType" BO_ 1186 3;
BA_ "VAGTP20_DynConnection" BO_ 1194 1;
BA_ "MsgType" BO_ 1194 3;
BA_ "VAGTP20_DynConnection" BO_ 1190 1;
BA_ "MsgType" BO_ 1190 3;
BA_ "VAGTP20_DynConnection" BO_ 1185 1;
BA_ "MsgType" BO_ 1185 3;
BA_ "VAGTP20_DynConnection" BO_ 1205 1;
BA_ "MsgType" BO_ 1205 3;
BA_ "VAGTP20_DynSetup" BO_ 535 1;
BA_ "MsgType" BO_ 535 3;
BA_ "VAGTP20_DynSetup" BO_ 543 1;
BA_ "MsgType" BO_ 543 3;
BA_ "VAGTP20_DynSetup" BO_ 514 1;
BA_ "MsgType" BO_ 514 3;
BA_ "VAGTP20_DynSetup" BO_ 539 1;
BA_ "MsgType" BO_ 539 3;
BA_ "VAGTP20_DynSetup" BO_ 518 1;
BA_ "MsgType" BO_ 518 3;
BA_ "VAGTP20_DynSetup" BO_ 513 1;
BA_ "MsgType" BO_ 513 3;
BA_ "VAGTP20_DynSetup" BO_ 533 1;
BA_ "MsgType" BO_ 533 3;
BA_ "GenMsgSendType" BO_ 266 0;
BA_ "GenMsgPDUConstants" BO_ 266 "0x0b,0x0b,0x0b,0x0b,0x0b,0x0b,0x0b,0x0b,0x0b,0x0b,0x0b,0x0b,0x0b,0x0b,0x0b,0x0b";
BA_ "GenMsgILSupport" BO_ 266 1;
BA_ "GenMsgCycleTime" BO_ 266 20;
BA_ "GenMsgChkConstant" BO_ 266 11;
BA_ "GenMsgSendType" BO_ 268 0;
BA_ "GenMsgPDUConstants" BO_ 268 "0x0d,0x0d,0x0d,0x0d,0x0d,0x0d,0x0d,0x0d,0x0d,0x0d,0x0d,0x0d,0x0d,0x0d,0x0d,0x0d";
BA_ "GenMsgILSupport" BO_ 268 1;
BA_ "GenMsgCycleTime" BO_ 268 20;
BA_ "GenMsgChkConstant" BO_ 268 13;
BA_ "GenMsgSendType" BO_ 983 0;
BA_ "GenMsgILSupport" BO_ 983 1;
BA_ "GenMsgDelayTime" BO_ 983 50;
BA_ "GenMsgCycleTime" BO_ 983 100;
BA_ "GenMsgSendType" BO_ 912 0;
BA_ "GenMsgILSupport" BO_ 912 1;
BA_ "GenMsgDelayTime" BO_ 912 10;
BA_ "GenMsgCycleTime" BO_ 912 100;
BA_ "MsgType" BO_ 2617009149 6;
BA_ "MsgType" BO_ 2617009150 6;
BA_ "MsgType" BO_ 2617167360 6;
BA_ "MsgType" BO_ 2617167361 6;
BA_ "GenMsgSendType" BO_ 269 0;
BA_ "GenMsgPDUConstants" BO_ 269 "0x0c,0x0c,0x0c,0x0c,0x0c,0x0c,0x0c,0x0c,0x0c,0x0c,0x0c,0x0c,0x0c,0x0c,0x0c,0x0c";
BA_ "GenMsgILSupport" BO_ 269 1;
BA_ "GenMsgCycleTime" BO_ 269 20;
BA_ "GenMsgChkConstant" BO_ 269 12;
BA_ "GenMsgSendType" BO_ 1469 0;
BA_ "GenMsgILSupport" BO_ 1469 1;
BA_ "GenMsgDelayTime" BO_ 1469 50;
BA_ "GenMsgCycleTime" BO_ 1469 500;
BA_ "GenMsgSendType" BO_ 1660 0;
BA_ "GenMsgPDUConstants" BO_ 1660 "0xdf,0xdf,0xdf,0xdf,0xdf,0xdf,0xdf,0xdf,0xdf,0xdf,0xdf,0xdf,0xdf,0xdf,0xdf,0xdf";
BA_ "GenMsgILSupport" BO_ 1660 1;
BA_ "GenMsgCycleTime" BO_ 1660 1000;
BA_ "GenMsgChkConstant" BO_ 1660 223;
BA_ "GenMsgSendType" BO_ 64 0;
BA_ "GenMsgPDUConstants" BO_ 64 "0x40,0x40,0x40,0x40,0x40,0x40,0x40,0x40,0x40,0x40,0x40,0x40,0x40,0x40,0x40,0x40";
BA_ "GenMsgNrOfRepetition" BO_ 64 5;
BA_ "GenMsgILSupport" BO_ 64 1;
BA_ "GenMsgDelayTime" BO_ 64 10;
BA_ "GenMsgCycleTime" BO_ 64 50;
BA_ "GenMsgChkConstant" BO_ 64 64;
BA_ "GenMsgSendType" BO_ 1312 0;
BA_ "GenMsgPDUConstants" BO_ 1312 "0x44,0x44,0x44,0x44,0x44,0x44,0x44,0x44,0x44,0x44,0x44,0x44,0x44,0x44,0x44,0x44";
BA_ "GenMsgILSupport" BO_ 1312 1;
BA_ "GenMsgCycleTime" BO_ 1312 200;
BA_ "GenMsgChkConstant" BO_ 1312 68;
BA_ "GenMsgSendType" BO_ 65 0;
BA_ "GenMsgPDUConstants" BO_ 65 "0x67,0x67,0x67,0x67,0x67,0x67,0x67,0x67,0x67,0x67,0x67,0x67,0x67,0x67,0x67,0x67";
BA_ "GenMsgNrOfRepetition" BO_ 65 5;
BA_ "GenMsgILSupport" BO_ 65 1;
BA_ "GenMsgDelayTime" BO_ 65 10;
BA_ "GenMsgCycleTimeFast" BO_ 65 10;
BA_ "GenMsgCycleTime" BO_ 65 1000;
BA_ "GenMsgChkConstant" BO_ 65 103;
BA_ "GenMsgSendType" BO_ 1633 0;
BA_ "GenMsgILSupport" BO_ 1633 1;
BA_ "GenMsgCycleTime" BO_ 1633 100;
BA_ "MsgType" BO_ 1542 5;
BA_ "MsgType" BO_ 1599 5;
BA_ "MsgType" BO_ 1598 5;
BA_ "MsgType" BO_ 1558 5;
BA_ "MsgType" BO_ 1580 5;
BA_ "GenMsgSendType" BO_ 1409 0;
BA_ "GenMsgILSupport" BO_ 1409 1;
BA_ "GenMsgDelayTime" BO_ 1409 50;
BA_ "GenMsgCycleTime" BO_ 1409 200;
BA_ "GenMsgSendType" BO_ 777 0;
BA_ "GenMsgPDUConstants" BO_ 777 "0x0a,0x0a,0x0a,0x0a,0x0a,0x0a,0x0a,0x0a,0x0a,0x0a,0x0a,0x0a,0x0a,0x0a,0x0a,0x0a";
BA_ "GenMsgILSupport" BO_ 777 1;
BA_ "GenMsgCycleTime" BO_ 777 50;
BA_ "GenMsgChkConstant" BO_ 777 10;
BA_ "GenMsgSendType" BO_ 1635 0;
BA_ "GenMsgILSupport" BO_ 1635 1;
BA_ "GenMsgCycleTime" BO_ 1635 100;
BA_ "GenMsgSendType" BO_ 946 0;
BA_ "GenMsgILSupport" BO_ 946 1;
BA_ "GenMsgCycleTime" BO_ 946 100;
BA_ "GenMsgSendType" BO_ 1628 0;
BA_ "GenMsgILSupport" BO_ 1628 1;
BA_ "GenMsgCycleTime" BO_ 1628 500;
BA_ "MsgType" BO_ 2617239041 6;
BA_ "MsgType" BO_ 482 6;
BA_ "MsgType" BO_ 490 6;
BA_ "MsgType" BO_ 1666 6;
BA_ "MsgType" BO_ 480 6;
BA_ "MsgType" BO_ 2616986624 6;
BA_ "MsgType" BO_ 488 6;
BA_ "MsgType" BO_ 2616986625 6;
BA_ "MsgType" BO_ 481 6;
BA_ "MsgType" BO_ 2616986629 6;
BA_ "MsgType" BO_ 489 6;
BA_ "MsgType" BO_ 2616986630 6;
BA_ "MsgType" BO_ 2617189888 6;
BA_ "MsgType" BO_ 2617189889 6;
BA_ "MsgType" BO_ 2617042432 6;
BA_ "GenSigSendType" SG_ 3221225472 AGA_Charisma_FahrPr 3;
BA_ "GenSigSendType" SG_ 3221225472 AGA_Charisma_Status 3;
BA_ "GenSigSendType" SG_ 3221225472 AGA_Verstaerker_Mute 0;
BA_ "GenSigSendType" SG_ 3221225472 TPS_Airbag_Data 3;
BA_ "GenSigFuncType" SG_ 265 ACC_01_CHK 3;
BA_ "GenSigSendType" SG_ 265 ACC_01_CHK 0;
BA_ "GenSigFuncType" SG_ 265 ACC_01_BZ 1;
BA_ "GenSigSendType" SG_ 265 ACC_01_BZ 0;
BA_ "GenSigSendType" SG_ 265 ACC_zul_Regelabw_unten 0;
BA_ "GenSigStartValue" SG_ 265 ACC_Sollbeschleunigung 1444;
BA_ "GenSigSendType" SG_ 265 ACC_Sollbeschleunigung 0;
BA_ "GenSigSendType" SG_ 265 ACC_zul_Regelabw_oben 0;
BA_ "GenSigSendType" SG_ 265 ACC_neg_Sollbeschl_Grad 0;
BA_ "GenSigSendType" SG_ 265 ACC_pos_Sollbeschl_Grad 0;
BA_ "GenSigSendType" SG_ 265 ACC_Dynamik 0;
BA_ "GenSigSendType" SG_ 265 ACC_Minimale_Bremsung 0;
BA_ "GenSigMissingSourceValue" SG_ 1415 Aero_01_CRC 248;
BA_ "GenSigSwitchedByIgnition" SG_ 1415 Aero_01_CRC 0;
BA_ "GenSigFuncType" SG_ 1415 Aero_01_CRC 2;
BA_ "GenSigSendType" SG_ 1415 Aero_01_CRC 0;
BA_ "GenSigSwitchedByIgnition" SG_ 1415 Aero_01_BZ 0;
BA_ "GenSigFuncType" SG_ 1415 Aero_01_BZ 1;
BA_ "GenSigSendType" SG_ 1415 Aero_01_BZ 0;
BA_ "Fehlerwert" SG_ 1415 Aero_Luftklappe_links_Status 3;
BA_ "GenSigSwitchedByIgnition" SG_ 1415 Aero_Luftklappe_links_Status 0;
BA_ "GenSigSendType" SG_ 1415 Aero_Luftklappe_links_Status 0;
BA_ "Fehlerwert" SG_ 1415 Aero_Luftklappe_rechts_Status 3;
BA_ "GenSigSwitchedByIgnition" SG_ 1415 Aero_Luftklappe_rechts_Status 0;
BA_ "GenSigSendType" SG_ 1415 Aero_Luftklappe_rechts_Status 0;
BA_ "Fehlerwert" SG_ 1415 Aero_Frontspoiler_Status 7;
BA_ "GenSigSwitchedByIgnition" SG_ 1415 Aero_Frontspoiler_Status 0;
BA_ "GenSigSendType" SG_ 1415 Aero_Frontspoiler_Status 0;
BA_ "Fehlerwert" SG_ 1415 Aero_Heckspoiler_Status 7;
BA_ "GenSigSwitchedByIgnition" SG_ 1415 Aero_Heckspoiler_Status 0;
BA_ "GenSigSendType" SG_ 1415 Aero_Heckspoiler_Status 0;
BA_ "Fehlerwert" SG_ 1415 Aero_SCU_Luefter_Status 3;
BA_ "GenSigSwitchedByIgnition" SG_ 1415 Aero_SCU_Luefter_Status 0;
BA_ "GenSigSendType" SG_ 1415 Aero_SCU_Luefter_Status 0;
BA_ "Fehlerwert" SG_ 1415 Aero_Unterdruckpumpe_Status 3;
BA_ "GenSigSwitchedByIgnition" SG_ 1415 Aero_Unterdruckpumpe_Status 0;
BA_ "GenSigSendType" SG_ 1415 Aero_Unterdruckpumpe_Status 0;
BA_ "Fehlerwert" SG_ 1415 Aero_Kamera_Kuehlung_Status 1;
BA_ "GenSigSwitchedByIgnition" SG_ 1415 Aero_Kamera_Kuehlung_Status 0;
BA_ "GenSigSendType" SG_ 1415 Aero_Kamera_Kuehlung_Status 0;
BA_ "GenSigSwitchedByIgnition" SG_ 1415 Aero_EBCS 0;
BA_ "GenSigSendType" SG_ 1415 Aero_EBCS 3;
BA_ "Fehlerwert" SG_ 1415 Aero_Hardtop_Links_Status 3;
BA_ "GenSigSwitchedByIgnition" SG_ 1415 Aero_Hardtop_Links_Status 0;
BA_ "GenSigSendType" SG_ 1415 Aero_Hardtop_Links_Status 0;
BA_ "Fehlerwert" SG_ 1415 Aero_Hardtop_Rechts_Status 3;
BA_ "GenSigSwitchedByIgnition" SG_ 1415 Aero_Hardtop_Rechts_Status 0;
BA_ "GenSigSendType" SG_ 1415 Aero_Hardtop_Rechts_Status 0;
BA_ "Fehlerwert" SG_ 1415 Aero_Max_Performance 3;
BA_ "GenSigSwitchedByIgnition" SG_ 1415 Aero_Max_Performance 0;
BA_ "GenSigSendType" SG_ 1415 Aero_Max_Performance 3;
BA_ "GenSigSwitchedByIgnition" SG_ 1415 Aero_SCAP_Text 0;
BA_ "GenSigSendType" SG_ 1415 Aero_SCAP_Text 3;
BA_ "GenSigSwitchedByIgnition" SG_ 1415 Aero_Frontklappe 0;
BA_ "GenSigSendType" SG_ 1415 Aero_Frontklappe 0;
BA_ "GenSigSwitchedByIgnition" SG_ 1415 AERO_St_LED_HSpoiler 0;
BA_ "Fehlerwert" SG_ 1415 Aero_Sp_IstPos 7;
BA_ "GenSigSwitchedByIgnition" SG_ 1415 Aero_Sp_IstPos 0;
BA_ "GenSigSwitchedByIgnition" SG_ 1415 AERO_W_SpoilerInfo 0;
BA_ "GenSigSwitchedByIgnition" SG_ 1415 Aero_KD_Fehler 0;
BA_ "GenSigSendType" SG_ 1415 Aero_KD_Fehler 0;
BA_ "GenSigFuncType" SG_ 325 Aero_02_CRC 2;
BA_ "GenSigSendType" SG_ 325 Aero_02_CRC 0;
BA_ "GenSigFuncType" SG_ 325 Aero_02_BZ 1;
BA_ "GenSigSendType" SG_ 325 Aero_02_BZ 0;
BA_ "Fehlerwert" SG_ 325 Aero_SCAP_Relais_Status 3;
BA_ "GenSigSwitchedByIgnition" SG_ 325 Aero_SCAP_Relais_Status 0;
BA_ "GenSigSendType" SG_ 325 Aero_SCAP_Relais_Status 0;
BA_ "Fehlerwert" SG_ 325 Aero_SCAP_Status 3;
BA_ "GenSigSwitchedByIgnition" SG_ 325 Aero_SCAP_Status 0;
BA_ "GenSigStartValue" SG_ 325 Aero_SCAP_Status 2;
BA_ "GenSigSendType" SG_ 325 Aero_SCAP_Status 0;
BA_ "GenSigSendType" SG_ 325 AERO_StartStopp_Info 0;
BA_ "GenSigSwitchedByIgnition" SG_ 867 BM_ZV_auf 0;
BA_ "GenSigSendType" SG_ 867 BM_ZV_auf 6;
BA_ "GenSigActiveRepetitions" SG_ 867 BM_ZV_auf 5;
BA_ "GenSigSwitchedByIgnition" SG_ 867 BM_ZV_zu 0;
BA_ "GenSigSendType" SG_ 867 BM_ZV_zu 6;
BA_ "GenSigActiveRepetitions" SG_ 867 BM_ZV_zu 5;
BA_ "GenSigSwitchedByIgnition" SG_ 867 BM_DWA_ein 0;
BA_ "GenSigSendType" SG_ 867 BM_DWA_ein 6;
BA_ "GenSigActiveRepetitions" SG_ 867 BM_DWA_ein 5;
BA_ "GenSigSwitchedByIgnition" SG_ 867 BM_DWA_Alarm 0;
BA_ "GenSigSendType" SG_ 867 BM_DWA_Alarm 6;
BA_ "GenSigActiveRepetitions" SG_ 867 BM_DWA_Alarm 5;
BA_ "GenSigSwitchedByIgnition" SG_ 867 BM_Crash 0;
BA_ "GenSigSendType" SG_ 867 BM_Crash 6;
BA_ "GenSigActiveRepetitions" SG_ 867 BM_Crash 5;
BA_ "GenSigSwitchedByIgnition" SG_ 867 BM_Panik 0;
BA_ "GenSigSendType" SG_ 867 BM_Panik 6;
BA_ "GenSigActiveRepetitions" SG_ 867 BM_Panik 5;
BA_ "GenSigSwitchedByIgnition" SG_ 867 BM_Not_Bremsung 0;
BA_ "GenSigSendType" SG_ 867 BM_Not_Bremsung 6;
BA_ "GenSigActiveRepetitions" SG_ 867 BM_Not_Bremsung 5;
BA_ "GenSigSwitchedByIgnition" SG_ 867 BM_GDO 0;
BA_ "GenSigSendType" SG_ 867 BM_GDO 6;
BA_ "GenSigActiveRepetitions" SG_ 867 BM_GDO 5;
BA_ "GenSigSwitchedByIgnition" SG_ 867 BM_links 0;
BA_ "GenSigSendType" SG_ 867 BM_links 6;
BA_ "GenSigActiveRepetitions" SG_ 867 BM_links 5;
BA_ "GenSigSwitchedByIgnition" SG_ 867 BM_rechts 0;
BA_ "GenSigSendType" SG_ 867 BM_rechts 6;
BA_ "GenSigActiveRepetitions" SG_ 867 BM_rechts 5;
BA_ "GenSigSwitchedByIgnition" SG_ 867 BM_Warnblinken 0;
BA_ "GenSigSendType" SG_ 867 BM_Warnblinken 6;
BA_ "GenSigActiveRepetitions" SG_ 867 BM_Warnblinken 5;
BA_ "GenSigSwitchedByIgnition" SG_ 867 BM_Taxi_Notalarm 0;
BA_ "GenSigSendType" SG_ 867 BM_Taxi_Notalarm 6;
BA_ "GenSigActiveRepetitions" SG_ 867 BM_Taxi_Notalarm 5;
BA_ "GenSigSwitchedByIgnition" SG_ 867 BM_Telematik 0;
BA_ "GenSigSendType" SG_ 867 BM_Telematik 6;
BA_ "GenSigActiveRepetitions" SG_ 867 BM_Telematik 5;
BA_ "GenSigSwitchedByIgnition" SG_ 867 BM_HD_Oeffnung_angelernt 0;
BA_ "GenSigSendType" SG_ 867 BM_HD_Oeffnung_angelernt 6;
BA_ "GenSigActiveRepetitions" SG_ 867 BM_HD_Oeffnung_angelernt 5;
BA_ "GenSigSwitchedByIgnition" SG_ 867 BM_WBT_Beleuchtung 0;
BA_ "GenSigSendType" SG_ 867 BM_WBT_Beleuchtung 6;
BA_ "GenSigActiveRepetitions" SG_ 867 BM_WBT_Beleuchtung 5;
BA_ "GenSigSwitchedByIgnition" SG_ 867 Blinken_li_Fzg_Takt 0;
BA_ "GenSigSendType" SG_ 867 Blinken_li_Fzg_Takt 6;
BA_ "GenSigActiveRepetitions" SG_ 867 Blinken_li_Fzg_Takt 5;
BA_ "GenSigSwitchedByIgnition" SG_ 867 Blinken_re_Fzg_Takt 0;
BA_ "GenSigSendType" SG_ 867 Blinken_re_Fzg_Takt 6;
BA_ "GenSigActiveRepetitions" SG_ 867 Blinken_re_Fzg_Takt 5;
BA_ "GenSigSwitchedByIgnition" SG_ 867 Blinken_li_Kombi_Takt 0;
BA_ "GenSigSendType" SG_ 867 Blinken_li_Kombi_Takt 6;
BA_ "GenSigActiveRepetitions" SG_ 867 Blinken_li_Kombi_Takt 5;
BA_ "GenSigSwitchedByIgnition" SG_ 867 Blinken_re_Kombi_Takt 0;
BA_ "GenSigSendType" SG_ 867 Blinken_re_Kombi_Takt 6;
BA_ "GenSigActiveRepetitions" SG_ 867 Blinken_re_Kombi_Takt 5;
BA_ "GenSigSwitchedByIgnition" SG_ 867 BM_NBA_n_codiert_n_aktiv 0;
BA_ "GenSigStartValue" SG_ 867 BM_NBA_n_codiert_n_aktiv 1;
BA_ "GenSigSendType" SG_ 867 BM_NBA_n_codiert_n_aktiv 5;
BA_ "GenSigSwitchedByIgnition" SG_ 867 BM_NBA_Status 0;
BA_ "GenSigSendType" SG_ 867 BM_NBA_Status 5;
BA_ "GenSigSwitchedByIgnition" SG_ 867 Blinken_FWB_aktiv 0;
BA_ "GenSigSendType" SG_ 867 Blinken_FWB_aktiv 6;
BA_ "GenSigActiveRepetitions" SG_ 867 Blinken_FWB_aktiv 5;
BA_ "GenSigFuncType" SG_ 264 Fahrwerk_01_CHK 3;
BA_ "GenSigSendType" SG_ 264 Fahrwerk_01_CHK 0;
BA_ "GenSigFuncType" SG_ 264 Fahrwerk_01_BZ 1;
BA_ "GenSigSendType" SG_ 264 Fahrwerk_01_BZ 0;
BA_ "GenSigSendType" SG_ 264 FA_Hoehenwerte_kalibriert 0;
BA_ "GenSigSendType" SG_ 264 FA_ESP_Zuschaltung 0;
BA_ "Fehlerwert" SG_ 264 FA_Hoehenwert_VL_00 255;
BA_ "GenSigStartValue" SG_ 264 FA_Hoehenwert_VL_00 254;
BA_ "Fehlerwert" SG_ 264 FA_Hoehenwert_VL_01 255;
BA_ "GenSigStartValue" SG_ 264 FA_Hoehenwert_VL_01 254;
BA_ "Fehlerwert" SG_ 264 FA_Hoehenwert_VR_00 255;
BA_ "GenSigStartValue" SG_ 264 FA_Hoehenwert_VR_00 254;
BA_ "Fehlerwert" SG_ 264 FA_Hoehenwert_VR_01 255;
BA_ "GenSigStartValue" SG_ 264 FA_Hoehenwert_VR_01 254;
BA_ "Fehlerwert" SG_ 264 FA_Hoehenwert_HL_00 255;
BA_ "GenSigStartValue" SG_ 264 FA_Hoehenwert_HL_00 254;
BA_ "Fehlerwert" SG_ 264 FA_Hoehenwert_HL_01 255;
BA_ "GenSigStartValue" SG_ 264 FA_Hoehenwert_HL_01 254;
BA_ "Fehlerwert" SG_ 264 FA_Hoehenwert_HR_00 255;
BA_ "GenSigStartValue" SG_ 264 FA_Hoehenwert_HR_00 254;
BA_ "Fehlerwert" SG_ 264 FA_Hoehenwert_HR_01 255;
BA_ "GenSigStartValue" SG_ 264 FA_Hoehenwert_HR_01 254;
BA_ "GenSigSwitchedByIgnition" SG_ 1138 Anhaenger_01_alt 0;
BA_ "GenSigFuncType" SG_ 1138 Anhaenger_01_alt 5;
BA_ "GenSigStartValue" SG_ 1138 Anhaenger_01_alt 1;
BA_ "GenSigSendType" SG_ 1138 Anhaenger_01_alt 0;
BA_ "GenSigSwitchedByIgnition" SG_ 1138 GW_MED9_01_va_11 0;
BA_ "GenSigStartValue" SG_ 1138 GW_MED9_01_va_11 1;
BA_ "GenSigSendType" SG_ 1138 GW_MED9_01_va_11 0;
BA_ "GenSigSwitchedByIgnition" SG_ 1138 Kombi_01_alt 0;
BA_ "GenSigFuncType" SG_ 1138 Kombi_01_alt 5;
BA_ "GenSigStartValue" SG_ 1138 Kombi_01_alt 1;
BA_ "GenSigSendType" SG_ 1138 Kombi_01_alt 0;
BA_ "GenSigSwitchedByIgnition" SG_ 1138 STH_01_alt 0;
BA_ "GenSigFuncType" SG_ 1138 STH_01_alt 5;
BA_ "GenSigStartValue" SG_ 1138 STH_01_alt 1;
BA_ "GenSigSendType" SG_ 1138 STH_01_alt 0;
BA_ "GenSigSwitchedByIgnition" SG_ 1138 Licht_hinten_01_alt 0;
BA_ "GenSigFuncType" SG_ 1138 Licht_hinten_01_alt 5;
BA_ "GenSigStartValue" SG_ 1138 Licht_hinten_01_alt 1;
BA_ "GenSigSendType" SG_ 1138 Licht_hinten_01_alt 0;
BA_ "GenSigSwitchedByIgnition" SG_ 1138 GW_MED9_01_va_15 0;
BA_ "GenSigStartValue" SG_ 1138 GW_MED9_01_va_15 1;
BA_ "GenSigSendType" SG_ 1138 GW_MED9_01_va_15 0;
BA_ "GenSigSwitchedByIgnition" SG_ 1138 GW_MED9_01_va_16 0;
BA_ "GenSigStartValue" SG_ 1138 GW_MED9_01_va_16 1;
BA_ "GenSigSendType" SG_ 1138 GW_MED9_01_va_16 0;
BA_ "GenSigSwitchedByIgnition" SG_ 1138 GW_MED9_01_va_17 0;
BA_ "GenSigStartValue" SG_ 1138 GW_MED9_01_va_17 1;
BA_ "GenSigSendType" SG_ 1138 GW_MED9_01_va_17 0;
BA_ "GenSigSwitchedByIgnition" SG_ 1906 ISO_Daempfer_Req_Data 0;
BA_ "GenSigFuncType" SG_ 1906 ISO_Daempfer_Req_Data 9;
BA_ "GenSigSendType" SG_ 1906 ISO_Daempfer_Req_Data 3;
BA_ "GenSigSwitchedByIgnition" SG_ 2012 ISO_Daempfer_Resp_Data 0;
BA_ "GenSigFuncType" SG_ 2012 ISO_Daempfer_Resp_Data 9;
BA_ "GenSigSendType" SG_ 2012 ISO_Daempfer_Resp_Data 3;
BA_ "GenSigSwitchedByIgnition" SG_ 1876 ISO_LWRAFS_Req_Data 0;
BA_ "GenSigSendType" SG_ 1876 ISO_LWRAFS_Req_Data 3;
BA_ "GenSigSwitchedByIgnition" SG_ 1982 ISO_LWRAFS_Resp_Data 0;
BA_ "GenSigSendType" SG_ 1982 ISO_LWRAFS_Resp_Data 3;
BA_ "GenSigSwitchedByIgnition" SG_ 2019 ISO_OBD_02_Req_Data 0;
BA_ "GenSigSendType" SG_ 2019 ISO_OBD_02_Req_Data 3;
BA_ "GenSigSwitchedByIgnition" SG_ 2027 ISO_OBD_02_Resp_Data 0;
BA_ "GenSigSendType" SG_ 2027 ISO_OBD_02_Resp_Data 3;
BA_ "GenSigSwitchedByIgnition" SG_ 2023 ISO_OBD_06_Req_Data 0;
BA_ "GenSigSendType" SG_ 2023 ISO_OBD_06_Req_Data 3;
BA_ "GenSigSwitchedByIgnition" SG_ 2031 ISO_OBD_06_Resp_Data 0;
BA_ "GenSigSendType" SG_ 2031 ISO_OBD_06_Resp_Data 3;
BA_ "GenSigSwitchedByIgnition" SG_ 1347 Lift_02_CHK 0;
BA_ "GenSigFuncType" SG_ 1347 Lift_02_CHK 3;
BA_ "GenSigSendType" SG_ 1347 Lift_02_CHK 0;
BA_ "GenSigSwitchedByIgnition" SG_ 1347 Lift_02_BZ 0;
BA_ "GenSigFuncType" SG_ 1347 Lift_02_BZ 1;
BA_ "GenSigSendType" SG_ 1347 Lift_02_BZ 0;
BA_ "Fehlerwert" SG_ 1347 Lift_Status 7;
BA_ "GenSigSendType" SG_ 1347 Lift_Status 3;
BA_ "GenSigSwitchedByIgnition" SG_ 1347 Lift_Charisma_FahrPr 0;
BA_ "GenSigSendType" SG_ 1347 Lift_Charisma_FahrPr 3;
BA_ "GenSigSwitchedByIgnition" SG_ 1347 Lift_Charisma_Status 0;
BA_ "GenSigSendType" SG_ 1347 Lift_Charisma_Status 3;
BA_ "GenSigSwitchedByIgnition" SG_ 1347 Lift_Charisma_Umschaltung 0;
BA_ "GenSigSendType" SG_ 1347 Lift_Charisma_Umschaltung 3;
BA_ "GenSigSendType" SG_ 1347 Lift_KD_Fehler 0;
BA_ "GenSigSendType" SG_ 917 AFS_Abbiegelicht_li_Anf 0;
BA_ "GenSigSendType" SG_ 917 AFS_Abbiegelicht_re_Anf 0;
BA_ "GenSigSendType" SG_ 917 AFS_Abbiegelicht_Dimm_Anf 0;
BA_ "GenSigStartValue" SG_ 917 AFS_Verfuegbarkeit_GLW 1;
BA_ "GenSigSendType" SG_ 917 AFS_Verfuegbarkeit_GLW 0;
BA_ "GenSigStartValue" SG_ 917 AFS_Status_adaptive_LV 1;
BA_ "GenSigSendType" SG_ 917 AFS_Status_adaptive_LV 0;
BA_ "GenSigSendType" SG_ 917 AFS_Fernlicht_li_defekt 0;
BA_ "GenSigSendType" SG_ 917 AFS_Fernlicht_re_defekt 0;
BA_ "GenSigSendType" SG_ 917 AFS_Fernlicht_Status 0;
BA_ "GenSigFuncType" SG_ 917 LWR_AFS_01_BZ 1;
BA_ "GenSigSendType" SG_ 917 LWR_AFS_01_BZ 0;
BA_ "GenSigSendType" SG_ 917 AFS_Lampe 0;
BA_ "GenSigSendType" SG_ 917 LWR_Lampe 0;
BA_ "GenSigSendType" SG_ 917 AFS_Fehlertext 0;
BA_ "GenSigSendType" SG_ 917 AFS_LED_Blinkmode 0;
BA_ "GenSigSendType" SG_ 917 LWR_Touristenmodus_aktiv 0;
BA_ "GenSigSendType" SG_ 917 AFS_Charisma_FahrPr 0;
BA_ "GenSigSendType" SG_ 917 AFS_Charisma_Status 0;
BA_ "GenSigSendType" SG_ 917 AFS_Charisma_Umschaltung 0;
BA_ "GenSigSendType" SG_ 917 AFS_Allwetterlicht 0;
BA_ "GenSigSendType" SG_ 917 LWR_Touristenmodus_verbaut 0;
BA_ "GenSigSendType" SG_ 917 AFS_adaptive_LV_verbaut 0;
BA_ "GenSigSendType" SG_ 917 LWR_Reisemodus_Texte 0;
BA_ "GenSigSendType" SG_ 917 GLW_Sensor_blockiert 0;
BA_ "Fehlerwert" SG_ 917 LWR_Pos_Schrittmotor 255;
BA_ "GenSigStartValue" SG_ 917 LWR_Pos_Schrittmotor 254;
BA_ "GenSigSendType" SG_ 917 LWR_Pos_Schrittmotor 0;
BA_ "Fehlerwert" SG_ 917 LWR_Hoehenwert_VL 255;
BA_ "GenSigStartValue" SG_ 917 LWR_Hoehenwert_VL 254;
BA_ "GenSigSendType" SG_ 917 LWR_Hoehenwert_VL 0;
BA_ "Fehlerwert" SG_ 917 LWR_Hoehenwert_HL 255;
BA_ "GenSigStartValue" SG_ 917 LWR_Hoehenwert_HL 254;
BA_ "GenSigSendType" SG_ 917 LWR_Hoehenwert_HL 0;
BA_ "GenSigSendType" SG_ 917 AFS_Ersatzlicht_Links 0;
BA_ "GenSigSendType" SG_ 917 AFS_Ersatzlicht_Rechts 0;
BA_ "GenSigSendType" SG_ 917 LWR_AFS_Grundeinstellung 0;
BA_ "GenSigSendType" SG_ 917 LWR_AFS_Parametrisierung 0;
BA_ "GenSigSendType" SG_ 917 LWR_Initialisierungslauf 0;
BA_ "GenSigSendType" SG_ 917 LWR_Sicherheitsposition 0;
BA_ "GenSigSendType" SG_ 917 LWR_Modus 0;
BA_ "GenSigSendType" SG_ 917 LWR_KD_Fehler 0;
BA_ "GenSigSwitchedByIgnition" SG_ 1759 NMH_Aero_Start_1 0;
BA_ "GenSigSwitchedByIgnition" SG_ 1759 NMH_Aero_Start_2 0;
BA_ "GenSigSwitchedByIgnition" SG_ 1759 NMH_Aero_Normal_Mode_1 0;
BA_ "GenSigSwitchedByIgnition" SG_ 1759 NMH_Aero_Normal_Mode_2 0;
BA_ "GenSigSwitchedByIgnition" SG_ 1759 NMH_Aero_Car_WakeUp 0;
BA_ "GenSigSwitchedByIgnition" SG_ 1759 NMH_Aero_Per_WakeUp 0;
BA_ "NWM-WakeupAllowed" SG_ 1759 NMH_Aero_Per_WakeUp 1;
BA_ "GenSigSwitchedByIgnition" SG_ 1759 NMH_Aero_Fkt_WakeUp 0;
BA_ "NWM-WakeupAllowed" SG_ 1759 NMH_Aero_Fkt_WakeUp 1;
BA_ "GenSigSwitchedByIgnition" SG_ 1759 NMH_Aero_Klemme_15 0;
BA_ "GenSigSwitchedByIgnition" SG_ 1759 NMH_Aero_Diagnose 0;
BA_ "GenSigSwitchedByIgnition" SG_ 1759 NMH_Aero_MindestAktivZeit 0;
BA_ "GenSigSwitchedByIgnition" SG_ 1759 NMH_Aero_NL_Datem_EEPROM 0;
BA_ "GenSigSwitchedByIgnition" SG_ 1759 NMH_Aero_Signalfehler 0;
BA_ "GenSigSwitchedByIgnition" SG_ 1759 NMH_Aero_TimeOut_Fehler 0;
BA_ "GenSigSwitchedByIgnition" SG_ 1759 NMH_Aero_CAN_Diag_deaktiv 0;
BA_ "GenSigSwitchedByIgnition" SG_ 1759 NMH_Aero_KompSchutz 0;
BA_ "GenSigSwitchedByIgnition" SG_ 1759 NMH_Aero_Mute_Mode 0;
BA_ "GenSigSwitchedByIgnition" SG_ 1759 NMH_Aero_Transport_Mode 0;
BA_ "GenSigSwitchedByIgnition" SG_ 1759 NMH_Aero_Abschaltstufe_aktiv 0;
BA_ "GenSigSwitchedByIgnition" SG_ 1759 NMH_Aero_Busfehler 0;
BA_ "GenSigSwitchedByIgnition" SG_ 1759 NMH_Aero_Lokalaktiv 0;
BA_ "GenSigSwitchedByIgnition" SG_ 1759 NMH_Aero_Subsystemaktiv 0;
BA_ "GenSigSwitchedByIgnition" SG_ 1193 TPD_Aerodynamik_Data_1 0;
BA_ "GenSigSendType" SG_ 1193 TPD_Aerodynamik_Data_1 3;
BA_ "GenSigSwitchedByIgnition" SG_ 1300 TPD_Airbag_Data_2 0;
BA_ "GenSigSendType" SG_ 1300 TPD_Airbag_Data_2 3;
BA_ "GenSigSendType" SG_ 1215 TPD_Gateway_Data_1 3;
BA_ "GenSigSendType" SG_ 1303 TPD_Gateway_Data_2 3;
BA_ "GenSigSwitchedByIgnition" SG_ 1186 TPD_Getriebe_Data_1 0;
BA_ "GenSigSendType" SG_ 1186 TPD_Getriebe_Data_1 3;
BA_ "GenSigSwitchedByIgnition" SG_ 1194 TPD_Lifting_Data 0;
BA_ "GenSigSendType" SG_ 1194 TPD_Lifting_Data 3;
BA_ "GenSigSwitchedByIgnition" SG_ 1190 TPD_LWR_AFS_Data_1 0;
BA_ "GenSigSendType" SG_ 1190 TPD_LWR_AFS_Data_1 3;
BA_ "GenSigSwitchedByIgnition" SG_ 1185 TPD_Motor_Data_1 0;
BA_ "GenSigSendType" SG_ 1185 TPD_Motor_Data_1 3;
BA_ "GenSigSwitchedByIgnition" SG_ 1205 TPD_MotorS_Data_1 0;
BA_ "GenSigSendType" SG_ 1205 TPD_MotorS_Data_1 3;
BA_ "GenSigSwitchedByIgnition" SG_ 535 TPS_Aerodynamik_Data 0;
BA_ "GenSigSendType" SG_ 535 TPS_Aerodynamik_Data 3;
BA_ "GenSigSwitchedByIgnition" SG_ 543 TPS_Gateway_Data 0;
BA_ "GenSigSendType" SG_ 543 TPS_Gateway_Data 3;
BA_ "GenSigSwitchedByIgnition" SG_ 514 TPS_Getriebe_Data 0;
BA_ "GenSigSendType" SG_ 514 TPS_Getriebe_Data 3;
BA_ "GenSigSwitchedByIgnition" SG_ 539 TPS_Lifting_Data 0;
BA_ "GenSigSendType" SG_ 539 TPS_Lifting_Data 3;
BA_ "GenSigSwitchedByIgnition" SG_ 518 TPS_LWR_AFS_Data 0;
BA_ "GenSigSendType" SG_ 518 TPS_LWR_AFS_Data 3;
BA_ "GenSigSwitchedByIgnition" SG_ 513 TPS_Motor_Data 0;
BA_ "GenSigSendType" SG_ 513 TPS_Motor_Data 3;
BA_ "GenSigSwitchedByIgnition" SG_ 533 TPS_MotorS_Data 0;
BA_ "GenSigSendType" SG_ 533 TPS_MotorS_Data 3;
BA_ "GenSigSwitchedByIgnition" SG_ 266 TSK_01_CHK 0;
BA_ "GenSigFuncType" SG_ 266 TSK_01_CHK 3;
BA_ "GenSigSendType" SG_ 266 TSK_01_CHK 0;
BA_ "GenSigSwitchedByIgnition" SG_ 266 TSK_01_BZ 0;
BA_ "GenSigFuncType" SG_ 266 TSK_01_BZ 1;
BA_ "GenSigSendType" SG_ 266 TSK_01_BZ 0;
BA_ "GenSigSwitchedByIgnition" SG_ 266 TSK_Status_AB 0;
BA_ "GenSigSendType" SG_ 266 TSK_Status_AB 0;
BA_ "GenSigSwitchedByIgnition" SG_ 266 TSK_amax_moeglich 0;
BA_ "GenSigStartValue" SG_ 266 TSK_amax_moeglich 84;
BA_ "GenSigSendType" SG_ 266 TSK_amax_moeglich 0;
BA_ "GenSigSwitchedByIgnition" SG_ 268 TSK_02_CHK 0;
BA_ "GenSigFuncType" SG_ 268 TSK_02_CHK 3;
BA_ "GenSigSendType" SG_ 268 TSK_02_CHK 0;
BA_ "GenSigSwitchedByIgnition" SG_ 268 TSK_02_BZ 0;
BA_ "GenSigFuncType" SG_ 268 TSK_02_BZ 1;
BA_ "GenSigSendType" SG_ 268 TSK_02_BZ 0;
BA_ "GenSigSwitchedByIgnition" SG_ 268 TSK_Anhalten 0;
BA_ "GenSigSendType" SG_ 268 TSK_Anhalten 0;
BA_ "GenSigSwitchedByIgnition" SG_ 268 TSK_Radbremsmom 0;
BA_ "GenSigSendType" SG_ 268 TSK_Radbremsmom 0;
BA_ "GenSigSwitchedByIgnition" SG_ 268 TSK_Standby_Anf_ESP 0;
BA_ "GenSigSendType" SG_ 268 TSK_Standby_Anf_ESP 0;
BA_ "GenSigSwitchedByIgnition" SG_ 268 TSK_Verzoeg_Anf 0;
BA_ "GenSigStartValue" SG_ 268 TSK_Verzoeg_Anf 166;
BA_ "GenSigSendType" SG_ 268 TSK_Verzoeg_Anf 0;
BA_ "GenSigSwitchedByIgnition" SG_ 983 VS_FH_FT_hoch 0;
BA_ "GenSigSendType" SG_ 983 VS_FH_FT_hoch 3;
BA_ "GenSigSwitchedByIgnition" SG_ 983 VS_FH_FT_Langhub 0;
BA_ "GenSigSendType" SG_ 983 VS_FH_FT_Langhub 3;
BA_ "GenSigSwitchedByIgnition" SG_ 983 VS_FH_BT_hoch 0;
BA_ "GenSigSendType" SG_ 983 VS_FH_BT_hoch 3;
BA_ "GenSigSwitchedByIgnition" SG_ 983 VS_FH_BT_Langhub 0;
BA_ "GenSigSendType" SG_ 983 VS_FH_BT_Langhub 3;
BA_ "GenSigSwitchedByIgnition" SG_ 983 VS_FH_HL_hoch 0;
BA_ "GenSigSendType" SG_ 983 VS_FH_HL_hoch 3;
BA_ "GenSigSwitchedByIgnition" SG_ 983 VS_FH_HL_Langhub 0;
BA_ "GenSigSendType" SG_ 983 VS_FH_HL_Langhub 3;
BA_ "GenSigSwitchedByIgnition" SG_ 983 VS_FH_HR_hoch 0;
BA_ "GenSigSendType" SG_ 983 VS_FH_HR_hoch 3;
BA_ "GenSigSwitchedByIgnition" SG_ 983 VS_FH_HR_Langhub 0;
BA_ "GenSigSendType" SG_ 983 VS_FH_HR_Langhub 3;
BA_ "GenSigSwitchedByIgnition" SG_ 983 VS_KD_Fehler 0;
BA_ "GenSigSendType" SG_ 983 VS_KD_Fehler 3;
BA_ "GenSigSwitchedByIgnition" SG_ 983 VS_VD_zu_ver 0;
BA_ "GenSigSendType" SG_ 983 VS_VD_zu_ver 3;
BA_ "GenSigSwitchedByIgnition" SG_ 983 VS_VD_entriegelt 0;
BA_ "GenSigSendType" SG_ 983 VS_VD_entriegelt 3;
BA_ "GenSigSwitchedByIgnition" SG_ 983 VS_VD_offen_ver 0;
BA_ "GenSigSendType" SG_ 983 VS_VD_offen_ver 3;
BA_ "GenSigSwitchedByIgnition" SG_ 983 VS_VD_Zwischenposition 0;
BA_ "GenSigSendType" SG_ 983 VS_VD_Zwischenposition 3;
BA_ "GenSigSwitchedByIgnition" SG_ 983 VS_VD_Bew_auf 0;
BA_ "GenSigSendType" SG_ 983 VS_VD_Bew_auf 3;
BA_ "GenSigSwitchedByIgnition" SG_ 983 VS_VD_Bew_zu 0;
BA_ "GenSigSendType" SG_ 983 VS_VD_Bew_zu 3;
BA_ "GenSigSwitchedByIgnition" SG_ 983 VS_Verdeck_Anf 0;
BA_ "GenSigSendType" SG_ 983 VS_Verdeck_Anf 3;
BA_ "GenSigSwitchedByIgnition" SG_ 983 VS_Hardtop 0;
BA_ "GenSigSendType" SG_ 983 VS_Hardtop 3;
BA_ "GenSigSwitchedByIgnition" SG_ 983 VS_VD_Fehler 0;
BA_ "GenSigSendType" SG_ 983 VS_VD_Fehler 3;
BA_ "GenSigSwitchedByIgnition" SG_ 983 VS_Lampe_Blk 0;
BA_ "GenSigSendType" SG_ 983 VS_Lampe_Blk 3;
BA_ "GenSigSwitchedByIgnition" SG_ 983 VS_Buzzer 0;
BA_ "GenSigSendType" SG_ 983 VS_Buzzer 3;
BA_ "GenSigSwitchedByIgnition" SG_ 983 VS_HD_sperren 0;
BA_ "GenSigSendType" SG_ 983 VS_HD_sperren 3;
BA_ "GenSigSwitchedByIgnition" SG_ 983 VS_HHS_enable 0;
BA_ "GenSigSendType" SG_ 983 VS_HHS_enable 3;
BA_ "GenSigSwitchedByIgnition" SG_ 983 VS_VVW_unten 0;
BA_ "GenSigSendType" SG_ 983 VS_VVW_unten 3;
BA_ "GenSigSwitchedByIgnition" SG_ 983 VSG_FT_FH_BT_ManHoch 0;
BA_ "GenSigSendType" SG_ 983 VSG_FT_FH_BT_ManHoch 3;
BA_ "GenSigSwitchedByIgnition" SG_ 983 VSG_FT_FH_BT_AutoHoch 0;
BA_ "GenSigSendType" SG_ 983 VSG_FT_FH_BT_AutoHoch 3;
BA_ "GenSigSwitchedByIgnition" SG_ 983 VSG_FT_FH_BT_ManTief 0;
BA_ "GenSigSendType" SG_ 983 VSG_FT_FH_BT_ManTief 3;
BA_ "GenSigSwitchedByIgnition" SG_ 983 VSG_FT_FH_BT_AutoTief 0;
BA_ "GenSigSendType" SG_ 983 VSG_FT_FH_BT_AutoTief 3;
BA_ "GenSigSwitchedByIgnition" SG_ 983 VSG_FT_FH_FT_ManHoch 0;
BA_ "GenSigSendType" SG_ 983 VSG_FT_FH_FT_ManHoch 3;
BA_ "GenSigSwitchedByIgnition" SG_ 983 VSG_FT_FH_FT_AutoHoch 0;
BA_ "GenSigSendType" SG_ 983 VSG_FT_FH_FT_AutoHoch 3;
BA_ "GenSigSwitchedByIgnition" SG_ 983 VSG_FT_FH_FT_ManTief 0;
BA_ "GenSigSendType" SG_ 983 VSG_FT_FH_FT_ManTief 3;
BA_ "GenSigSwitchedByIgnition" SG_ 983 VSG_FT_FH_FT_AutoTief 0;
BA_ "GenSigSendType" SG_ 983 VSG_FT_FH_FT_AutoTief 3;
BA_ "GenSigSwitchedByIgnition" SG_ 983 VSG_FT_FH_HL_ManHoch 0;
BA_ "GenSigSendType" SG_ 983 VSG_FT_FH_HL_ManHoch 3;
BA_ "GenSigSwitchedByIgnition" SG_ 983 VSG_FT_FH_HL_AutoHoch 0;
BA_ "GenSigSendType" SG_ 983 VSG_FT_FH_HL_AutoHoch 3;
BA_ "GenSigSwitchedByIgnition" SG_ 983 VSG_FT_FH_HL_ManTief 0;
BA_ "GenSigSendType" SG_ 983 VSG_FT_FH_HL_ManTief 3;
BA_ "GenSigSwitchedByIgnition" SG_ 983 VSG_FT_FH_HL_AutoTief 0;
BA_ "GenSigSendType" SG_ 983 VSG_FT_FH_HL_AutoTief 3;
BA_ "GenSigSwitchedByIgnition" SG_ 983 VSG_FT_FH_HR_ManHoch 0;
BA_ "GenSigSendType" SG_ 983 VSG_FT_FH_HR_ManHoch 3;
BA_ "GenSigSwitchedByIgnition" SG_ 983 VSG_FT_FH_HR_AutoHoch 0;
BA_ "GenSigSendType" SG_ 983 VSG_FT_FH_HR_AutoHoch 3;
BA_ "GenSigSwitchedByIgnition" SG_ 983 VSG_FT_FH_HR_ManTief 0;
BA_ "GenSigSendType" SG_ 983 VSG_FT_FH_HR_ManTief 3;
BA_ "GenSigSwitchedByIgnition" SG_ 983 VSG_FT_FH_HR_AutoTief 0;
BA_ "GenSigSendType" SG_ 983 VSG_FT_FH_HR_AutoTief 3;
BA_ "GenSigSwitchedByIgnition" SG_ 983 VS_Texte 0;
BA_ "GenSigSendType" SG_ 983 VS_Texte 3;
BA_ "GenSigSwitchedByIgnition" SG_ 912 WBA_WH_Sleep_ACK_alt 0;
BA_ "GenSigSendType" SG_ 912 WBA_WH_Sleep_ACK_alt 3;
BA_ "GenSigSendType" SG_ 912 GE_Warnung_Auto_N_LB 0;
BA_ "GenSigSendType" SG_ 912 WBA_GE_Fastshift 0;
BA_ "GenSigSwitchedByIgnition" SG_ 912 WBA_GE_Textmeldungen 0;
BA_ "GenSigSendType" SG_ 912 WBA_GE_Textmeldungen 3;
BA_ "GenSigSwitchedByIgnition" SG_ 2617009149 XCP_Daempfer_CRO_01_Data 0;
BA_ "GenSigSwitchedByIgnition" SG_ 2617009150 XCP_Daempfer_DTO_01_Data 0;
BA_ "GenSigSwitchedByIgnition" SG_ 2617167360 XCP_Lift_CRO_01_Data 0;
BA_ "GenSigSwitchedByIgnition" SG_ 2617167361 XCP_Lift_DTO_01_Data 0;
BA_ "GenSigFuncType" SG_ 269 ACC_05_CHK 3;
BA_ "GenSigSendType" SG_ 269 ACC_05_CHK 0;
BA_ "GenSigFuncType" SG_ 269 ACC_05_BZ 1;
BA_ "GenSigSendType" SG_ 269 ACC_05_BZ 0;
BA_ "GenSigSendType" SG_ 269 ACC_Freigabe_Momentenanf 0;
BA_ "GenSigSendType" SG_ 269 ACC_Freigabe_Verzanf 0;
BA_ "GenSigSendType" SG_ 269 ACC_Getriebestellung_P 0;
BA_ "GenSigSendType" SG_ 269 ACC_limitierte_Anfahrdyn 0;
BA_ "GenSigSendType" SG_ 269 ACC_Momentenanforderung 0;
BA_ "GenSigSendType" SG_ 269 ACC_zul_Regelabw 0;
BA_ "GenSigStartValue" SG_ 269 ACC_Verz_anf 1444;
BA_ "GenSigSendType" SG_ 269 ACC_Verz_anf 0;
BA_ "GenSigSendType" SG_ 269 ACC_Loeseanforderung 0;
BA_ "GenSigSendType" SG_ 269 ACC_StartStopp_Info 0;
BA_ "GenSigSendType" SG_ 269 ACC_Segelveto 0;
BA_ "GenSigSendType" SG_ 269 ACC_Vorbefuellung_Bremsanlage 0;
BA_ "GenSigStartValue" SG_ 269 ACC_ax_Getriebe 84;
BA_ "GenSigSendType" SG_ 269 ACC_ax_Getriebe 0;
BA_ "GenSigSwitchedByIgnition" SG_ 269 ACC_Status_ACC 0;
BA_ "GenSigSendType" SG_ 269 ACC_Status_ACC 0;
BA_ "GenSigSendType" SG_ 269 ACC_Betaetigung_EPB 0;
BA_ "GenSigSendType" SG_ 269 ACC_Beeinflussung_ESP 0;
BA_ "GenSigSendType" SG_ 269 ACC_Anhalten 0;
BA_ "GenSigSendType" SG_ 269 ACC_KD_Fehler 0;
BA_ "GenSigSendType" SG_ 1469 AEM_Temp_Abschaltung 3;
BA_ "Fehlerwert" SG_ 1469 AEM_Status_Regelung 7;
BA_ "GenSigSendType" SG_ 1469 AEM_Status_Regelung 3;
BA_ "GenSigSendType" SG_ 1469 AEM_KD_Fehler 0;
BA_ "GenSigFuncType" SG_ 1660 AGA_01_CRC 2;
BA_ "GenSigSendType" SG_ 1660 AGA_01_CRC 0;
BA_ "GenSigFuncType" SG_ 1660 AGA_01_BZ 1;
BA_ "GenSigSendType" SG_ 1660 AGA_01_BZ 0;
BA_ "GenSigSendType" SG_ 1660 AGA_ohne_Funktion 0;
BA_ "GenSigSendType" SG_ 1660 AGA_KD_Fehler 0;
BA_ "GenSigFuncType" SG_ 64 Airbag_01_CHK 3;
BA_ "GenSigSendType" SG_ 64 Airbag_01_CHK 0;
BA_ "GenSigFuncType" SG_ 64 Airbag_01_BZ 1;
BA_ "GenSigSendType" SG_ 64 Airbag_01_BZ 0;
BA_ "GenSigStartValue" SG_ 64 AB_RGS_Anst 8;
BA_ "GenSigSendType" SG_ 64 AB_RGS_Anst 3;
BA_ "GenSigSendType" SG_ 64 AB_Front_Crash 3;
BA_ "GenSigSendType" SG_ 64 AB_Heck_Crash 3;
BA_ "GenSigSendType" SG_ 64 AB_SF_Crash 3;
BA_ "GenSigSendType" SG_ 64 AB_SB_Crash 3;
BA_ "GenSigSendType" SG_ 64 AB_Rollover_Crash 3;
BA_ "GenSigSendType" SG_ 64 AB_Crash_Int 3;
BA_ "GenSigStartValue" SG_ 64 AB_Lampe 1;
BA_ "GenSigSendType" SG_ 64 AB_Lampe 0;
BA_ "GenSigSendType" SG_ 64 AB_Deaktiviert 0;
BA_ "GenSigStartValue" SG_ 64 AB_VB_deaktiviert 1;
BA_ "GenSigSendType" SG_ 64 AB_VB_deaktiviert 0;
BA_ "GenSigSendType" SG_ 64 AB_Systemfehler 0;
BA_ "GenSigSendType" SG_ 64 AB_Diagnose 0;
BA_ "GenSigSendType" SG_ 64 AB_Stellgliedtest 0;
BA_ "GenSigSendType" SG_ 64 AB_Erh_Auf_VB 0;
BA_ "GenSigSendType" SG_ 64 AB_Gurtwarn_VF 0;
BA_ "GenSigSendType" SG_ 64 AB_Gurtwarn_VB 0;
BA_ "GenSigSendType" SG_ 64 AB_Anzeige_Fussg 0;
BA_ "GenSigSendType" SG_ 64 AB_Texte_AKS 0;
BA_ "GenSigStartValue" SG_ 64 AB_PAO_Leuchte_Anf 1;
BA_ "GenSigSendType" SG_ 64 AB_PAO_Leuchte_Anf 0;
BA_ "GenSigFuncType" SG_ 64 AB_MKB_gueltig 8;
BA_ "GenSigSendType" SG_ 64 AB_MKB_gueltig 0;
BA_ "GenSigSendType" SG_ 64 AB_MKB_Anforderung 4;
BA_ "GenSigSendType" SG_ 64 AB_Versorgungsspannung 0;
BA_ "Fehlerwert" SG_ 64 AB_Deaktivierung_HV 7;
BA_ "GenSigSendType" SG_ 64 AB_Deaktivierung_HV 3;
BA_ "GenSigSendType" SG_ 64 AB_EDR_Trigger 3;
BA_ "GenSigSendType" SG_ 64 AB_KD_Fehler 0;
BA_ "Fehlerwert" SG_ 1312 AB_Belegung_VB 1;
BA_ "GenSigSendType" SG_ 1312 AB_Belegung_VB 0;
BA_ "GenSigSendType" SG_ 1312 AB_Abschaltanf_SIH_BF 0;
BA_ "GenSigSendType" SG_ 1312 SC_PAO_Schriftzug_Anf 0;
BA_ "GenSigSendType" SG_ 1312 SC_PAO_ON_Anf 0;
BA_ "GenSigSendType" SG_ 1312 SC_PAO_OFF_Anf 0;
BA_ "Fehlerwert" SG_ 1312 AB_Crashschwere 7;
BA_ "GenSigSendType" SG_ 1312 AB_Crashschwere 0;
BA_ "GenSigSendType" SG_ 1312 AB_Anforderung_USM 0;
BA_ "GenSigStartValue" SG_ 1312 AB_Gurtschloss_FA 1;
BA_ "GenSigSendType" SG_ 1312 AB_Gurtschloss_FA 0;
BA_ "GenSigStartValue" SG_ 1312 AB_Gurtschloss_BF 1;
BA_ "GenSigSendType" SG_ 1312 AB_Gurtschloss_BF 0;
BA_ "GenSigStartValue" SG_ 1312 AB_Gurtschloss_Reihe2_FA 1;
BA_ "GenSigSendType" SG_ 1312 AB_Gurtschloss_Reihe2_FA 0;
BA_ "GenSigStartValue" SG_ 1312 AB_Gurtschloss_Reihe2_MI 1;
BA_ "GenSigSendType" SG_ 1312 AB_Gurtschloss_Reihe2_MI 0;
BA_ "GenSigStartValue" SG_ 1312 AB_Gurtschloss_Reihe2_BF 1;
BA_ "GenSigSendType" SG_ 1312 AB_Gurtschloss_Reihe2_BF 0;
BA_ "GenSigStartValue" SG_ 1312 AB_Gurtschloss_Reihe3_FA 1;
BA_ "GenSigSendType" SG_ 1312 AB_Gurtschloss_Reihe3_FA 0;
BA_ "GenSigStartValue" SG_ 1312 AB_Gurtschloss_Reihe3_MI 1;
BA_ "GenSigSendType" SG_ 1312 AB_Gurtschloss_Reihe3_MI 0;
BA_ "GenSigStartValue" SG_ 1312 AB_Gurtschloss_Reihe3_BF 1;
BA_ "GenSigSendType" SG_ 1312 AB_Gurtschloss_Reihe3_BF 0;
BA_ "Fehlerwert" SG_ 1312 AB_Sitzpos_Sens_FA 1;
BA_ "GenSigSendType" SG_ 1312 AB_Sitzpos_Sens_FA 0;
BA_ "Fehlerwert" SG_ 1312 AB_Sitzpos_Sens_BF 1;
BA_ "GenSigSendType" SG_ 1312 AB_Sitzpos_Sens_BF 0;
BA_ "GenSigSendType" SG_ 1312 AB_Trefferlage 0;
BA_ "GenSigFuncType" SG_ 65 Airbag_03_CRC 2;
BA_ "GenSigSendType" SG_ 65 Airbag_03_CRC 0;
BA_ "GenSigFuncType" SG_ 65 Airbag_03_BZ 1;
BA_ "GenSigSendType" SG_ 65 Airbag_03_BZ 0;
BA_ "GenSigSendType" SG_ 65 AB_MKB_Safing 4;
BA_ "GenSigSwitchedByIgnition" SG_ 1633 AAG_BZ 0;
BA_ "GenSigFuncType" SG_ 1633 AAG_BZ 1;
BA_ "GenSigSendType" SG_ 1633 AAG_BZ 0;
BA_ "GenSigSwitchedByIgnition" SG_ 1633 AAG_AVS_Fehler_02_inv 0;
BA_ "GenSigSendType" SG_ 1633 AAG_AVS_Fehler_02_inv 0;
BA_ "GenSigSwitchedByIgnition" SG_ 1633 AAG_Bremsl_durch_ECD 0;
BA_ "GenSigSendType" SG_ 1633 AAG_Bremsl_durch_ECD 0;
BA_ "GenSigSwitchedByIgnition" SG_ 1633 AAG_Anhaenger_abgesteckt 0;
BA_ "GenSigSendType" SG_ 1633 AAG_Anhaenger_abgesteckt 0;
BA_ "GenSigSwitchedByIgnition" SG_ 1633 AAG_NSL_aktiv 0;
BA_ "GenSigSendType" SG_ 1633 AAG_NSL_aktiv 0;
BA_ "GenSigSwitchedByIgnition" SG_ 1633 AAG_Anhaenger_erkannt 0;
BA_ "NWM-WakeupAllowed" SG_ 1633 AAG_Anhaenger_erkannt 1;
BA_ "GenSigSendType" SG_ 1633 AAG_Anhaenger_erkannt 0;
BA_ "GenSigSwitchedByIgnition" SG_ 1633 AAG_Blinker_H_aktiv 0;
BA_ "GenSigSendType" SG_ 1633 AAG_Blinker_H_aktiv 0;
BA_ "GenSigSwitchedByIgnition" SG_ 1633 AAG_Blinker_HL_def 0;
BA_ "GenSigSendType" SG_ 1633 AAG_Blinker_HL_def 0;
BA_ "GenSigSwitchedByIgnition" SG_ 1633 AAG_Blinker_HR_def 0;
BA_ "GenSigSendType" SG_ 1633 AAG_Blinker_HR_def 0;
BA_ "GenSigSwitchedByIgnition" SG_ 1633 AAG_Bremslicht_H_def 0;
BA_ "GenSigSendType" SG_ 1633 AAG_Bremslicht_H_def 0;
BA_ "GenSigSwitchedByIgnition" SG_ 1633 AAG_Schlusslicht_HL_def 0;
BA_ "GenSigSendType" SG_ 1633 AAG_Schlusslicht_HL_def 0;
BA_ "GenSigSwitchedByIgnition" SG_ 1633 AAG_Schlusslicht_HR_def 0;
BA_ "GenSigSendType" SG_ 1633 AAG_Schlusslicht_HR_def 0;
BA_ "GenSigSwitchedByIgnition" SG_ 1633 AAG_KD_Fehler 0;
BA_ "GenSigSendType" SG_ 1633 AAG_KD_Fehler 0;
BA_ "GenSigSwitchedByIgnition" SG_ 1633 AAG_AVS_Fehler 0;
BA_ "GenSigSendType" SG_ 1633 AAG_AVS_Fehler 0;
BA_ "GenSigSwitchedByIgnition" SG_ 1633 AAG_AVS_Stati 0;
BA_ "GenSigSendType" SG_ 1633 AAG_AVS_Stati 0;
BA_ "GenSigSwitchedByIgnition" SG_ 1542 BAP_06_Header 0;
BA_ "GenSigSendType" SG_ 1542 BAP_06_Header 3;
BA_ "GenSigSwitchedByIgnition" SG_ 1599 BAP_Debug_Cmd 0;
BA_ "GenSigSendType" SG_ 1599 BAP_Debug_Cmd 3;
BA_ "GenSigSwitchedByIgnition" SG_ 1598 BAP_Debug_Data 0;
BA_ "GenSigSendType" SG_ 1598 BAP_Debug_Data 3;
BA_ "GenSigSwitchedByIgnition" SG_ 1558 BAP_16_Header 0;
BA_ "GenSigSendType" SG_ 1558 BAP_16_Header 3;
BA_ "GenSigSwitchedByIgnition" SG_ 1580 BAP_2C_Header 0;
BA_ "GenSigSendType" SG_ 1580 BAP_2C_Header 3;
BA_ "GenSigSwitchedByIgnition" SG_ 1409 BCM_FH_Freigabe 0;
BA_ "GenSigSendType" SG_ 1409 BCM_FH_Freigabe 3;
BA_ "GenSigSwitchedByIgnition" SG_ 1409 BCM_Komfortfkt_Freigabe 0;
BA_ "GenSigSendType" SG_ 1409 BCM_Komfortfkt_Freigabe 3;
BA_ "GenSigSwitchedByIgnition" SG_ 1409 BCM_HSK_Freigabe 0;
BA_ "GenSigSendType" SG_ 1409 BCM_HSK_Freigabe 3;
BA_ "GenSigSwitchedByIgnition" SG_ 1409 BCM_Verdeck_Freigabe 0;
BA_ "GenSigSendType" SG_ 1409 BCM_Verdeck_Freigabe 3;
BA_ "GenSigSwitchedByIgnition" SG_ 1409 BCM2_Status_Timer_KL15_Abschalt 0;
BA_ "GenSigSendType" SG_ 1409 BCM2_Status_Timer_KL15_Abschalt 3;
BA_ "GenSigSendType" SG_ 1409 BCM2_Anford_AbschaltfreigabeKL15 3;
BA_ "GenSigSwitchedByIgnition" SG_ 1409 BCM2_Unterdr_Zuendungsmeldung 0;
BA_ "GenSigSendType" SG_ 1409 BCM2_Unterdr_Zuendungsmeldung 3;
BA_ "GenSigSwitchedByIgnition" SG_ 1409 BCM2_KL15_Absch_FT 0;
BA_ "GenSigSendType" SG_ 1409 BCM2_KL15_Absch_FT 3;
BA_ "GenSigSwitchedByIgnition" SG_ 1409 ZV_ist_Zustand_verfuegbar 0;
BA_ "GenSigSendType" SG_ 1409 ZV_ist_Zustand_verfuegbar 3;
BA_ "GenSigSwitchedByIgnition" SG_ 1409 BCM2_P_verriegelt 0;
BA_ "GenSigSendType" SG_ 1409 BCM2_P_verriegelt 3;
BA_ "GenSigSwitchedByIgnition" SG_ 1409 ZV_verriegelt_intern_ist 0;
BA_ "GenSigSendType" SG_ 1409 ZV_verriegelt_intern_ist 3;
BA_ "GenSigSwitchedByIgnition" SG_ 1409 ZV_verriegelt_extern_ist 0;
BA_ "GenSigSendType" SG_ 1409 ZV_verriegelt_extern_ist 3;
BA_ "GenSigSwitchedByIgnition" SG_ 1409 ZV_verriegelt_intern_soll 0;
BA_ "GenSigSendType" SG_ 1409 ZV_verriegelt_intern_soll 3;
BA_ "GenSigSwitchedByIgnition" SG_ 1409 ZV_verriegelt_extern_soll 0;
BA_ "GenSigSendType" SG_ 1409 ZV_verriegelt_extern_soll 3;
BA_ "GenSigSwitchedByIgnition" SG_ 1409 ZV_gesafet_extern_ist 0;
BA_ "GenSigSendType" SG_ 1409 ZV_gesafet_extern_ist 3;
BA_ "GenSigSwitchedByIgnition" SG_ 1409 ZV_gesafet_extern_soll 0;
BA_ "GenSigSendType" SG_ 1409 ZV_gesafet_extern_soll 3;
BA_ "GenSigSwitchedByIgnition" SG_ 1409 ZV_FT_offen 0;
BA_ "GenSigSendType" SG_ 1409 ZV_FT_offen 3;
BA_ "GenSigSwitchedByIgnition" SG_ 1409 ZV_BT_offen 0;
BA_ "GenSigSendType" SG_ 1409 ZV_BT_offen 3;
BA_ "GenSigSwitchedByIgnition" SG_ 1409 ZV_HL_offen 0;
BA_ "GenSigSendType" SG_ 1409 ZV_HL_offen 3;
BA_ "GenSigSwitchedByIgnition" SG_ 1409 ZV_HR_offen 0;
BA_ "GenSigSendType" SG_ 1409 ZV_HR_offen 3;
BA_ "GenSigSwitchedByIgnition" SG_ 1409 ZV_HD_offen 0;
BA_ "GenSigSendType" SG_ 1409 ZV_HD_offen 3;
BA_ "GenSigSwitchedByIgnition" SG_ 1409 ZV_Turen_HD_zu 0;
BA_ "GenSigSendType" SG_ 1409 ZV_Turen_HD_zu 3;
BA_ "GenSigSwitchedByIgnition" SG_ 1409 ZV_Einzeltuerentriegelung 0;
BA_ "GenSigSendType" SG_ 1409 ZV_Einzeltuerentriegelung 3;
BA_ "GenSigSwitchedByIgnition" SG_ 1409 ZV_Heckeinzelentriegelung 0;
BA_ "GenSigSendType" SG_ 1409 ZV_Heckeinzelentriegelung 3;
BA_ "GenSigSwitchedByIgnition" SG_ 1409 BCM_ValetTaster_Fkts_LED 0;
BA_ "GenSigSendType" SG_ 1409 BCM_ValetTaster_Fkts_LED 3;
BA_ "GenSigSwitchedByIgnition" SG_ 1409 BCM_HHS_aktiv 0;
BA_ "GenSigSendType" SG_ 1409 BCM_HHS_aktiv 3;
BA_ "GenSigSwitchedByIgnition" SG_ 1409 BCM_Spg_Hzg_Ein 0;
BA_ "GenSigSendType" SG_ 1409 BCM_Spg_Hzg_Ein 3;
BA_ "GenSigSwitchedByIgnition" SG_ 1409 ZV_HS_offen 0;
BA_ "GenSigSendType" SG_ 1409 ZV_HS_offen 3;
BA_ "GenSigSwitchedByIgnition" SG_ 1409 ZZH_Endlage_oben 0;
BA_ "GenSigSendType" SG_ 1409 ZZH_Endlage_oben 3;
BA_ "GenSigSwitchedByIgnition" SG_ 1409 ZZH_Endlage_unten 0;
BA_ "GenSigSendType" SG_ 1409 ZZH_Endlage_unten 3;
BA_ "GenSigSwitchedByIgnition" SG_ 1409 ZZH_Endlage_unplausibel 0;
BA_ "GenSigSendType" SG_ 1409 ZZH_Endlage_unplausibel 3;
BA_ "GenSigSwitchedByIgnition" SG_ 1409 BCM2_KD_Fehler 0;
BA_ "GenSigSendType" SG_ 1409 BCM2_KD_Fehler 3;
BA_ "GenSigSwitchedByIgnition" SG_ 1409 NGS_aktiv 0;
BA_ "GenSigSendType" SG_ 1409 NGS_aktiv 3;
BA_ "GenSigSwitchedByIgnition" SG_ 1409 IRUE_aktiv 0;
BA_ "GenSigSendType" SG_ 1409 IRUE_aktiv 3;
BA_ "GenSigSwitchedByIgnition" SG_ 1409 DWA_aktiv 0;
BA_ "GenSigSendType" SG_ 1409 DWA_aktiv 3;
BA_ "GenSigSwitchedByIgnition" SG_ 1409 Komp_Schutz_aktiv 0;
BA_ "GenSigSendType" SG_ 1409 Komp_Schutz_aktiv 3;
BA_ "GenSigSwitchedByIgnition" SG_ 1409 NGS_Taster_Fkts_LED 0;
BA_ "GenSigSendType" SG_ 1409 NGS_Taster_Fkts_LED 3;
BA_ "GenSigSwitchedByIgnition" SG_ 1409 IRUE_Taster_Fkts_LED 0;
BA_ "GenSigSendType" SG_ 1409 IRUE_Taster_Fkts_LED 3;
BA_ "GenSigSwitchedByIgnition" SG_ 1409 HD_Drehfalle_S1 0;
BA_ "GenSigSendType" SG_ 1409 HD_Drehfalle_S1 3;
BA_ "GenSigSwitchedByIgnition" SG_ 1409 HD_Sperrklinke_S2 0;
BA_ "GenSigSendType" SG_ 1409 HD_Sperrklinke_S2 3;
BA_ "GenSigSwitchedByIgnition" SG_ 1409 BCM_Verbau_Heckrollo 0;
BA_ "GenSigSendType" SG_ 1409 BCM_Verbau_Heckrollo 3;
BA_ "GenSigSwitchedByIgnition" SG_ 1409 BCM2_EZS_gedrueckt 0;
BA_ "GenSigSendType" SG_ 1409 BCM2_EZS_gedrueckt 3;
BA_ "GenSigSwitchedByIgnition" SG_ 1409 BCM2_SST_gedrueckt 0;
BA_ "GenSigSendType" SG_ 1409 BCM2_SST_gedrueckt 3;
BA_ "GenSigSwitchedByIgnition" SG_ 1409 LIM_alt 0;
BA_ "GenSigFuncType" SG_ 1409 LIM_alt 5;
BA_ "GenSigSendType" SG_ 1409 LIM_alt 3;
BA_ "GenSigSwitchedByIgnition" SG_ 1409 LIM_Innenbeleuchtung_V_aktiv 0;
BA_ "GenSigSendType" SG_ 1409 LIM_Innenbeleuchtung_V_aktiv 3;
BA_ "GenSigSwitchedByIgnition" SG_ 1409 LIM_Innenbeleuchtung_aktiv 0;
BA_ "GenSigSendType" SG_ 1409 LIM_Innenbeleuchtung_aktiv 3;
BA_ "GenSigSwitchedByIgnition" SG_ 1409 LIM_Taster_Rollolicht_hl 0;
BA_ "GenSigSendType" SG_ 1409 LIM_Taster_Rollolicht_hl 3;
BA_ "GenSigSwitchedByIgnition" SG_ 1409 LIM_Taster_Rollolicht_hr 0;
BA_ "GenSigSendType" SG_ 1409 LIM_Taster_Rollolicht_hr 3;
BA_ "GenSigSwitchedByIgnition" SG_ 1409 BCM_Sperrklinke_FT 0;
BA_ "GenSigSendType" SG_ 1409 BCM_Sperrklinke_FT 3;
BA_ "GenSigSwitchedByIgnition" SG_ 1409 LIM_Taster_Rollolicht_V 0;
BA_ "GenSigSendType" SG_ 1409 LIM_Taster_Rollolicht_V 3;
BA_ "GenSigSwitchedByIgnition" SG_ 1409 BCM_Tankwunsch 0;
BA_ "GenSigSendType" SG_ 1409 BCM_Tankwunsch 0;
BA_ "GenSigSwitchedByIgnition" SG_ 1409 ZV_Tankklappe_offen 0;
BA_ "GenSigSendType" SG_ 1409 ZV_Tankklappe_offen 0;
BA_ "GenSigSwitchedByIgnition" SG_ 1409 BCM_Tankklappensteller_Fehler 0;
BA_ "GenSigSendType" SG_ 1409 BCM_Tankklappensteller_Fehler 0;
BA_ "GenSigSwitchedByIgnition" SG_ 1409 KST_Fahrer_Hinweise 0;
BA_ "GenSigSendType" SG_ 1409 KST_Fahrer_Hinweise 3;
BA_ "GenSigSwitchedByIgnition" SG_ 1409 KST_Warn_P1_ZST_def 0;
BA_ "GenSigSendType" SG_ 1409 KST_Warn_P1_ZST_def 3;
BA_ "GenSigSwitchedByIgnition" SG_ 1409 KST_Warn_P2_ZST_def 0;
BA_ "GenSigSendType" SG_ 1409 KST_Warn_P2_ZST_def 3;
BA_ "GenSigSwitchedByIgnition" SG_ 1409 KST_Prio_Warn_03 0;
BA_ "GenSigSendType" SG_ 1409 KST_Prio_Warn_03 3;
BA_ "GenSigSwitchedByIgnition" SG_ 1409 KST_Prio_Warn_04 0;
BA_ "GenSigSendType" SG_ 1409 KST_Prio_Warn_04 3;
BA_ "GenSigSwitchedByIgnition" SG_ 1409 KST_Prio_Warn_05 0;
BA_ "GenSigSendType" SG_ 1409 KST_Prio_Warn_05 3;
BA_ "GenSigSwitchedByIgnition" SG_ 777 BEM_01_CHK 0;
BA_ "GenSigFuncType" SG_ 777 BEM_01_CHK 3;
BA_ "GenSigSendType" SG_ 777 BEM_01_CHK 0;
BA_ "GenSigSwitchedByIgnition" SG_ 777 BEM_01_BZ 0;
BA_ "GenSigFuncType" SG_ 777 BEM_01_BZ 1;
BA_ "GenSigSendType" SG_ 777 BEM_01_BZ 0;
BA_ "GenSigSwitchedByIgnition" SG_ 777 BEM_Segel_Info 0;
BA_ "GenSigSendType" SG_ 777 BEM_Segel_Info 0;
BA_ "Fehlerwert" SG_ 777 BEM_P_Generator 255;
BA_ "GenSigSwitchedByIgnition" SG_ 777 BEM_P_Generator 0;
BA_ "GenSigSendType" SG_ 777 BEM_P_Generator 0;
BA_ "GenSigSwitchedByIgnition" SG_ 777 BEM_n_LLA 0;
BA_ "GenSigSendType" SG_ 777 BEM_n_LLA 0;
BA_ "GenSigSwitchedByIgnition" SG_ 777 BEM_01_Abschaltstufen 0;
BA_ "GenSigSendType" SG_ 777 BEM_01_Abschaltstufen 0;
BA_ "GenSigSwitchedByIgnition" SG_ 777 BEM_Anf_KL 0;
BA_ "GenSigSendType" SG_ 777 BEM_Anf_KL 0;
BA_ "GenSigSwitchedByIgnition" SG_ 777 BEM_StartStopp_Info 0;
BA_ "GenSigSendType" SG_ 777 BEM_StartStopp_Info 0;
BA_ "GenSigSwitchedByIgnition" SG_ 1635 BEM_02_Abschaltstufen 0;
BA_ "GenSigSendType" SG_ 1635 BEM_02_Abschaltstufen 0;
BA_ "Fehlerwert" SG_ 1635 BEM_STH_Zielzeit 15;
BA_ "GenSigSwitchedByIgnition" SG_ 1635 BEM_STH_Zielzeit 0;
BA_ "GenSigStartValue" SG_ 1635 BEM_STH_Zielzeit 14;
BA_ "GenSigSendType" SG_ 1635 BEM_STH_Zielzeit 0;
BA_ "GenSigSwitchedByIgnition" SG_ 1635 BEM_MMI_Vorwarnung 0;
BA_ "GenSigSendType" SG_ 1635 BEM_MMI_Vorwarnung 0;
BA_ "GenSigSwitchedByIgnition" SG_ 1635 BEM_HL_Kontingentierung 0;
BA_ "GenSigSendType" SG_ 1635 BEM_HL_Kontingentierung 0;
BA_ "GenSigSwitchedByIgnition" SG_ 1635 NVEM_Anf_SD_schalten 0;
BA_ "GenSigSendType" SG_ 1635 NVEM_Anf_SD_schalten 0;
BA_ "GenSigSwitchedByIgnition" SG_ 1635 BEM_Generatordiagnose 0;
BA_ "GenSigSendType" SG_ 1635 BEM_Generatordiagnose 0;
BA_ "GenSigSwitchedByIgnition" SG_ 1635 BEM_Red_Innengeblaese 0;
BA_ "GenSigSendType" SG_ 1635 BEM_Red_Innengeblaese 0;
BA_ "GenSigSwitchedByIgnition" SG_ 1635 BEM_STH_Einschaltverbot 0;
BA_ "GenSigSendType" SG_ 1635 BEM_STH_Einschaltverbot 0;
BA_ "GenSigSwitchedByIgnition" SG_ 1635 BEM_HL_Regelung_Status 0;
BA_ "GenSigSendType" SG_ 1635 BEM_HL_Regelung_Status 0;
BA_ "Fehlerwert" SG_ 1635 BEM_Ladezustand 15;
BA_ "GenSigSwitchedByIgnition" SG_ 1635 BEM_Ladezustand 0;
BA_ "GenSigStartValue" SG_ 1635 BEM_Ladezustand 14;
BA_ "GenSigSendType" SG_ 1635 BEM_Ladezustand 0;
BA_ "GenSigSwitchedByIgnition" SG_ 1635 BEM_Batteriediagnose 0;
BA_ "GenSigSendType" SG_ 1635 BEM_Batteriediagnose 0;
BA_ "GenSigSwitchedByIgnition" SG_ 1635 MIB_Stromsparmodus 0;
BA_ "GenSigSendType" SG_ 1635 MIB_Stromsparmodus 0;
BA_ "GenSigSwitchedByIgnition" SG_ 1635 BEM_DFM 0;
BA_ "GenSigSendType" SG_ 1635 BEM_DFM 0;
BA_ "GenSigSwitchedByIgnition" SG_ 1635 BEM_REK_aktiv 0;
BA_ "GenSigSendType" SG_ 1635 BEM_REK_aktiv 0;
BA_ "GenSigSwitchedByIgnition" SG_ 1635 BEM_EMLIN_ungueltig 0;
BA_ "GenSigSendType" SG_ 1635 BEM_EMLIN_ungueltig 0;
BA_ "GenSigSwitchedByIgnition" SG_ 1635 BEM_Batt_Ab 0;
BA_ "GenSigSendType" SG_ 1635 BEM_Batt_Ab 0;
BA_ "Fehlerwert" SG_ 1635 BEM_UBDM 255;
BA_ "GenSigSwitchedByIgnition" SG_ 1635 BEM_UBDM 0;
BA_ "GenSigSendType" SG_ 1635 BEM_UBDM 0;
BA_ "GenSigSwitchedByIgnition" SG_ 1635 BEM_UGenSoll 0;
BA_ "GenSigSendType" SG_ 1635 BEM_UGenSoll 0;
BA_ "GenSigSwitchedByIgnition" SG_ 1635 BEM_Anf_KL15_schalten 0;
BA_ "GenSigSendType" SG_ 1635 BEM_Anf_KL15_schalten 0;
BA_ "Fehlerwert" SG_ 946 BEM_HYB_DC_uMinLV 255;
BA_ "GenSigSwitchedByIgnition" SG_ 946 BEM_HYB_DC_uMinLV 0;
BA_ "GenSigStartValue" SG_ 946 BEM_HYB_DC_uMinLV 254;
BA_ "GenSigSendType" SG_ 946 BEM_HYB_DC_uMinLV 0;
BA_ "GenSigSwitchedByIgnition" SG_ 946 BEM_HYB_DC_uSollLV 0;
BA_ "GenSigStartValue" SG_ 946 BEM_HYB_DC_uSollLV 37;
BA_ "GenSigSendType" SG_ 946 BEM_HYB_DC_uSollLV 0;
BA_ "GenSigSwitchedByIgnition" SG_ 946 BEM_Freigabe_HV_Ladung 0;
BA_ "GenSigSendType" SG_ 946 BEM_Freigabe_HV_Ladung 0;
BA_ "GenSigSwitchedByIgnition" SG_ 946 BEM_Hybrid_Info 0;
BA_ "GenSigSendType" SG_ 946 BEM_Hybrid_Info 0;
BA_ "Fehlerwert" SG_ 946 BEM_NV_NachladAnf 3;
BA_ "GenSigSwitchedByIgnition" SG_ 946 BEM_NV_NachladAnf 0;
BA_ "GenSigStartValue" SG_ 946 BEM_NV_NachladAnf 2;
BA_ "GenSigSendType" SG_ 946 BEM_NV_NachladAnf 0;
BA_ "GenSigSendType" SG_ 1628 BMS_HYB_ASV_hinten_Status 0;
BA_ "GenSigSendType" SG_ 1628 BMS_HYB_ASV_vorne_Status 0;
BA_ "GenSigSwitchedByIgnition" SG_ 1628 BMS_HYB_KD_Fehler 0;
BA_ "GenSigSendType" SG_ 1628 BMS_HYB_KD_Fehler 0;
BA_ "Fehlerwert" SG_ 1628 BMS_HYB_BattFanSpd 15;
BA_ "GenSigStartValue" SG_ 1628 BMS_HYB_BattFanSpd 14;
BA_ "GenSigSendType" SG_ 1628 BMS_HYB_BattFanSpd 0;
BA_ "GenSigSendType" SG_ 1628 BMS_HYB_VentilationReq 0;
BA_ "GenSigSendType" SG_ 1628 BMS_HYB_Spuelbetrieb_Status 0;
BA_ "GenSigSendType" SG_ 1628 BMS_HYB_Kuehlung_Anf 0;
BA_ "Fehlerwert" SG_ 1628 BMS_HYB_Temp_vor_Verd 255;
BA_ "GenSigStartValue" SG_ 1628 BMS_HYB_Temp_vor_Verd 254;
BA_ "GenSigSendType" SG_ 1628 BMS_HYB_Temp_vor_Verd 0;
BA_ "Fehlerwert" SG_ 1628 BMS_HYB_Temp_nach_Verd 255;
BA_ "GenSigStartValue" SG_ 1628 BMS_HYB_Temp_nach_Verd 254;
BA_ "GenSigSendType" SG_ 1628 BMS_HYB_Temp_nach_Verd 0;
BA_ "Fehlerwert" SG_ 1628 BMS_Temperatur 255;
BA_ "GenSigSwitchedByIgnition" SG_ 1628 BMS_Temperatur 0;
BA_ "GenSigStartValue" SG_ 1628 BMS_Temperatur 254;
BA_ "GenSigSendType" SG_ 1628 BMS_Temperatur 0;
BA_ "Fehlerwert" SG_ 1628 BMS_Temperatur_Ansaugluft 255;
BA_ "GenSigSwitchedByIgnition" SG_ 1628 BMS_Temperatur_Ansaugluft 0;
BA_ "GenSigStartValue" SG_ 1628 BMS_Temperatur_Ansaugluft 254;
BA_ "GenSigSendType" SG_ 1628 BMS_Temperatur_Ansaugluft 0;
BA_ "Fehlerwert" SG_ 1628 BMS_IstSpannung_HV 255;
BA_ "GenSigSwitchedByIgnition" SG_ 1628 BMS_IstSpannung_HV 0;
BA_ "GenSigStartValue" SG_ 1628 BMS_IstSpannung_HV 254;
BA_ "GenSigSendType" SG_ 1628 BMS_IstSpannung_HV 0;
BA_ "GenSigSwitchedByIgnition" SG_ 2617239041 CCP_LE_DTO_01_Data 0;
BA_ "GenSigSwitchedByIgnition" SG_ 482 CCP_GE_CRO_01_Data 0;
BA_ "GenSigSwitchedByIgnition" SG_ 490 CCP_GE_DTO_01_Data 0;
BA_ "GenSigSwitchedByIgnition" SG_ 1666 CCP_LE_CRO_01_Data 0;
BA_ "GenSigSwitchedByIgnition" SG_ 480 CCP_MO_CRO_01_Data 0;
BA_ "GenSigSwitchedByIgnition" SG_ 2616986624 CCP_MO_CRO_02_Data 0;
BA_ "GenSigSwitchedByIgnition" SG_ 488 CCP_MO_DTO_01_Data 0;
BA_ "GenSigSwitchedByIgnition" SG_ 2616986625 CCP_MO_DTO_02_Data 0;
BA_ "GenSigSwitchedByIgnition" SG_ 481 CCP_MOS_CRO_01_Data 0;
BA_ "GenSigSwitchedByIgnition" SG_ 2616986629 CCP_MOS_CRO_02_Data 0;
BA_ "GenSigSwitchedByIgnition" SG_ 489 CCP_MOS_DTO_01_Data 0;
BA_ "GenSigSwitchedByIgnition" SG_ 2616986630 CCP_MOS_DTO_02_Data 0;
BA_ "GenSigSwitchedByIgnition" SG_ 2617189888 CCP_Soundaktor_Aussen_CRO_01_000 0;
BA_ "GenSigFuncType" SG_ 2617189888 CCP_Soundaktor_Aussen_CRO_01_000 9;
BA_ "GenSigFuncType" SG_ 2617189889 CCP_Soundaktor_Aussen_DTO_01_001 9;
BA_ "GenSigSwitchedByIgnition" SG_ 2617042432 CCP_Soundaktor_CRO_01_Data 0;
BA_ "GenSigFuncType" SG_ 2617042432 CCP_Soundaktor_CRO_01_Data 9;
BA_REL_ "GenSigTimeoutTime" BU_SG_REL_ Magnetic_Ride_LB SG_ 265 ACC_01_CHK 500;
BA_REL_ "GenSigTimeoutTime" BU_SG_REL_ Magnetic_Ride_LB SG_ 265 ACC_01_BZ 500;
BA_REL_ "GenSigTimeoutTime" BU_SG_REL_ Magnetic_Ride_LB SG_ 265 ACC_Sollbeschleunigung 500;
BA_REL_ "GenSigTimeoutTime" BU_SG_REL_ Gateway_B8 SG_ 1415 Aero_KD_Fehler 5000;
BA_REL_ "GenSigTimeoutTime" BU_SG_REL_ Gateway_B8 SG_ 1347 Lift_KD_Fehler 5000;
BA_REL_ "GenSigTimeoutTime" BU_SG_REL_ Gateway_B8 SG_ 917 LWR_KD_Fehler 1000;
BA_REL_ "GenSigTimeoutTime" BU_SG_REL_ Getriebe_DL382_MLB SG_ 269 ACC_05_CHK 500;
BA_REL_ "GenSigTimeoutTime" BU_SG_REL_ Getriebe_DL382_MLB SG_ 269 ACC_05_BZ 500;
BA_REL_ "GenSigTimeoutTime" BU_SG_REL_ Getriebe_DL382_MLB SG_ 269 ACC_Freigabe_Verzanf 500;
BA_REL_ "GenSigTimeoutTime" BU_SG_REL_ Getriebe_DL382_MLB SG_ 269 ACC_Getriebestellung_P 500;
BA_REL_ "GenSigTimeoutTime" BU_SG_REL_ Getriebe_DL382_MLB SG_ 269 ACC_Momentenanforderung 500;
BA_REL_ "GenSigTimeoutTime" BU_SG_REL_ Getriebe_DL382_MLB SG_ 269 ACC_zul_Regelabw 500;
BA_REL_ "GenSigTimeoutTime" BU_SG_REL_ Getriebe_DL382_MLB SG_ 269 ACC_ax_Getriebe 500;
BA_REL_ "GenSigTimeoutTime" BU_SG_REL_ Getriebe_DL382_MLB SG_ 269 ACC_Anhalten 500;
BA_REL_ "GenSigTimeoutTime" BU_SG_REL_ Gateway SG_ 1660 AGA_KD_Fehler 5000;
BA_REL_ "GenSigTimeoutTime" BU_SG_REL_ Gateway SG_ 64 AB_KD_Fehler 500;
BA_REL_ "GenSigTimeoutTime" BU_SG_REL_ Getriebe_DL382_MLB SG_ 1633 AAG_Anhaenger_erkannt 1000;
BA_REL_ "GenSigTimeoutTime" BU_SG_REL_ Getriebe_DL382_MLB SG_ 777 BEM_Segel_Info 500;
BA_REL_ "GenSigTimeoutTime" BU_SG_REL_ Gateway SG_ 1628 BMS_HYB_KD_Fehler 5000;
VAL_ 3221225472 AGA_Charisma_FahrPr 0 "keine_Funktion" 1 "Programm_1" 2 "Programm_2" 3 "Programm_3" 4 "Programm_4" 5 "Programm_5" 6 "Programm_6" 7 "Programm_7" 8 "Programm_8" 9 "Programm_9" 10 "Programm_10" 11 "Programm_11" 12 "Programm_12" 13 "Programm_13" 14 "Programm_14" 15 "Programm_15" ;
VAL_ 3221225472 AGA_Charisma_Status 0 "Init" 1 "verfuegbar" 2 "nicht_verfuegbar" 3 "asynchron_durch_Fahrerwunsch" ;
VAL_ 3221225472 AGA_Verstaerker_Mute 0 "Mute" 1 "Kein_Mute" ;
VAL_ 265 ACC_Sollbeschleunigung 2047 "nicht definiert" ;
VAL_ 265 ACC_neg_Sollbeschl_Grad 255 "nicht_definiert" ;
VAL_ 265 ACC_pos_Sollbeschl_Grad 255 "nicht definiert" ;
VAL_ 265 ACC_Dynamik 0 "Init" 1 "dynamic" 2 "standard" 3 "comfort" ;
VAL_ 265 ACC_Minimale_Bremsung 0 "Anforderung_Minimale_Bremsung_nicht_aktiv" 1 "Anforderung_Minimale_Bremsung_aktiv" ;
VAL_ 1415 Aero_Luftklappe_links_Status 0 "geschlossen" 1 "verfaehrt" 2 "offen" 3 "Fehler" ;
VAL_ 1415 Aero_Luftklappe_rechts_Status 0 "geschlossen" 1 "verfaehrt" 2 "offen" 3 "Fehler" ;
VAL_ 1415 Aero_Frontspoiler_Status 0 "geschlossen" 1 "offen" 3 "oeffnend" 4 "schliessend" 7 "Fehler" ;
VAL_ 1415 Aero_Heckspoiler_Status 0 "geschlossen" 1 "Position_1" 2 "Position_2" 3 "oeffnend" 4 "schliessend" 7 "Fehler" ;
VAL_ 1415 Aero_SCU_Luefter_Status 0 "laeuft" 1 "laeuft_nicht" 3 "Fehler" ;
VAL_ 1415 Aero_Unterdruckpumpe_Status 0 "laeuft" 1 "laeuft_nicht" 3 "Fehler" ;
VAL_ 1415 Aero_Kamera_Kuehlung_Status 0 "kein_Fehler" 1 "Fehler" ;
VAL_ 1415 Aero_EBCS 0 "inaktiv" 1 "aktiv" ;
VAL_ 1415 Aero_Hardtop_Links_Status 0 "Nicht_Montiert" 1 "Montiert" 3 "Fehler" ;
VAL_ 1415 Aero_Hardtop_Rechts_Status 0 "Nicht_Montiert" 1 "Montiert" 3 "Fehler" ;
VAL_ 1415 Aero_Max_Performance 0 "inaktiv" 1 "aktiv" 3 "Fehler" ;
VAL_ 1415 Aero_SCAP_Text 0 "kein_Text" 1 "Wait_to_start" 2 "SuperCap_Uebertemperaur" 3 "SuperCap_Fehler" ;
VAL_ 1415 Aero_Frontklappe 0 "kein_Fehler" 1 "Fehler" ;
VAL_ 1415 AERO_St_LED_HSpoiler 0 "inaktiv / Init" 1 "aktiv" 2 "blinken" 3 "blinken langsam" ;
VAL_ 1415 Aero_Sp_IstPos 0 "Init / Ist-Position 1" 1 "Ist-Position 2" 2 "Ist-Position 3" 3 "Ist-Position 4" 4 "Ist-Position 5" 5 "Ist-Position 6" 6 "Ist-Position 7" 7 "Fehler" ;
VAL_ 1415 AERO_W_SpoilerInfo 0 "Keine Meldung / Init" 1 "Spoiler_fahren_aus" 2 "Spoiler_fahren_ein" 3 "Spoiler_sind_ausgefahren" 4 "Spoiler_sind_eingefahren" 5 "Spoiler_ausfahren_nicht_moeglich" 6 "Spoiler_einfahren_nicht_moeglich" 7 "reserviert" ;
VAL_ 1415 Aero_KD_Fehler 0 "kein_KD_Fehler" 1 "KD_Fehler" ;
VAL_ 325 Aero_SCAP_Relais_Status 0 "offen" 1 "geschlossen" 3 "Fehler" ;
VAL_ 325 Aero_SCAP_Status 0 "SCAP_bereit" 1 "SCAP_nicht_bereit" 2 "Init" 3 "Fehler" ;
VAL_ 325 AERO_StartStopp_Info 0 "Motorlauf_langfristig_nicht_notwendig_Stoppfreigabe" 1 "Motoranlauf_nicht_zwingend_notwendig_Stoppverbot_keine_Startanforderung" 2 "Motoranlauf_zwingend_notwendig_Startanforderung" 3 "Systemfehler" ;
VAL_ 867 BM_ZV_auf 0 "inaktiv" 1 "aktiv" ;
VAL_ 867 BM_ZV_zu 0 "inaktiv" 1 "aktiv" ;
VAL_ 867 BM_DWA_ein 0 "inaktiv" 1 "aktiv" ;
VAL_ 867 BM_DWA_Alarm 0 "inaktiv" 1 "aktiv" ;
VAL_ 867 BM_Crash 0 "inaktiv" 1 "aktiv" ;
VAL_ 867 BM_Panik 0 "inaktiv" 1 "aktiv" ;
VAL_ 867 BM_Not_Bremsung 0 "inaktiv" 1 "aktiv" ;
VAL_ 867 BM_GDO 0 "inaktiv" 1 "aktiv" ;
VAL_ 867 BM_links 0 "inaktiv" 1 "aktiv" ;
VAL_ 867 BM_rechts 0 "inaktiv" 1 "aktiv" ;
VAL_ 867 BM_Warnblinken 0 "inaktiv" 1 "aktiv" ;
VAL_ 867 BM_Taxi_Notalarm 0 "inaktiv" 1 "aktiv" ;
VAL_ 867 BM_Telematik 0 "inaktiv" 1 "aktiv" ;
VAL_ 867 BM_HD_Oeffnung_angelernt 0 "keine_Quittierung" 1 "Quittierung" ;
VAL_ 867 BM_WBT_Beleuchtung 0 "inaktiv" 1 "aktiv" ;
VAL_ 867 Blinken_li_Fzg_Takt 0 "Blinker_links_ausgeschaltet" 1 "Blinker_links_eingeschaltet" ;
VAL_ 867 Blinken_re_Fzg_Takt 0 "Blinker_rechts_ausgeschaltet" 1 "Blinker_rechts_eingeschaltet" ;
VAL_ 867 Blinken_li_Kombi_Takt 0 "Blinkerkontrolllampe_links_ausgeschaltet" 1 "Blinkerkontrolllampe_links_eingeschaltet" ;
VAL_ 867 Blinken_re_Kombi_Takt 0 "Blinkerkontrolllampe_rechts_ausgeschaltet" 1 "Blinkerkontrolllampe_rechts_eingeschaltet" ;
VAL_ 867 BM_NBA_n_codiert_n_aktiv 0 "codiert_AND_kein_Fehler" 1 "nicht_codiert_OR_Fehler_erkannt" ;
VAL_ 867 BM_NBA_Status 0 "NBA_nicht_aktiv" 1 "BRL_Dunkelphase" 3 "BRL_Hellphase" ;
VAL_ 867 Blinken_FWB_aktiv 0 "inaktiv" 1 "aktiv" ;
VAL_ 264 FA_Hoehenwerte_kalibriert 0 "kalibrierte Höhenwerte in mm" 1 "Rohwerte" ;
VAL_ 264 FA_ESP_Zuschaltung 0 "keine_ESP_Beeinflussung" 1 "ESP_Zwangszuschaltung_angefordert" ;
VAL_ 264 FA_Hoehenwert_VL_00 254 "nicht initialisiert" 255 "Fehler" ;
VAL_ 264 FA_Hoehenwert_VL_01 254 "nicht initialisiert" 255 "Fehler" ;
VAL_ 264 FA_Hoehenwert_VR_00 254 "nicht initialisiert" 255 "Fehler" ;
VAL_ 264 FA_Hoehenwert_VR_01 254 "nicht initialisiert" 255 "Fehler" ;
VAL_ 264 FA_Hoehenwert_HL_00 254 "nicht initialisiert" 255 "Fehler" ;
VAL_ 264 FA_Hoehenwert_HL_01 254 "nicht initialisiert" 255 "Fehler" ;
VAL_ 264 FA_Hoehenwert_HR_00 254 "nicht initialisiert" 255 "Fehler" ;
VAL_ 264 FA_Hoehenwert_HR_01 254 "nicht initialisiert" 255 "Fehler" ;
VAL_ 1138 Anhaenger_01_alt 0 "aktuell" 1 "veraltet" ;
VAL_ 1138 Kombi_01_alt 0 "aktuell" 1 "veraltet" ;
VAL_ 1138 STH_01_alt 0 "aktuell" 1 "veraltet" ;
VAL_ 1138 Licht_hinten_01_alt 0 "aktuell" 1 "veraltet" ;
VAL_ 1347 Lift_Status 0 "Lift_in_Endlage_unten" 1 "Lift_in_Endlage_oben" 2 "Ausfuehrung_Hebevorgang" 3 "Ausfuehrung_Senkvorgang" 4 "System_voruebergehend_nicht_verfuegbar" 5 "Warnung_Vorderwagen_nicht_abgesenkt" 6 "tbd" 7 "Fehler" ;
VAL_ 1347 Lift_Charisma_FahrPr 0 "nicht_belegt" 1 "Programm_1" 2 "Programm_2" 3 "Programm_3" 4 "Programm_4" 5 "Programm_5" 6 "Programm_6" 7 "Programm_7" ;
VAL_ 1347 Lift_Charisma_Status 0 "Init" 1 "verfuegbar" 2 "nicht_verfuegbar" 3 "asynchron_durch_Fahrerwunsch" ;
VAL_ 1347 Lift_Charisma_Umschaltung 0 "Idle" 1 "Erkennung_Umschaltaufforderung" 2 "Steuerbotschaft_nicht_definiert" 3 "Umschaltung_verzoegert" ;
VAL_ 1347 Lift_KD_Fehler 0 "kein_KD_Fehler" 1 "KD_Fehler" ;
VAL_ 917 AFS_Abbiegelicht_li_Anf 0 "Abbiegelicht_aus" 1 "Abbiegelicht_ein" ;
VAL_ 917 AFS_Abbiegelicht_re_Anf 0 "Abbiegelicht_aus" 1 "Abbiegelicht_ein" ;
VAL_ 917 AFS_Abbiegelicht_Dimm_Anf 0 "Dimmung_angefordert" 1 "keine_Dimmung" ;
VAL_ 917 AFS_Verfuegbarkeit_GLW 0 "GLW_nicht_verfuegbar" 1 "GLW_verfuegbar" ;
VAL_ 917 AFS_Status_adaptive_LV 0 "adaptive_Lichtverteilung_aus" 1 "adaptive_Lichtverteilung_an" ;
VAL_ 917 AFS_Fernlicht_li_defekt 0 "Fernlicht_in_Ordnung" 1 "Fernlicht_defekt" ;
VAL_ 917 AFS_Fernlicht_re_defekt 0 "Fernlicht_in_Ordnung" 1 "Fernlicht_defekt" ;
VAL_ 917 AFS_Fernlicht_Status 0 "Fernlicht_aus" 1 "Fernlicht_ein" ;
VAL_ 917 AFS_Lampe 0 "Aus" 1 "Ein" ;
VAL_ 917 LWR_Lampe 0 "LWR Fehlerlampe aus" 1 "LWR Fehlerlampe ein" ;
VAL_ 917 AFS_Fehlertext 0 "kein Text" 1 "AFS ohne Funktion" ;
VAL_ 917 AFS_LED_Blinkmode 0 "kein Blinkmode angefordert" 1 "Blinkmode angefordert" ;
VAL_ 917 LWR_Touristenmodus_aktiv 0 "Touristenmodus inaktiv" 1 "Touristenmodus aktiv" ;
VAL_ 917 AFS_Charisma_FahrPr 0 "nicht_belegt" 1 "Programm_1" 2 "Programm_2" 3 "Programm_3" 4 "Programm_4" 5 "Programm_5" 6 "Programm_6" 7 "Programm_7" ;
VAL_ 917 AFS_Charisma_Status 0 "Init" 1 "verfuegbar" 2 "nicht_verfuegbar" 3 "asynchron_durch_Fahrerwunsch" ;
VAL_ 917 AFS_Charisma_Umschaltung 0 "Idle" 1 "Erkennung_Umschaltaufforderung" 2 "Steuerbotschaft_nicht_definiert" 3 "Umschaltung_verzoegert" ;
VAL_ 917 AFS_Allwetterlicht 0 "Allwetterlicht_nicht_aktiv" 1 "Allwetterlicht_aktiv" ;
VAL_ 917 LWR_Touristenmodus_verbaut 0 "Touristenmodus_nicht_verbaut" 1 "Touristenmodus_verbaut" ;
VAL_ 917 AFS_adaptive_LV_verbaut 0 "adaptive_Lichtverteilung_nicht_verbaut" 1 "adaptive_Lichtverteilung_verbaut" ;
VAL_ 917 LWR_Reisemodus_Texte 0 "keine_Anzeige" 1 "Umschaltung_auf_Linksverkehr_aktiv" 2 "Umschaltung_auf_Rechtsverkehr_aktiv" ;
VAL_ 917 GLW_Sensor_blockiert 0 "Kamera_Sensor_nicht_blockiert" 1 "Kamera_Sensor_blockiert" ;
VAL_ 917 LWR_Pos_Schrittmotor 254 "Init" 255 "Fehler" ;
VAL_ 917 LWR_Hoehenwert_VL 254 "nicht_initialisiert" 255 "Fehler" ;
VAL_ 917 LWR_Hoehenwert_HL 254 "nicht_initialisiert" 255 "Fehler" ;
VAL_ 917 AFS_Ersatzlicht_Links 0 "keine Ersatzlichtfunktion links" 1 "Ersatzlichtfunktion links" ;
VAL_ 917 AFS_Ersatzlicht_Rechts 0 "keine Ersatzlichtfunktion rechts" 1 "Ersatzlichtfunktion rechts" ;
VAL_ 917 LWR_AFS_Grundeinstellung 0 "Grundeinstellung nicht erfolgt" 1 "Grundeinstellung erfolgt" ;
VAL_ 917 LWR_AFS_Parametrisierung 0 "Parametrisierung nicht erfolgt" 1 "Parametrisierung erfolgt" ;
VAL_ 917 LWR_Initialisierungslauf 0 "Initialisierungslauf nicht erfolgt" 1 "Initialisierungslauf erfolgt" ;
VAL_ 917 LWR_Sicherheitsposition 0 "Sicherheitsposition aus" 1 "Sicherheitsposition ein" ;
VAL_ 917 LWR_Modus 0 "LWR statisch" 1 "LWR dynamisch" ;
VAL_ 917 LWR_KD_Fehler 0 "kein_KD_Fehler" 1 "KD_Fehler" ;
VAL_ 1759 NMH_Aero_Start_1 1 "Zustand Start (<--Sleep)" ;
VAL_ 1759 NMH_Aero_Start_2 1 "Zustand Start (<--Prepare to Sleep)" ;
VAL_ 1759 NMH_Aero_Normal_Mode_1 1 "Zustand Normal Mode (<-- Start)" ;
VAL_ 1759 NMH_Aero_Normal_Mode_2 1 "Zustand Normal Mode (<-- Ready to Sleep)" ;
VAL_ 1759 NMH_Aero_Car_WakeUp 1 "Car Wake Up" ;
VAL_ 1759 NMH_Aero_Per_WakeUp 0 "Funktions-WakeUp" 1 "CAN" 2 "P_WakeUp_Ursache_unbekannt" 3 "KL_15_Hardware_falls_vorhanden" ;
VAL_ 1759 NMH_Aero_Fkt_WakeUp 0 "Peripheriewakeup" ;
VAL_ 1759 NMH_Aero_Klemme_15 1 "Klemme 15 ein" ;
VAL_ 1759 NMH_Aero_Diagnose 1 "Diagnose bei Kl 15 aus" ;
VAL_ 1759 NMH_Aero_MindestAktivZeit 1 "aktiv" ;
VAL_ 1759 NMH_Aero_NL_Datem_EEPROM 0 "kein_Nachlauf" 1 "EEPROM_schreibzugriff" ;
VAL_ 1759 NMH_Aero_Signalfehler 1 "Aktiver_Signalfehler_eingetragen" ;
VAL_ 1759 NMH_Aero_TimeOut_Fehler 1 "Aktiver Timeout Fehlerspeichereintrag" ;
VAL_ 1759 NMH_Aero_CAN_Diag_deaktiv 1 "CAN Bus bezogene Eigendiagnose deaktiviert" ;
VAL_ 1759 NMH_Aero_KompSchutz 0 "inaktiv" 1 "aktiv" ;
VAL_ 1759 NMH_Aero_Mute_Mode 1 "Mute Mode aktiv" ;
VAL_ 1759 NMH_Aero_Transport_Mode 1 "Transportmodus aktiv" ;
VAL_ 1759 NMH_Aero_Abschaltstufe_aktiv 1 "Funktionsabschaltung wegen Abschaltschaltstufe" ;
VAL_ 1759 NMH_Aero_Busfehler 1 "Busfehler" ;
VAL_ 1759 NMH_Aero_Lokalaktiv 0 "war_nicht_lokal_aktiv" 1 "war_lokal_aktiv" ;
VAL_ 1759 NMH_Aero_Subsystemaktiv 0 "Subsystem_war_nicht_lokalaktiv" 1 "war_lokalaktiv" ;
VAL_ 266 TSK_amax_moeglich 511 "nicht definiert" ;
VAL_ 268 TSK_Anhalten 0 "kein Anhalten gewünscht" 1 "Anhalten gewünscht" ;
VAL_ 268 TSK_Standby_Anf_ESP 0 "keine_Standby_Anforderung" 1 "Standby_Anforderung" ;
VAL_ 268 TSK_Verzoeg_Anf 255 "nicht_definiert" ;
VAL_ 983 VS_KD_Fehler 0 "kein_KD_Fehler" 1 "KD_Fehler" ;
VAL_ 983 VS_VD_zu_ver 1 "Zustand des Verdecks verriegelt und geschlossen" ;
VAL_ 983 VS_VD_entriegelt 1 "Zustand des Verdeck entriegelt" ;
VAL_ 983 VS_VD_offen_ver 0 "Init" 1 "Zustand des Verdecks verriegelt und offen " ;
VAL_ 983 VS_VD_Zwischenposition 1 "Verdeck in Zwischenposition " ;
VAL_ 983 VS_VD_Bew_auf 1 "Verdeck in Bewegung auf" ;
VAL_ 983 VS_VD_Bew_zu 1 "Verdeck in Bewegung zu " ;
VAL_ 983 VS_Hardtop 1 "Hardtop montiert" ;
VAL_ 983 VS_VD_Fehler 1 "Fehlerzustand Verdeck " ;
VAL_ 983 VS_Lampe_Blk 0 "Kontrollleuchte_inaktiv" 1 "Kontrollleuchte_aktiv" ;
VAL_ 983 VS_HD_sperren 0 "HD Entriegelung freigegeben" 1 "HD Entriegelung gesperrt" ;
VAL_ 983 VS_HHS_enable 1 "Freigabe HHS " ;
VAL_ 983 VS_VVW_unten 1 "VWW unten" ;
VAL_ 983 VSG_FT_FH_BT_ManHoch 0 "Keine_Verfahranforderung" 1 "Manueller_Hochlauf" ;
VAL_ 983 VSG_FT_FH_BT_AutoHoch 0 "Keine_Verfahranforderung" 1 "Automatischer_Hochlauf" ;
VAL_ 983 VSG_FT_FH_BT_ManTief 0 "Keine_Verfahranforderung" 1 "Manueller_Tieflauf" ;
VAL_ 983 VSG_FT_FH_BT_AutoTief 0 "Kein_Verfahranforderung" 1 "Automatischer_Tieflauf" ;
VAL_ 983 VSG_FT_FH_FT_ManHoch 0 "Keine_Verfahranforderung" 1 "Manueller_Hochlauf" ;
VAL_ 983 VSG_FT_FH_FT_AutoHoch 0 "Keine_Verfahranforderung" 1 "Automatischer_Hochlauf" ;
VAL_ 983 VSG_FT_FH_FT_ManTief 0 "Keine_Verfahranforderung" 1 "Manueller_Tieflauf" ;
VAL_ 983 VSG_FT_FH_FT_AutoTief 0 "Keine_Verfahranforderung" 1 "Automatischer_Tieflauf" ;
VAL_ 983 VSG_FT_FH_HL_ManHoch 0 "Keine_Verfahranforderung" 1 "Manueller_Hochlauf" ;
VAL_ 983 VSG_FT_FH_HL_AutoHoch 0 "Keine_Verfahranforderung" 1 "Automatischer_Hochlauf" ;
VAL_ 983 VSG_FT_FH_HL_ManTief 0 "Keine_Verfahranforderung" 1 "Manueller_Tieflauf" ;
VAL_ 983 VSG_FT_FH_HL_AutoTief 0 "Keine_Verfahranforderung" 1 "Automatischer_Tieflauf" ;
VAL_ 983 VSG_FT_FH_HR_ManHoch 0 "Keine_Verfahranforderung" 1 "Manueller_Hochlauf" ;
VAL_ 983 VSG_FT_FH_HR_AutoHoch 0 "Keine_Verfahranforderung" 1 "Automatischer_Hochlauf" ;
VAL_ 983 VSG_FT_FH_HR_ManTief 0 "Keine_Verfahranforderung" 1 "Manueller_Tieflauf" ;
VAL_ 983 VSG_FT_FH_HR_AutoTief 0 "Keine_Verfahranforderung" 1 "Automatischer_Tieflauf" ;
VAL_ 983 VS_Texte 1 "Text1" 2 "Text2" 4 "Text3" 8 "Text4" 16 "Text5" 32 "Text6" 64 "Text7" 128 "Text8" ;
VAL_ 912 WBA_WH_Sleep_ACK_alt 0 "kein Sleep Acknoledge" 1 "Sleep Acknoledge" ;
VAL_ 912 GE_Warnung_Auto_N_LB 0 "keine_Anzeige" 1 "Warnung_ein" ;
VAL_ 912 WBA_GE_Fastshift 0 "nicht_verfuegbar" 1 "verfuegbar" ;
VAL_ 912 WBA_GE_Textmeldungen 0 "keine_Anzeige" 1 "Weiterfahrt möglich (+ gelbes Getriebefehlersymbol)" 2 "Weiterfahrt nur eingeschränkt möglich (+ gelbes Getriebefehlersymbol)" 3 "nur DL-Getriebe: Weiterfahrt nur eingeschränkt möglich. Kein R-Gang" 4 "Wiederanmeldeprozedur_Bremse_betaetigen" 7 "Performance_Start_moeglich" ;
VAL_ 269 ACC_Freigabe_Momentenanf 0 "Momanf_nicht_freigegeben" 1 "Momanf_freigegeben" ;
VAL_ 269 ACC_Freigabe_Verzanf 0 "Verzanf_nicht_freigegeben" 1 "Verzanf_freigegeben" ;
VAL_ 269 ACC_Getriebestellung_P 0 "P_Stellung_nicht_angefordert" 1 "Anforderung_P_Stellung" ;
VAL_ 269 ACC_limitierte_Anfahrdyn 0 "keine_Limitierung" 1 "Limitierung_Anfahrdynamik_angefordert" ;
VAL_ 269 ACC_Loeseanforderung 0 "keine_Anforderung" 1 "Loeseanforderung" ;
VAL_ 269 ACC_StartStopp_Info 0 "Motorlauf_langfristig_nicht_notwendig_Stoppfreigabe" 1 "Motoranlauf_nicht_zwingend_notwendig_Stoppverbot_keine_Startanforderung" 2 "Motoranlauf_zwingend_notwendig_Startanforderung" 3 "Systemfehler" ;
VAL_ 269 ACC_Segelveto 0 "Segelfreigabe" 1 "Segelveto" ;
VAL_ 269 ACC_Vorbefuellung_Bremsanlage 0 "Vorbefuellung_AUS" 1 "Vorbefuellung_EIN" ;
VAL_ 269 ACC_Status_ACC 0 "ACC_OFF_Hauptschalter_aus" 1 "ACC_INIT" 2 "ACC_STANDBY" 3 "ACC_AKTIV_regelt" 4 "ACC_OVERRIDE" 5 "ACC_Abschaltreaktion" 6 "reversibler_Fehler_im_ACC_System" 7 "irreversibler_Fehler_im_ACC_System" ;
VAL_ 269 ACC_Betaetigung_EPB 0 "keine_EPB_Anforderung" 1 "EPB_Aktuator_schliessen" ;
VAL_ 269 ACC_Beeinflussung_ESP 0 "keine_Zwangszuschaltung" 1 "ESP_Zwangszuschaltung" ;
VAL_ 269 ACC_Anhalten 0 "kein_Anhalten_gewuenscht" 1 "Anhalten_gewuenscht" ;
VAL_ 269 ACC_KD_Fehler 0 "kein_KD_Fehler" 1 "KD_Fehler" ;
VAL_ 1469 AEM_Temp_Abschaltung 0 "Keine_Abschaltung" 1 "Abschaltung_Stufe_1" 2 "Abschaltung_Stufe_2" 3 "Abschaltung_Vollstaendig" ;
VAL_ 1469 AEM_Status_Regelung 0 "Init" 1 "betriebsbereit_passiv" 2 "Aktiv" 7 "Fehler" ;
VAL_ 1469 AEM_KD_Fehler 0 "kein_KD_Fehler" 1 "KD_Fehler" ;
VAL_ 1660 AGA_Texte 0 "keine_Anzeige" 1 "Aussensound_defekt" 2 "Aussensound_deaktiviert" ;
VAL_ 1660 AGA_ohne_Funktion 0 "kein_Fehler" 1 "Fehler" ;
VAL_ 1660 AGA_KD_Fehler 0 "kein_KD_Fehler" 1 "KD_Fehler" ;
VAL_ 64 AB_RGS_Anst 4 "aktiv_Niveau_1" 5 "aktiv_Niveau_2" 6 "aktiv_Niveau_3" 7 "aktiv_Niveau_4" 8 "deaktiviert" ;
VAL_ 64 AB_Front_Crash 0 "kein_Front_Crash" 1 "Front_Crash" ;
VAL_ 64 AB_Heck_Crash 0 "kein_Heck_Crash" 1 "Heck_Crash" ;
VAL_ 64 AB_SF_Crash 0 "kein_Seiten_Crash_Fahrer" 1 "Seiten_Crash_Fahrer" ;
VAL_ 64 AB_SB_Crash 0 "kein_Seiten_Crash_Beifahrer" 1 "Seiten_Crash_Beifahrer" ;
VAL_ 64 AB_Rollover_Crash 0 "kein_Rollover" 1 "Rollover" ;
VAL_ 64 AB_Crash_Int 0 "kein_Crash" 1 "Crash_Intensitaet_1" 2 "Crash_Intensitaet_2_(nur_Stellgliedtest_MLB_B8)" 3 "Crash_Intensitaet_2_(nur_D4_C7_Colorado_NF_PAG__Crash_im_MLB_B8)" 4 "Crash_Intensitaet_3_(alt_VW/AUDI__Stellgliedtest_MLB_B8)" 5 "Crash_Intensitaet_3_(alt_PAG)" 7 "Crash_Intensitaet_3" ;
VAL_ 64 AB_Lampe 0 "Aus" 1 "Ein" ;
VAL_ 64 AB_Deaktiviert 0 "aktiv" 1 "deaktiviert" ;
VAL_ 64 AB_VB_deaktiviert 0 "Beifahrerairbag_aktiv" 1 "Beifahrerairbag_deaktiviert" ;
VAL_ 64 AB_Systemfehler 0 "kein_Fehler" 1 "Airbag_Systemfehler" ;
VAL_ 64 AB_Diagnose 0 "nicht_in_Diagnose" 1 "in_Diagnose" ;
VAL_ 64 AB_Stellgliedtest 0 "nicht_im_Stellgliedtest" 1 "Airbag_im_Stellgliedtest" ;
VAL_ 64 AB_Erh_Auf_VB 0 "keine_Anzeige" 1 "Beifahrerairbag_deaktiviert" 2 "Beifahrerairbag_aktiviert" 3 "nicht_definiert" ;
VAL_ 64 AB_Gurtwarn_VF 0 "keine_Warnung" 1 "Gurtwarnung_ausloesen" ;
VAL_ 64 AB_Gurtwarn_VB 0 "keine_Warnung" 1 "Gurtwarnung_ausloesen" ;
VAL_ 64 AB_Anzeige_Fussg 0 "keine_FSG_Aktion_ausgeloest" 1 "Motorhaube_offen" 2 "Systemfehler" ;
VAL_ 64 AB_Texte_AKS 0 "keine_AKS_Ausloesung" 1 "AKS_ausgeloest" 2 "AKS_Systemfehler" ;
VAL_ 64 AB_PAO_Leuchte_Anf 0 "Leuchte_ausschalten" 1 "Leuchte_einschalten" ;
VAL_ 64 AB_MKB_gueltig 0 "Multikollisionsbremsung_nicht_freigeschaltet" 1 "Multikollisionsbremsung_freigeschaltet" ;
VAL_ 64 AB_MKB_Anforderung 0 "Multikollisionsbremsung_nicht_angefordert" 1 "Multikollisionsbremsung_angefordert" ;
VAL_ 64 AB_Versorgungsspannung 0 "plausibel" 1 "unplausibel" ;
VAL_ 64 AB_Deaktivierung_HV 0 "keine_Deaktivierung" 1 "Deaktivierung_1" 2 "Deaktivierung_2" 3 "Deaktivierung_3" 4 "Deaktivierung_4" 5 "Deaktivierung_5" 6 "Deaktivierung_6" 7 "Fehler" ;
VAL_ 64 AB_EDR_Trigger 0 "No_Event" 1 "Start_Event" 2 "NonDeployment_Event" 3 "Deployment_Event" ;
VAL_ 64 AB_KD_Fehler 0 "kein_KD_Fehler" 1 "KD_Fehler" ;
VAL_ 1312 AB_Belegung_VB 0 "nicht_verfuegbar" 1 "Fehler" 2 "nicht_belegt" 3 "belegt" ;
VAL_ 1312 AB_Abschaltanf_SIH_BF 0 "Normalbetrieb" 1 "Abschaltung_angefordert" ;
VAL_ 1312 SC_PAO_Schriftzug_Anf 0 "LED aus" 1 "LED an" 2 "LED blinken" 3 "reserviert" ;
VAL_ 1312 SC_PAO_ON_Anf 0 "LED aus" 1 "LED an" 2 "LED blinken" 3 "reserviert" ;
VAL_ 1312 SC_PAO_OFF_Anf 0 "LED aus" 1 "LED an" 2 "LED blinken" 3 "reserviert" ;
VAL_ 1312 AB_Crashschwere 0 "kein_Ereignis" 1 "Crashschwere_1" 2 "Crashschwere_2" 3 "Crashschwere_3" 4 "Crashschwere_4" 5 "Crashschwere_5" 6 "nicht_belegt" 7 "Fehler" ;
VAL_ 1312 AB_Anforderung_USM 0 "keine_Anforderung" 1 "Anforderung" ;
VAL_ 1312 AB_Gurtschloss_FA 0 "nicht_verbaut" 1 "nicht_verfügbar (Fehler oder Init)" 2 "nicht_gesteckt" 3 "gesteckt" ;
VAL_ 1312 AB_Gurtschloss_BF 0 "nicht_verbaut" 1 "nicht_verfügbar (Fehler oder Init)" 2 "nicht_gesteckt" 3 "gesteckt" ;
VAL_ 1312 AB_Gurtschloss_Reihe2_FA 0 "nicht_verbaut" 1 "nicht_verfügbar (Fehler oder Init)" 2 "nicht_gesteckt" 3 "gesteckt" ;
VAL_ 1312 AB_Gurtschloss_Reihe2_MI 0 "nicht_verbaut" 1 "nicht_verfügbar (Fehler oder Init)" 2 "nicht_gesteckt" 3 "gesteckt" ;
VAL_ 1312 AB_Gurtschloss_Reihe2_BF 0 "nicht_verbaut" 1 "nicht_verfügbar (Fehler oder Init)" 2 "nicht_gesteckt" 3 "gesteckt" ;
VAL_ 1312 AB_Gurtschloss_Reihe3_FA 0 "nicht_verbaut" 1 "nicht_verfügbar (Fehler oder Init)" 2 "nicht_gesteckt" 3 "gesteckt" ;
VAL_ 1312 AB_Gurtschloss_Reihe3_MI 0 "nicht_verbaut" 1 "nicht_verfügbar (Fehler oder Init)" 2 "nicht_gesteckt" 3 "gesteckt" ;
VAL_ 1312 AB_Gurtschloss_Reihe3_BF 0 "nicht_verbaut" 1 "nicht_verfügbar (Fehler oder Init)" 2 "nicht_gesteckt" 3 "gesteckt" ;
VAL_ 1312 AB_Sitzpos_Sens_FA 0 "nicht verfügbar" 1 "Fehler" 2 "Sitz nicht vorne" 3 "Sitz vorne" ;
VAL_ 1312 AB_Sitzpos_Sens_BF 0 "nicht verfügbar" 1 "Fehler" 2 "Sitz nicht vorne" 3 "Sitz vorne" ;
VAL_ 1312 AB_Trefferlage 0 "kein_Ereignis" 1 "Front_Fahrer" 2 "Front_Mitte" 3 "Front_Beifahrer" 4 "Seite_Fahrer" 5 "Seite_Beifahrer" 6 "Heck_Fahrer" 7 "Heck_Mitte" 8 "Heck_Beifahrer" 9 "FGS" 10 "Rollover" 11 "Mehrfachereignis_Front" 12 "Mehrfachereignis_Seite_Fahrer" 13 "Mehrfachereignis_Seite_Beifahrer" 14 "Mehrfachereignis_Heck" 15 "keine_Zuordnung_Fehler" ;
VAL_ 65 AB_MKB_Safing 0 "Multikollisionsbremsung_nicht_bestaetigt" 1 "Multikollisionsbremsung_bestaetigt" ;
VAL_ 1633 AAG_AVS_Fehler_02_inv 0 "Fehler" 1 "kein_Fehler" ;
VAL_ 1633 AAG_Bremsl_durch_ECD 0 "Bremslicht_ist_aus" 1 "Bremslicht_durch_ECD_aktiv" ;
VAL_ 1633 AAG_Anhaenger_abgesteckt 1 "Anhaenger_wurde_bei_KL15_aus_abgesteckt" ;
VAL_ 1633 AAG_NSL_aktiv 1 "Anhaenger_Nebelschusslicht_aktiv" ;
VAL_ 1633 AAG_Anhaenger_erkannt 0 "kein_Anhaenger_erkannt" 1 "AAG_Anhaenger_erkannt" ;
VAL_ 1633 AAG_Blinker_H_aktiv 1 "Anhaenger_Blinker_aktiv" ;
VAL_ 1633 AAG_Blinker_HL_def 1 "Anhaenger_Blinker_links_defekt" ;
VAL_ 1633 AAG_Blinker_HR_def 1 "Anhaenger_Blinker_rechts_defekt" ;
VAL_ 1633 AAG_Bremslicht_H_def 1 "Anhaenger_Bremslicht_defekt" ;
VAL_ 1633 AAG_Schlusslicht_HL_def 1 "Anhaenger_Schlusslicht_links_defekt" ;
VAL_ 1633 AAG_Schlusslicht_HR_def 1 "Anhaenger_Schlusslicht_rechts_defekt" ;
VAL_ 1633 AAG_KD_Fehler 0 "kein_KD_Fehler" 1 "KD_Fehler" ;
VAL_ 1633 AAG_AVS_Fehler 0 "iO" 1 "niO" 2 "niO_Fahrzeugstopp_erforderlich" 3 "tbd" ;
VAL_ 1633 AAG_AVS_Stati 0 "endlage eingefahren erreicht" 1 "endlage ausgefahren erreicht" 2 "ausfahren automatik " 3 "einfahren automatik" 4 "ausfahren manuell " 5 "einfahren manuell" 6 "zwischenposition" 7 "nicht initialisiert" ;
VAL_ 1409 BCM_FH_Freigabe 1 "Funktionsfreigabe Fensterheber" ;
VAL_ 1409 BCM_Komfortfkt_Freigabe 0 "Komfortfunktion gesperrt" 1 "globale Freigabe der Komfortfunktion erteilt" ;
VAL_ 1409 BCM_HSK_Freigabe 0 "erlauben" 1 "sperren" ;
VAL_ 1409 BCM_Verdeck_Freigabe 0 "Verdeckbetrieb nicht erlaubt" 1 "Verdeckbetrieb erlaubt" ;
VAL_ 1409 BCM2_Status_Timer_KL15_Abschalt 0 "Anforderung_nicht_aktiv" 1 "Anforderung_aktiv" ;
VAL_ 1409 BCM2_Anford_AbschaltfreigabeKL15 0 "Anforderung_nicht_aktiv" 1 "Anforderung_aktiv" ;
VAL_ 1409 BCM2_Unterdr_Zuendungsmeldung 0 "keine_Unterdr_der_Zuendungsmeldung" 1 "Unterdr_der_Zuendungsmeldung_aktiv" ;
VAL_ 1409 BCM2_KL15_Absch_FT 0 "Zuendung_wurde_bei_Verl_nicht_deaktiviert" 1 "Zuendung_wurde_bei_Verl_deaktiviert" ;
VAL_ 1409 ZV_ist_Zustand_verfuegbar 0 "nicht_verfuegbar" 1 "verfuegbar_alle_TSGs_am_Bus" ;
VAL_ 1409 BCM2_P_verriegelt 0 "WH nicht in Stellung P" 1 "WH in Stellung P" ;
VAL_ 1409 ZV_verriegelt_intern_ist 1 "Fahrzeug innen verriegelt; Istzustand" ;
VAL_ 1409 ZV_verriegelt_extern_ist 1 "Fahrzeug_aussen_verriegelt_Istzustand" ;
VAL_ 1409 ZV_verriegelt_intern_soll 1 "Fahrzeug verriegelt intern; Sollzusstand" ;
VAL_ 1409 ZV_verriegelt_extern_soll 1 "Fahrzeug verriegelt extern; Sollzusstand" ;
VAL_ 1409 ZV_gesafet_extern_ist 1 "Fahrzeug aussen gesafet; Istzustand" ;
VAL_ 1409 ZV_gesafet_extern_soll 1 "Fahrzeug_aussen_gesafet_Sollzustand" ;
VAL_ 1409 ZV_FT_offen 1 "FT_geoeffnet" ;
VAL_ 1409 ZV_BT_offen 1 "BT_geoeffnet" ;
VAL_ 1409 ZV_HL_offen 1 "Tuer_HL_geoeffnet" ;
VAL_ 1409 ZV_HR_offen 1 "Tuer_HR_geoeffnet" ;
VAL_ 1409 ZV_HD_offen 1 "Heckdeckel_auf" ;
VAL_ 1409 ZV_Turen_HD_zu 1 "Türen und HD geschlossen" ;
VAL_ 1409 ZV_Einzeltuerentriegelung 1 "Fahrzeug an Einzeltuer entriegelt" ;
VAL_ 1409 ZV_Heckeinzelentriegelung 1 "Heckdeckeleinzelentriegelung" ;
VAL_ 1409 BCM_ValetTaster_Fkts_LED 0 "LED_aus" 1 "LED_ein" ;
VAL_ 1409 BCM_HHS_aktiv 1 "Heizbare Heckscheibe aktiv" ;
VAL_ 1409 BCM_Spg_Hzg_Ein 0 "Spiegelheizung nicht einschalten" 1 "Spiegelheizung einschalten (wenn Heckscheiben Heizung eingeschaltet wurde)" ;
VAL_ 1409 ZV_HS_offen 0 "Heckscheibe_geschlossen" 1 "Heckscheibe auf" ;
VAL_ 1409 ZZH_Endlage_oben 0 "ZZH_nicht_in_oberer_Endlage" 1 "ZZH in Endlage oben" ;
VAL_ 1409 ZZH_Endlage_unten 0 "ZZH_nicht_in_unterer_Endlage" 1 "ZZH in Endlage unten" ;
VAL_ 1409 ZZH_Endlage_unplausibel 0 "Endlage_ZZH_plausibel" 1 "unplausible Endlage der ZZH erkannt" ;
VAL_ 1409 BCM2_KD_Fehler 0 "kein_KD_Fehler" 1 "KD_Fehler" ;
VAL_ 1409 NGS_aktiv 0 "Neigungssensor unscharf" 1 "Neigungssensor scharf" ;
VAL_ 1409 IRUE_aktiv 0 "unscharf" 1 "scharf" ;
VAL_ 1409 DWA_aktiv 0 "unscharf" 1 "scharf" ;
VAL_ 1409 Komp_Schutz_aktiv 0 "Komponentenschutz nicht aktiv" 1 "Komponentenschutz aktiv" ;
VAL_ 1409 NGS_Taster_Fkts_LED 0 "LED_aus" 1 "LED_ein" ;
VAL_ 1409 IRUE_Taster_Fkts_LED 0 "LED_aus" 1 "LED_ein" ;
VAL_ 1409 HD_Drehfalle_S1 0 "Drehfalle geschlossen" 1 "Drehfalle offen" ;
VAL_ 1409 HD_Sperrklinke_S2 0 "Sperrklinke geschlossen" 1 "Sperrklinke offen" ;
VAL_ 1409 BCM_Verbau_Heckrollo 0 "Heckrollo nicht verbaut" 1 "Heckrollo verbaut" ;
VAL_ 1409 BCM2_EZS_gedrueckt 1 "EZS gedrueckt" ;
VAL_ 1409 BCM2_SST_gedrueckt 1 "SST gedrueckt" ;
VAL_ 1409 LIM_alt 0 "aktuell" 1 "veraltet" ;
VAL_ 1409 LIM_Innenbeleuchtung_V_aktiv 0 "vordere Innenlichter und vordere Leselichter sind alle aus" 1 "min. ein vorderes Innenlicht oder ein vorderes Leselicht ist an" ;
VAL_ 1409 LIM_Innenbeleuchtung_aktiv 0 "saemtliche Innenlichter, Leselichter, Rollolichter und Ambientelichter sind aus" 1 "min. ein Innenlicht, Leselicht oder Ambientelicht ist an" ;
VAL_ 1409 LIM_Taster_Rollolicht_hl 0 "nicht_betaetigt" 1 "betaetigt" ;
VAL_ 1409 LIM_Taster_Rollolicht_hr 0 "nicht_betaetigt" 1 "betaetigt" ;
VAL_ 1409 BCM_Sperrklinke_FT 0 "Schalter_geschlossen_Tuer_offen" 1 "Schalter_offen_Tuer_geschlossen" ;
VAL_ 1409 LIM_Taster_Rollolicht_V 0 "nicht_betaetigt" 1 "betaetigt" ;
VAL_ 1409 BCM_Tankwunsch 0 "Fehler_keine_Drucktankfunktionalitaet" 1 "keine_Betankung_erwuenscht" 2 "Betankung_erwuenscht" ;
VAL_ 1409 ZV_Tankklappe_offen 0 "Tankklappe_geschlossen" 1 "Tankklappe_offen" ;
VAL_ 1409 BCM_Tankklappensteller_Fehler 0 "kein_Fehler" 1 "Fehler" ;
VAL_ 1409 KST_Warn_P1_ZST_def 0 "nicht_defekt" 1 "defekt" ;
VAL_ 1409 KST_Warn_P2_ZST_def 0 "nicht_defekt" 1 "defekt" ;
VAL_ 777 BEM_Segel_Info 0 "keine_Anforderung" 1 "Mindestdrehzahl_1" 2 "Mindestdrehzahl_2" 3 "Segelveto" ;
VAL_ 777 BEM_P_Generator 255 "Fehler" ;
VAL_ 777 BEM_n_LLA 0 "keine_Erhoehung" 1 "Stufe_1" 2 "Stufe_2" 3 "Stufe_3" ;
VAL_ 777 BEM_01_Abschaltstufen 0 "Stufe_0_keine_Einschraenkung" 1 "Stufe_1" 2 "Stufe_2" 3 "Stufe_3" 4 "Transportmodus" 7 "Ruhestrommessmodus" ;
VAL_ 777 BEM_Anf_KL 0 "keine Anforderung" 1 "Anforderung Kühlerlüfter Ansteuerung" ;
VAL_ 777 BEM_StartStopp_Info 0 "Motorlauf_nicht_notwendig_(Stoppfreigabe)" 1 "Motoranlauf_nicht_zwingend_notwendig_(Stoppverbot,keine_Startanforderung)" 2 "Motoranlauf_zwingend_notwendig_(Startanforderung)" 3 "Systemfehler" ;
VAL_ 1635 BEM_02_Abschaltstufen 0 "Stufe 0 (keine Einschraenkungen)" 1 "Stufe 1" 2 "Stufe 2" 3 "Stufe 3" 4 "Transportmodus" 7 "Ruhestrommessmodus" ;
VAL_ 1635 BEM_STH_Zielzeit 15 "Fehler" ;
VAL_ 1635 BEM_MMI_Vorwarnung 0 "keine Anzeige" 1 "Anzeige MMI-Vorwarnung" ;
VAL_ 1635 NVEM_Anf_SD_schalten 0 "Anf_SD_Nachlauf_nicht_aktiv" 1 "Anf_SD_Nachlauf_aktiv" ;
VAL_ 1635 BEM_Generatordiagnose 0 "keine Anzeige" 1 "Ladekontrollanzeige ein (Vorhalt)" 2 "rotes Batteriesymbol und Text (Generator defekt)" 3 "Hybrid_DCDC_Wandler_defekt" ;
VAL_ 1635 BEM_Red_Innengeblaese 0 "keine Reduzierung" 1 "Reduzierung Stufe 1" 2 "Reduzierung Stufe 2" 3 "Reduzierung Stufe 2 und Abschaltung Kompressor" ;
VAL_ 1635 BEM_STH_Einschaltverbot 0 "volle Verfuegbarkeit Standheizung/-lueftung" 1 "Standheizung/-lueftung nicht aktivierbar" ;
VAL_ 1635 BEM_HL_Regelung_Status 0 "HL_Regelung_inaktiv_(vor_und_waehrend_Motorstart)" 1 "HL_Regelung_Stufe_1" 2 "HL_Regelung_Stufe_2" 3 "HL_Regelung_Stufe_3" 4 "Verbrauchernotabschaltung_(VNA)" 5 "HL_Regelung_Stufe_5" 7 "Default" ;
VAL_ 1635 BEM_Ladezustand 14 "Init" 15 "Fehler" ;
VAL_ 1635 BEM_Batteriediagnose 0 "keine_Anzeige" 1 "nicht_belegt" 2 "Anzeige_aberkannte_Batterie_(Vorhalt)" 3 "Batteriesymbol_ggf_gelb_und_Text_schwache_Batterie" 4 "Batteriesymbol_ggf_grün_und_Text_Batterie_OK(nur im Transport)" 5 "Batteriesymbol_ggf_gelb_und_Text_Batterie_Laden (nur im Transport)" 6 "Batteriesymbol_ggf_rot_und_Text_Batterie_Prüfen (nur im Transport)" 7 "nicht_belegt" ;
VAL_ 1635 MIB_Stromsparmodus 0 "inaktiv" 1 "aktiv" ;
VAL_ 1635 BEM_REK_aktiv 0 "keine_Rekuperationsfreigabe" 1 "Rekuperationsfreigabe" ;
VAL_ 1635 BEM_EMLIN_ungueltig 0 "Signale_gueltig" 1 "Signale_ungueltig" ;
VAL_ 1635 BEM_Batt_Ab 0 "verbunden" 1 "nicht_verbunden" ;
VAL_ 1635 BEM_UBDM 255 "Fehler" ;
VAL_ 1635 BEM_Anf_KL15_schalten 0 "Keine_Einschraenkung_Kl15" 1 "Empfehlung_auto_Abschaltung_Kl15" 2 "Veto_auto_Abschaltung_Kl15" 3 "Veto_auto_Abschaltung_Fahrtbetrieb" ;
VAL_ 946 BEM_HYB_DC_uMinLV 254 "Init" 255 "Fehler" ;
VAL_ 946 BEM_Freigabe_HV_Ladung 0 "HV_Ladung_nicht_freigegeben" 1 "HV_Ladung_freigegeben" ;
VAL_ 946 BEM_Hybrid_Info 0 "keine_Einschraenkung_durch_Energiemanagement" 1 "Motorstart_ueber_12V_Starter_nur_bei_0kmh_moeglich" 2 "kein_Motorstart_ueber_12V_Starter_nach_el_Fahrtbetrieb" 3 "Systemfehler" ;
VAL_ 946 BEM_NV_NachladAnf 0 "keine_Anforderung" 1 "Anforderung_NV_Nachladung" 2 "Init" 3 "Fehler" ;
VAL_ 1628 BMS_HYB_ASV_hinten_Status 0 "Ventil_offen" 1 "Ventil_geschlossen" ;
VAL_ 1628 BMS_HYB_ASV_vorne_Status 0 "Ventil_offen" 1 "Ventil_geschlossen" ;
VAL_ 1628 BMS_HYB_KD_Fehler 0 "kein_KD_Fehler" 1 "KD_Fehler" ;
VAL_ 1628 BMS_HYB_BattFanSpd 14 "Init" 15 "Fehler" ;
VAL_ 1628 BMS_HYB_VentilationReq 1 "Ventilation_Request" ;
VAL_ 1628 BMS_HYB_Spuelbetrieb_Status 0 "Umluftbetrieb" 1 "Spuelbetrieb" ;
VAL_ 1628 BMS_HYB_Kuehlung_Anf 0 "keine_Kuehlanforderung" 1 "aktive_Kuehlung_Stufe_1" 2 "aktive_Kuehlung_Stufe_2" 3 "Kuehlung_max" ;
VAL_ 1628 BMS_HYB_Temp_vor_Verd 254 "Init" 255 "Fehler" ;
VAL_ 1628 BMS_HYB_Temp_nach_Verd 254 "Init" 255 "Fehler" ;
VAL_ 1628 BMS_Temperatur 254 "Init" 255 "Fehler" ;
VAL_ 1628 BMS_Temperatur_Ansaugluft 254 "Init" 255 "Fehler" ;
VAL_ 1628 BMS_IstSpannung_HV 254 "Init" 255 "Fehler" ;
